VERSION ""

NS_ :

BS_:

BU_: FBD_HL IPB_App1 FBD_HM FBD_HR FBD_Miko FBD_MM FBD_Trunk FBD_VL FBD_VM FBD_VR Diagnosetool_CAN_FD_IPB_41

BO_ 651 StatusBLEDeviceNameFBD_HM: 32 FBD_HM
 SG_ StatusBLEDeviceNameFBD_HM_Charac : 0|8@1+ (1.0,0) [0|252] "" IPB_App1
 SG_ StatusBLEDeviceNameFBD_HM_Char_2 : 8|8@1+ (1.0,0) [0|252] "" IPB_App1
 SG_ StatusBLEDeviceNameFBD_HM_Char_3 : 16|8@1+ (1.0,0) [0|252] "" IPB_App1
 SG_ StatusBLEDeviceNameFBD_HM_Char_4 : 24|8@1+ (1.0,0) [0|252] "" IPB_App1
 SG_ StatusBLEDeviceNameFBD_HM_Char_5 : 32|8@1+ (1.0,0) [0|252] "" IPB_App1
 SG_ StatusBLEDeviceNameFBD_HM_Char_6 : 40|8@1+ (1.0,0) [0|252] "" IPB_App1
 SG_ StatusBLEDeviceNameFBD_HM_Char_7 : 48|8@1+ (1.0,0) [0|252] "" IPB_App1
 SG_ StatusBLEDeviceNameFBD_HM_Char_8 : 56|8@1+ (1.0,0) [0|252] "" IPB_App1
 SG_ StatusBLEDeviceNameFBD_HM_Char_9 : 64|8@1+ (1.0,0) [0|252] "" IPB_App1
 SG_ StatusBLEDeviceNameFBD_HM_Cha_10 : 72|8@1+ (1.0,0) [0|252] "" IPB_App1
 SG_ StatusBLEDeviceNameFBD_HM_Cha_11 : 80|8@1+ (1.0,0) [0|252] "" IPB_App1
 SG_ StatusBLEDeviceNameFBD_HM_Cha_12 : 88|8@1+ (1.0,0) [0|252] "" IPB_App1
 SG_ StatusBLEDeviceNameFBD_HM_Cha_13 : 96|8@1+ (1.0,0) [0|252] "" IPB_App1
 SG_ StatusBLEDeviceNameFBD_HM_Cha_14 : 104|8@1+ (1.0,0) [0|252] "" IPB_App1
 SG_ StatusBLEDeviceNameFBD_HM_Cha_15 : 112|8@1+ (1.0,0) [0|252] "" IPB_App1
 SG_ StatusBLEDeviceNameFBD_HM_Cha_16 : 120|8@1+ (1.0,0) [0|252] "" IPB_App1
 SG_ StatusBLEDeviceNameFBD_HM_Cha_17 : 128|8@1+ (1.0,0) [0|252] "" IPB_App1
 SG_ StatusBLEDeviceNameFBD_HM_Cha_18 : 136|8@1+ (1.0,0) [0|252] "" IPB_App1
 SG_ StatusBLEDeviceNameFBD_HM_Cha_19 : 144|8@1+ (1.0,0) [0|252] "" IPB_App1
 SG_ StatusBLEDeviceNameFBD_HM_Cha_20 : 152|8@1+ (1.0,0) [0|252] "" IPB_App1
 SG_ StatusBLEDeviceNameFBD_HM_Cha_21 : 160|8@1+ (1.0,0) [0|252] "" IPB_App1
 SG_ StatusBLEDeviceNameFBD_HM_Cha_22 : 168|8@1+ (1.0,0) [0|252] "" IPB_App1
 SG_ StatusBLEDeviceNameFBD_HM_Cha_23 : 176|8@1+ (1.0,0) [0|252] "" IPB_App1
 SG_ StatusBLEDeviceNameFBD_HM_Cha_24 : 184|8@1+ (1.0,0) [0|252] "" IPB_App1
 SG_ StatusBLEDeviceNameFBD_HM_Cha_25 : 192|8@1+ (1.0,0) [0|252] "" IPB_App1
 SG_ StatusBLEDeviceNameFBD_HM_Cha_26 : 200|8@1+ (1.0,0) [0|252] "" IPB_App1
 SG_ StatusBLEDeviceNameFBD_HM_Cha_27 : 208|8@1+ (1.0,0) [0|252] "" IPB_App1
 SG_ StatusBLEDeviceNameFBD_HM_Cha_28 : 216|8@1+ (1.0,0) [0|252] "" IPB_App1
 SG_ StatusBLEDeviceNameFBD_HM_Cha_29 : 224|8@1+ (1.0,0) [0|252] "" IPB_App1
 SG_ StatusBLEDeviceNameFBD_HM_Cha_30 : 232|8@1+ (1.0,0) [0|252] "" IPB_App1

BO_ 657 StatusBLEDeviceNameFBD_HR: 32 FBD_HR
 SG_ StatusBLEDeviceNameFBD_HR_Charac : 0|8@1+ (1.0,0) [0|252] "" IPB_App1
 SG_ StatusBLEDeviceNameFBD_HR_Char_2 : 8|8@1+ (1.0,0) [0|252] "" IPB_App1
 SG_ StatusBLEDeviceNameFBD_HR_Char_3 : 16|8@1+ (1.0,0) [0|252] "" IPB_App1
 SG_ StatusBLEDeviceNameFBD_HR_Char_4 : 24|8@1+ (1.0,0) [0|252] "" IPB_App1
 SG_ StatusBLEDeviceNameFBD_HR_Char_5 : 32|8@1+ (1.0,0) [0|252] "" IPB_App1
 SG_ StatusBLEDeviceNameFBD_HR_Char_6 : 40|8@1+ (1.0,0) [0|252] "" IPB_App1
 SG_ StatusBLEDeviceNameFBD_HR_Char_7 : 48|8@1+ (1.0,0) [0|252] "" IPB_App1
 SG_ StatusBLEDeviceNameFBD_HR_Char_8 : 56|8@1+ (1.0,0) [0|252] "" IPB_App1
 SG_ StatusBLEDeviceNameFBD_HR_Char_9 : 64|8@1+ (1.0,0) [0|252] "" IPB_App1
 SG_ StatusBLEDeviceNameFBD_HR_Cha_10 : 72|8@1+ (1.0,0) [0|252] "" IPB_App1
 SG_ StatusBLEDeviceNameFBD_HR_Cha_11 : 80|8@1+ (1.0,0) [0|252] "" IPB_App1
 SG_ StatusBLEDeviceNameFBD_HR_Cha_12 : 88|8@1+ (1.0,0) [0|252] "" IPB_App1
 SG_ StatusBLEDeviceNameFBD_HR_Cha_13 : 96|8@1+ (1.0,0) [0|252] "" IPB_App1
 SG_ StatusBLEDeviceNameFBD_HR_Cha_14 : 104|8@1+ (1.0,0) [0|252] "" IPB_App1
 SG_ StatusBLEDeviceNameFBD_HR_Cha_15 : 112|8@1+ (1.0,0) [0|252] "" IPB_App1
 SG_ StatusBLEDeviceNameFBD_HR_Cha_16 : 120|8@1+ (1.0,0) [0|252] "" IPB_App1
 SG_ StatusBLEDeviceNameFBD_HR_Cha_17 : 128|8@1+ (1.0,0) [0|252] "" IPB_App1
 SG_ StatusBLEDeviceNameFBD_HR_Cha_18 : 136|8@1+ (1.0,0) [0|252] "" IPB_App1
 SG_ StatusBLEDeviceNameFBD_HR_Cha_19 : 144|8@1+ (1.0,0) [0|252] "" IPB_App1
 SG_ StatusBLEDeviceNameFBD_HR_Cha_20 : 152|8@1+ (1.0,0) [0|252] "" IPB_App1
 SG_ StatusBLEDeviceNameFBD_HR_Cha_21 : 160|8@1+ (1.0,0) [0|252] "" IPB_App1
 SG_ StatusBLEDeviceNameFBD_HR_Cha_22 : 168|8@1+ (1.0,0) [0|252] "" IPB_App1
 SG_ StatusBLEDeviceNameFBD_HR_Cha_23 : 176|8@1+ (1.0,0) [0|252] "" IPB_App1
 SG_ StatusBLEDeviceNameFBD_HR_Cha_24 : 184|8@1+ (1.0,0) [0|252] "" IPB_App1
 SG_ StatusBLEDeviceNameFBD_HR_Cha_25 : 192|8@1+ (1.0,0) [0|252] "" IPB_App1
 SG_ StatusBLEDeviceNameFBD_HR_Cha_26 : 200|8@1+ (1.0,0) [0|252] "" IPB_App1
 SG_ StatusBLEDeviceNameFBD_HR_Cha_27 : 208|8@1+ (1.0,0) [0|252] "" IPB_App1
 SG_ StatusBLEDeviceNameFBD_HR_Cha_28 : 216|8@1+ (1.0,0) [0|252] "" IPB_App1
 SG_ StatusBLEDeviceNameFBD_HR_Cha_29 : 224|8@1+ (1.0,0) [0|252] "" IPB_App1
 SG_ StatusBLEDeviceNameFBD_HR_Cha_30 : 232|8@1+ (1.0,0) [0|252] "" IPB_App1

BO_ 652 StatusBLEDeviceNameFBD_Miko: 32 FBD_Miko
 SG_ StatusBLEDeviceNameFBD_Miko_Char : 0|8@1+ (1.0,0) [0|252] "" IPB_App1
 SG_ StatusBLEDeviceNameFBD_Miko_Ch_2 : 8|8@1+ (1.0,0) [0|252] "" IPB_App1
 SG_ StatusBLEDeviceNameFBD_Miko_Ch_3 : 16|8@1+ (1.0,0) [0|252] "" IPB_App1
 SG_ StatusBLEDeviceNameFBD_Miko_Ch_4 : 24|8@1+ (1.0,0) [0|252] "" IPB_App1
 SG_ StatusBLEDeviceNameFBD_Miko_Ch_5 : 32|8@1+ (1.0,0) [0|252] "" IPB_App1
 SG_ StatusBLEDeviceNameFBD_Miko_Ch_6 : 40|8@1+ (1.0,0) [0|252] "" IPB_App1
 SG_ StatusBLEDeviceNameFBD_Miko_Ch_7 : 48|8@1+ (1.0,0) [0|252] "" IPB_App1
 SG_ StatusBLEDeviceNameFBD_Miko_Ch_8 : 56|8@1+ (1.0,0) [0|252] "" IPB_App1
 SG_ StatusBLEDeviceNameFBD_Miko_Ch_9 : 64|8@1+ (1.0,0) [0|252] "" IPB_App1
 SG_ StatusBLEDeviceNameFBD_Miko_C_10 : 72|8@1+ (1.0,0) [0|252] "" IPB_App1
 SG_ StatusBLEDeviceNameFBD_Miko_C_11 : 80|8@1+ (1.0,0) [0|252] "" IPB_App1
 SG_ StatusBLEDeviceNameFBD_Miko_C_12 : 88|8@1+ (1.0,0) [0|252] "" IPB_App1
 SG_ StatusBLEDeviceNameFBD_Miko_C_13 : 96|8@1+ (1.0,0) [0|252] "" IPB_App1
 SG_ StatusBLEDeviceNameFBD_Miko_C_14 : 104|8@1+ (1.0,0) [0|252] "" IPB_App1
 SG_ StatusBLEDeviceNameFBD_Miko_C_15 : 112|8@1+ (1.0,0) [0|252] "" IPB_App1
 SG_ StatusBLEDeviceNameFBD_Miko_C_16 : 120|8@1+ (1.0,0) [0|252] "" IPB_App1
 SG_ StatusBLEDeviceNameFBD_Miko_C_17 : 128|8@1+ (1.0,0) [0|252] "" IPB_App1
 SG_ StatusBLEDeviceNameFBD_Miko_C_18 : 136|8@1+ (1.0,0) [0|252] "" IPB_App1
 SG_ StatusBLEDeviceNameFBD_Miko_C_19 : 144|8@1+ (1.0,0) [0|252] "" IPB_App1
 SG_ StatusBLEDeviceNameFBD_Miko_C_20 : 152|8@1+ (1.0,0) [0|252] "" IPB_App1
 SG_ StatusBLEDeviceNameFBD_Miko_C_21 : 160|8@1+ (1.0,0) [0|252] "" IPB_App1
 SG_ StatusBLEDeviceNameFBD_Miko_C_22 : 168|8@1+ (1.0,0) [0|252] "" IPB_App1
 SG_ StatusBLEDeviceNameFBD_Miko_C_23 : 176|8@1+ (1.0,0) [0|252] "" IPB_App1
 SG_ StatusBLEDeviceNameFBD_Miko_C_24 : 184|8@1+ (1.0,0) [0|252] "" IPB_App1
 SG_ StatusBLEDeviceNameFBD_Miko_C_25 : 192|8@1+ (1.0,0) [0|252] "" IPB_App1
 SG_ StatusBLEDeviceNameFBD_Miko_C_26 : 200|8@1+ (1.0,0) [0|252] "" IPB_App1
 SG_ StatusBLEDeviceNameFBD_Miko_C_27 : 208|8@1+ (1.0,0) [0|252] "" IPB_App1
 SG_ StatusBLEDeviceNameFBD_Miko_C_28 : 216|8@1+ (1.0,0) [0|252] "" IPB_App1
 SG_ StatusBLEDeviceNameFBD_Miko_C_29 : 224|8@1+ (1.0,0) [0|252] "" IPB_App1
 SG_ StatusBLEDeviceNameFBD_Miko_C_30 : 232|8@1+ (1.0,0) [0|252] "" IPB_App1

BO_ 660 StatusBLEDeviceNameFBD_MM: 32 FBD_MM
 SG_ StatusBLEDeviceNameFBD_MM_Addres : 0|16@1+ (1,0) [0|0] "" IPB_App1
 SG_ StatusBLEDeviceNameFBD_MM_Charac : 16|8@1+ (1.0,0) [0|252] "" IPB_App1
 SG_ StatusBLEDeviceNameFBD_MM_Char_2 : 24|8@1+ (1.0,0) [0|252] "" IPB_App1
 SG_ StatusBLEDeviceNameFBD_MM_Char_3 : 32|8@1+ (1.0,0) [0|252] "" IPB_App1
 SG_ StatusBLEDeviceNameFBD_MM_Char_4 : 40|8@1+ (1.0,0) [0|252] "" IPB_App1
 SG_ StatusBLEDeviceNameFBD_MM_Char_5 : 48|8@1+ (1.0,0) [0|252] "" IPB_App1
 SG_ StatusBLEDeviceNameFBD_MM_Char_6 : 56|8@1+ (1.0,0) [0|252] "" IPB_App1
 SG_ StatusBLEDeviceNameFBD_MM_Char_7 : 64|8@1+ (1.0,0) [0|252] "" IPB_App1
 SG_ StatusBLEDeviceNameFBD_MM_Char_8 : 72|8@1+ (1.0,0) [0|252] "" IPB_App1
 SG_ StatusBLEDeviceNameFBD_MM_Char_9 : 80|8@1+ (1.0,0) [0|252] "" IPB_App1
 SG_ StatusBLEDeviceNameFBD_MM_Cha_10 : 88|8@1+ (1.0,0) [0|252] "" IPB_App1
 SG_ StatusBLEDeviceNameFBD_MM_Cha_11 : 96|8@1+ (1.0,0) [0|252] "" IPB_App1
 SG_ StatusBLEDeviceNameFBD_MM_Cha_12 : 104|8@1+ (1.0,0) [0|252] "" IPB_App1
 SG_ StatusBLEDeviceNameFBD_MM_Cha_13 : 112|8@1+ (1.0,0) [0|252] "" IPB_App1
 SG_ StatusBLEDeviceNameFBD_MM_Cha_14 : 120|8@1+ (1.0,0) [0|252] "" IPB_App1
 SG_ StatusBLEDeviceNameFBD_MM_Cha_15 : 128|8@1+ (1.0,0) [0|252] "" IPB_App1
 SG_ StatusBLEDeviceNameFBD_MM_Cha_16 : 136|8@1+ (1.0,0) [0|252] "" IPB_App1
 SG_ StatusBLEDeviceNameFBD_MM_Cha_17 : 144|8@1+ (1.0,0) [0|252] "" IPB_App1
 SG_ StatusBLEDeviceNameFBD_MM_Cha_18 : 152|8@1+ (1.0,0) [0|252] "" IPB_App1
 SG_ StatusBLEDeviceNameFBD_MM_Cha_19 : 160|8@1+ (1.0,0) [0|252] "" IPB_App1
 SG_ StatusBLEDeviceNameFBD_MM_Cha_20 : 168|8@1+ (1.0,0) [0|252] "" IPB_App1
 SG_ StatusBLEDeviceNameFBD_MM_Cha_21 : 176|8@1+ (1.0,0) [0|252] "" IPB_App1
 SG_ StatusBLEDeviceNameFBD_MM_Cha_22 : 184|8@1+ (1.0,0) [0|252] "" IPB_App1
 SG_ StatusBLEDeviceNameFBD_MM_Cha_23 : 192|8@1+ (1.0,0) [0|252] "" IPB_App1
 SG_ StatusBLEDeviceNameFBD_MM_Cha_24 : 200|8@1+ (1.0,0) [0|252] "" IPB_App1
 SG_ StatusBLEDeviceNameFBD_MM_Cha_25 : 208|8@1+ (1.0,0) [0|252] "" IPB_App1
 SG_ StatusBLEDeviceNameFBD_MM_Cha_26 : 216|8@1+ (1.0,0) [0|252] "" IPB_App1
 SG_ StatusBLEDeviceNameFBD_MM_Cha_27 : 224|8@1+ (1.0,0) [0|252] "" IPB_App1
 SG_ StatusBLEDeviceNameFBD_MM_Cha_28 : 232|8@1+ (1.0,0) [0|252] "" IPB_App1
 SG_ StatusBLEDeviceNameFBD_MM_Cha_29 : 240|8@1+ (1.0,0) [0|252] "" IPB_App1
 SG_ StatusBLEDeviceNameFBD_MM_Cha_30 : 248|8@1+ (1.0,0) [0|252] "" IPB_App1

BO_ 653 StatusBLEDeviceNameFBD_Trunk: 32 FBD_Trunk
 SG_ StatusBLEDeviceNameFBD_Trunk_Cha : 0|8@1+ (1.0,0) [0|252] "" IPB_App1
 SG_ StatusBLEDeviceNameFBD_Trunk_C_2 : 8|8@1+ (1.0,0) [0|252] "" IPB_App1
 SG_ StatusBLEDeviceNameFBD_Trunk_C_3 : 16|8@1+ (1.0,0) [0|252] "" IPB_App1
 SG_ StatusBLEDeviceNameFBD_Trunk_C_4 : 24|8@1+ (1.0,0) [0|252] "" IPB_App1
 SG_ StatusBLEDeviceNameFBD_Trunk_C_5 : 32|8@1+ (1.0,0) [0|252] "" IPB_App1
 SG_ StatusBLEDeviceNameFBD_Trunk_C_6 : 40|8@1+ (1.0,0) [0|252] "" IPB_App1
 SG_ StatusBLEDeviceNameFBD_Trunk_C_7 : 48|8@1+ (1.0,0) [0|252] "" IPB_App1
 SG_ StatusBLEDeviceNameFBD_Trunk_C_8 : 56|8@1+ (1.0,0) [0|252] "" IPB_App1
 SG_ StatusBLEDeviceNameFBD_Trunk_C_9 : 64|8@1+ (1.0,0) [0|252] "" IPB_App1
 SG_ StatusBLEDeviceNameFBD_Trunk__10 : 72|8@1+ (1.0,0) [0|252] "" IPB_App1
 SG_ StatusBLEDeviceNameFBD_Trunk__11 : 80|8@1+ (1.0,0) [0|252] "" IPB_App1
 SG_ StatusBLEDeviceNameFBD_Trunk__12 : 88|8@1+ (1.0,0) [0|252] "" IPB_App1
 SG_ StatusBLEDeviceNameFBD_Trunk__13 : 96|8@1+ (1.0,0) [0|252] "" IPB_App1
 SG_ StatusBLEDeviceNameFBD_Trunk__14 : 104|8@1+ (1.0,0) [0|252] "" IPB_App1
 SG_ StatusBLEDeviceNameFBD_Trunk__15 : 112|8@1+ (1.0,0) [0|252] "" IPB_App1
 SG_ StatusBLEDeviceNameFBD_Trunk__16 : 120|8@1+ (1.0,0) [0|252] "" IPB_App1
 SG_ StatusBLEDeviceNameFBD_Trunk__17 : 128|8@1+ (1.0,0) [0|252] "" IPB_App1
 SG_ StatusBLEDeviceNameFBD_Trunk__18 : 136|8@1+ (1.0,0) [0|252] "" IPB_App1
 SG_ StatusBLEDeviceNameFBD_Trunk__19 : 144|8@1+ (1.0,0) [0|252] "" IPB_App1
 SG_ StatusBLEDeviceNameFBD_Trunk__20 : 152|8@1+ (1.0,0) [0|252] "" IPB_App1
 SG_ StatusBLEDeviceNameFBD_Trunk__21 : 160|8@1+ (1.0,0) [0|252] "" IPB_App1
 SG_ StatusBLEDeviceNameFBD_Trunk__22 : 168|8@1+ (1.0,0) [0|252] "" IPB_App1
 SG_ StatusBLEDeviceNameFBD_Trunk__23 : 176|8@1+ (1.0,0) [0|252] "" IPB_App1
 SG_ StatusBLEDeviceNameFBD_Trunk__24 : 184|8@1+ (1.0,0) [0|252] "" IPB_App1
 SG_ StatusBLEDeviceNameFBD_Trunk__25 : 192|8@1+ (1.0,0) [0|252] "" IPB_App1
 SG_ StatusBLEDeviceNameFBD_Trunk__26 : 200|8@1+ (1.0,0) [0|252] "" IPB_App1
 SG_ StatusBLEDeviceNameFBD_Trunk__27 : 208|8@1+ (1.0,0) [0|252] "" IPB_App1
 SG_ StatusBLEDeviceNameFBD_Trunk__28 : 216|8@1+ (1.0,0) [0|252] "" IPB_App1
 SG_ StatusBLEDeviceNameFBD_Trunk__29 : 224|8@1+ (1.0,0) [0|252] "" IPB_App1
 SG_ StatusBLEDeviceNameFBD_Trunk__30 : 232|8@1+ (1.0,0) [0|252] "" IPB_App1

BO_ 654 StatusBLEDeviceNameFBD_VL: 32 FBD_VL
 SG_ StatusBLEDeviceNameFBD_VL_Charac : 0|8@1+ (1.0,0) [0|252] "" IPB_App1
 SG_ StatusBLEDeviceNameFBD_VL_Char_2 : 8|8@1+ (1.0,0) [0|252] "" IPB_App1
 SG_ StatusBLEDeviceNameFBD_VL_Char_3 : 16|8@1+ (1.0,0) [0|252] "" IPB_App1
 SG_ StatusBLEDeviceNameFBD_VL_Char_4 : 24|8@1+ (1.0,0) [0|252] "" IPB_App1
 SG_ StatusBLEDeviceNameFBD_VL_Char_5 : 32|8@1+ (1.0,0) [0|252] "" IPB_App1
 SG_ StatusBLEDeviceNameFBD_VL_Char_6 : 40|8@1+ (1.0,0) [0|252] "" IPB_App1
 SG_ StatusBLEDeviceNameFBD_VL_Char_7 : 48|8@1+ (1.0,0) [0|252] "" IPB_App1
 SG_ StatusBLEDeviceNameFBD_VL_Char_8 : 56|8@1+ (1.0,0) [0|252] "" IPB_App1
 SG_ StatusBLEDeviceNameFBD_VL_Char_9 : 64|8@1+ (1.0,0) [0|252] "" IPB_App1
 SG_ StatusBLEDeviceNameFBD_VL_Cha_10 : 72|8@1+ (1.0,0) [0|252] "" IPB_App1
 SG_ StatusBLEDeviceNameFBD_VL_Cha_11 : 80|8@1+ (1.0,0) [0|252] "" IPB_App1
 SG_ StatusBLEDeviceNameFBD_VL_Cha_12 : 88|8@1+ (1.0,0) [0|252] "" IPB_App1
 SG_ StatusBLEDeviceNameFBD_VL_Cha_13 : 96|8@1+ (1.0,0) [0|252] "" IPB_App1
 SG_ StatusBLEDeviceNameFBD_VL_Cha_14 : 104|8@1+ (1.0,0) [0|252] "" IPB_App1
 SG_ StatusBLEDeviceNameFBD_VL_Cha_15 : 112|8@1+ (1.0,0) [0|252] "" IPB_App1
 SG_ StatusBLEDeviceNameFBD_VL_Cha_16 : 120|8@1+ (1.0,0) [0|252] "" IPB_App1
 SG_ StatusBLEDeviceNameFBD_VL_Cha_17 : 128|8@1+ (1.0,0) [0|252] "" IPB_App1
 SG_ StatusBLEDeviceNameFBD_VL_Cha_18 : 136|8@1+ (1.0,0) [0|252] "" IPB_App1
 SG_ StatusBLEDeviceNameFBD_VL_Cha_19 : 144|8@1+ (1.0,0) [0|252] "" IPB_App1
 SG_ StatusBLEDeviceNameFBD_VL_Cha_20 : 152|8@1+ (1.0,0) [0|252] "" IPB_App1
 SG_ StatusBLEDeviceNameFBD_VL_Cha_21 : 160|8@1+ (1.0,0) [0|252] "" IPB_App1
 SG_ StatusBLEDeviceNameFBD_VL_Cha_22 : 168|8@1+ (1.0,0) [0|252] "" IPB_App1
 SG_ StatusBLEDeviceNameFBD_VL_Cha_23 : 176|8@1+ (1.0,0) [0|252] "" IPB_App1
 SG_ StatusBLEDeviceNameFBD_VL_Cha_24 : 184|8@1+ (1.0,0) [0|252] "" IPB_App1
 SG_ StatusBLEDeviceNameFBD_VL_Cha_25 : 192|8@1+ (1.0,0) [0|252] "" IPB_App1
 SG_ StatusBLEDeviceNameFBD_VL_Cha_26 : 200|8@1+ (1.0,0) [0|252] "" IPB_App1
 SG_ StatusBLEDeviceNameFBD_VL_Cha_27 : 208|8@1+ (1.0,0) [0|252] "" IPB_App1
 SG_ StatusBLEDeviceNameFBD_VL_Cha_28 : 216|8@1+ (1.0,0) [0|252] "" IPB_App1
 SG_ StatusBLEDeviceNameFBD_VL_Cha_29 : 224|8@1+ (1.0,0) [0|252] "" IPB_App1
 SG_ StatusBLEDeviceNameFBD_VL_Cha_30 : 232|8@1+ (1.0,0) [0|252] "" IPB_App1

BO_ 650 StatusBLEDeviceNameFBD_VM: 32 FBD_VM
 SG_ StatusBLEDeviceNameFBD_VM_Charac : 0|8@1+ (1.0,0) [0|252] "" IPB_App1
 SG_ StatusBLEDeviceNameFBD_VM_Char_2 : 8|8@1+ (1.0,0) [0|252] "" IPB_App1
 SG_ StatusBLEDeviceNameFBD_VM_Char_3 : 16|8@1+ (1.0,0) [0|252] "" IPB_App1
 SG_ StatusBLEDeviceNameFBD_VM_Char_4 : 24|8@1+ (1.0,0) [0|252] "" IPB_App1
 SG_ StatusBLEDeviceNameFBD_VM_Char_5 : 32|8@1+ (1.0,0) [0|252] "" IPB_App1
 SG_ StatusBLEDeviceNameFBD_VM_Char_6 : 40|8@1+ (1.0,0) [0|252] "" IPB_App1
 SG_ StatusBLEDeviceNameFBD_VM_Char_7 : 48|8@1+ (1.0,0) [0|252] "" IPB_App1
 SG_ StatusBLEDeviceNameFBD_VM_Char_8 : 56|8@1+ (1.0,0) [0|252] "" IPB_App1
 SG_ StatusBLEDeviceNameFBD_VM_Char_9 : 64|8@1+ (1.0,0) [0|252] "" IPB_App1
 SG_ StatusBLEDeviceNameFBD_VM_Cha_10 : 72|8@1+ (1.0,0) [0|252] "" IPB_App1
 SG_ StatusBLEDeviceNameFBD_VM_Cha_11 : 80|8@1+ (1.0,0) [0|252] "" IPB_App1
 SG_ StatusBLEDeviceNameFBD_VM_Cha_12 : 88|8@1+ (1.0,0) [0|252] "" IPB_App1
 SG_ StatusBLEDeviceNameFBD_VM_Cha_13 : 96|8@1+ (1.0,0) [0|252] "" IPB_App1
 SG_ StatusBLEDeviceNameFBD_VM_Cha_14 : 104|8@1+ (1.0,0) [0|252] "" IPB_App1
 SG_ StatusBLEDeviceNameFBD_VM_Cha_15 : 112|8@1+ (1.0,0) [0|252] "" IPB_App1
 SG_ StatusBLEDeviceNameFBD_VM_Cha_16 : 120|8@1+ (1.0,0) [0|252] "" IPB_App1
 SG_ StatusBLEDeviceNameFBD_VM_Cha_17 : 128|8@1+ (1.0,0) [0|252] "" IPB_App1
 SG_ StatusBLEDeviceNameFBD_VM_Cha_18 : 136|8@1+ (1.0,0) [0|252] "" IPB_App1
 SG_ StatusBLEDeviceNameFBD_VM_Cha_19 : 144|8@1+ (1.0,0) [0|252] "" IPB_App1
 SG_ StatusBLEDeviceNameFBD_VM_Cha_20 : 152|8@1+ (1.0,0) [0|252] "" IPB_App1
 SG_ StatusBLEDeviceNameFBD_VM_Cha_21 : 160|8@1+ (1.0,0) [0|252] "" IPB_App1
 SG_ StatusBLEDeviceNameFBD_VM_Cha_22 : 168|8@1+ (1.0,0) [0|252] "" IPB_App1
 SG_ StatusBLEDeviceNameFBD_VM_Cha_23 : 176|8@1+ (1.0,0) [0|252] "" IPB_App1
 SG_ StatusBLEDeviceNameFBD_VM_Cha_24 : 184|8@1+ (1.0,0) [0|252] "" IPB_App1
 SG_ StatusBLEDeviceNameFBD_VM_Cha_25 : 192|8@1+ (1.0,0) [0|252] "" IPB_App1
 SG_ StatusBLEDeviceNameFBD_VM_Cha_26 : 200|8@1+ (1.0,0) [0|252] "" IPB_App1
 SG_ StatusBLEDeviceNameFBD_VM_Cha_27 : 208|8@1+ (1.0,0) [0|252] "" IPB_App1
 SG_ StatusBLEDeviceNameFBD_VM_Cha_28 : 216|8@1+ (1.0,0) [0|252] "" IPB_App1
 SG_ StatusBLEDeviceNameFBD_VM_Cha_29 : 224|8@1+ (1.0,0) [0|252] "" IPB_App1
 SG_ StatusBLEDeviceNameFBD_VM_Cha_30 : 232|8@1+ (1.0,0) [0|252] "" IPB_App1

BO_ 655 StatusBLEDeviceNameFBD_VR: 32 FBD_VR
 SG_ StatusBLEDeviceNameFBD_VR_Charac : 0|8@1+ (1.0,0) [0|252] "" IPB_App1
 SG_ StatusBLEDeviceNameFBD_VR_Char_2 : 8|8@1+ (1.0,0) [0|252] "" IPB_App1
 SG_ StatusBLEDeviceNameFBD_VR_Char_3 : 16|8@1+ (1.0,0) [0|252] "" IPB_App1
 SG_ StatusBLEDeviceNameFBD_VR_Char_4 : 24|8@1+ (1.0,0) [0|252] "" IPB_App1
 SG_ StatusBLEDeviceNameFBD_VR_Char_5 : 32|8@1+ (1.0,0) [0|252] "" IPB_App1
 SG_ StatusBLEDeviceNameFBD_VR_Char_6 : 40|8@1+ (1.0,0) [0|252] "" IPB_App1
 SG_ StatusBLEDeviceNameFBD_VR_Char_7 : 48|8@1+ (1.0,0) [0|252] "" IPB_App1
 SG_ StatusBLEDeviceNameFBD_VR_Char_8 : 56|8@1+ (1.0,0) [0|252] "" IPB_App1
 SG_ StatusBLEDeviceNameFBD_VR_Char_9 : 64|8@1+ (1.0,0) [0|252] "" IPB_App1
 SG_ StatusBLEDeviceNameFBD_VR_Cha_10 : 72|8@1+ (1.0,0) [0|252] "" IPB_App1
 SG_ StatusBLEDeviceNameFBD_VR_Cha_11 : 80|8@1+ (1.0,0) [0|252] "" IPB_App1
 SG_ StatusBLEDeviceNameFBD_VR_Cha_12 : 88|8@1+ (1.0,0) [0|252] "" IPB_App1
 SG_ StatusBLEDeviceNameFBD_VR_Cha_13 : 96|8@1+ (1.0,0) [0|252] "" IPB_App1
 SG_ StatusBLEDeviceNameFBD_VR_Cha_14 : 104|8@1+ (1.0,0) [0|252] "" IPB_App1
 SG_ StatusBLEDeviceNameFBD_VR_Cha_15 : 112|8@1+ (1.0,0) [0|252] "" IPB_App1
 SG_ StatusBLEDeviceNameFBD_VR_Cha_16 : 120|8@1+ (1.0,0) [0|252] "" IPB_App1
 SG_ StatusBLEDeviceNameFBD_VR_Cha_17 : 128|8@1+ (1.0,0) [0|252] "" IPB_App1
 SG_ StatusBLEDeviceNameFBD_VR_Cha_18 : 136|8@1+ (1.0,0) [0|252] "" IPB_App1
 SG_ StatusBLEDeviceNameFBD_VR_Cha_19 : 144|8@1+ (1.0,0) [0|252] "" IPB_App1
 SG_ StatusBLEDeviceNameFBD_VR_Cha_20 : 152|8@1+ (1.0,0) [0|252] "" IPB_App1
 SG_ StatusBLEDeviceNameFBD_VR_Cha_21 : 160|8@1+ (1.0,0) [0|252] "" IPB_App1
 SG_ StatusBLEDeviceNameFBD_VR_Cha_22 : 168|8@1+ (1.0,0) [0|252] "" IPB_App1
 SG_ StatusBLEDeviceNameFBD_VR_Cha_23 : 176|8@1+ (1.0,0) [0|252] "" IPB_App1
 SG_ StatusBLEDeviceNameFBD_VR_Cha_24 : 184|8@1+ (1.0,0) [0|252] "" IPB_App1
 SG_ StatusBLEDeviceNameFBD_VR_Cha_25 : 192|8@1+ (1.0,0) [0|252] "" IPB_App1
 SG_ StatusBLEDeviceNameFBD_VR_Cha_26 : 200|8@1+ (1.0,0) [0|252] "" IPB_App1
 SG_ StatusBLEDeviceNameFBD_VR_Cha_27 : 208|8@1+ (1.0,0) [0|252] "" IPB_App1
 SG_ StatusBLEDeviceNameFBD_VR_Cha_28 : 216|8@1+ (1.0,0) [0|252] "" IPB_App1
 SG_ StatusBLEDeviceNameFBD_VR_Cha_29 : 224|8@1+ (1.0,0) [0|252] "" IPB_App1
 SG_ StatusBLEDeviceNameFBD_VR_Cha_30 : 232|8@1+ (1.0,0) [0|252] "" IPB_App1

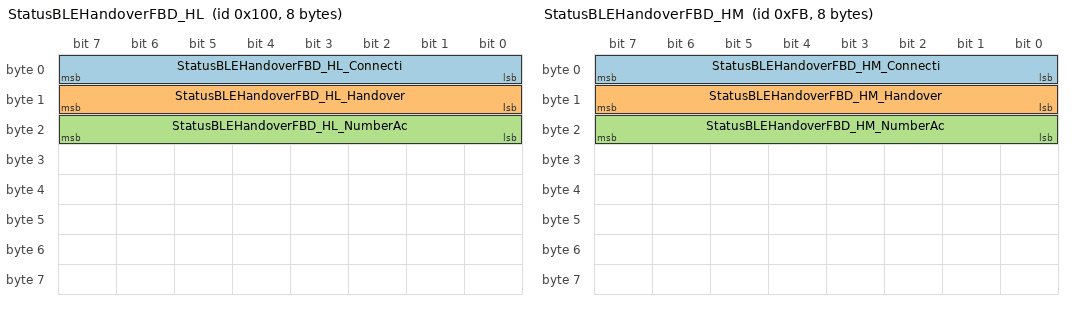
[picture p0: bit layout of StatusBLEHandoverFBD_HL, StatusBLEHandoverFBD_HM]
BO_ 256 StatusBLEHandoverFBD_HL: 8 FBD_HL
 SG_ StatusBLEHandoverFBD_HL_Connecti : 0|8@1+ (1.0,0) [0|252] "" FBD_HM,FBD_HR,FBD_MM,FBD_Miko,FBD_Trunk,FBD_VL,FBD_VM,FBD_VR,IPB_App1
 SG_ StatusBLEHandoverFBD_HL_Handover : 8|8@1+ (1,0) [0|0] "" FBD_HM,FBD_HR,FBD_MM,FBD_Miko,FBD_Trunk,FBD_VL,FBD_VM,FBD_VR,IPB_App1
 SG_ StatusBLEHandoverFBD_HL_NumberAc : 16|8@1+ (1.0,0) [0|252] "" FBD_HM,FBD_HR,FBD_MM,FBD_Miko,FBD_Trunk,FBD_VL,FBD_VM,FBD_VR,IPB_App1

BO_ 251 StatusBLEHandoverFBD_HM: 8 FBD_HM
 SG_ StatusBLEHandoverFBD_HM_Connecti : 0|8@1+ (1.0,0) [0|252] "" FBD_HL,FBD_HR,FBD_MM,FBD_Miko,FBD_Trunk,FBD_VL,FBD_VM,FBD_VR,IPB_App1
 SG_ StatusBLEHandoverFBD_HM_Handover : 8|8@1+ (1,0) [0|0] "" FBD_HL,FBD_HR,FBD_MM,FBD_Miko,FBD_Trunk,FBD_VL,FBD_VM,FBD_VR,IPB_App1
 SG_ StatusBLEHandoverFBD_HM_NumberAc : 16|8@1+ (1.0,0) [0|252] "" FBD_HL,FBD_HR,FBD_MM,FBD_Miko,FBD_Trunk,FBD_VL,FBD_VM,FBD_VR,IPB_App1

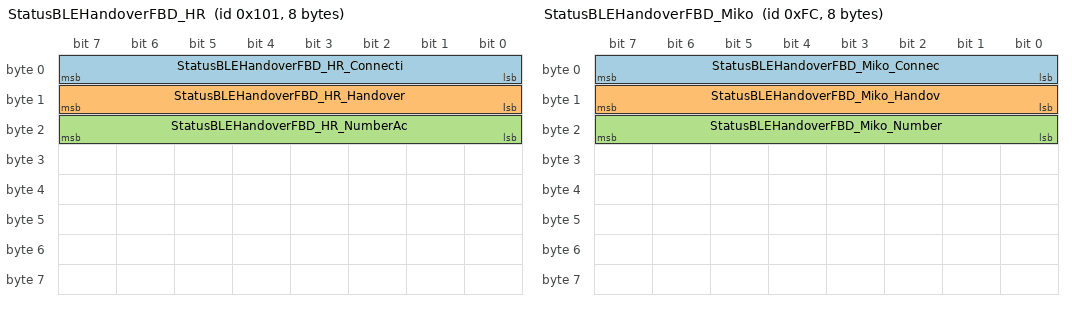
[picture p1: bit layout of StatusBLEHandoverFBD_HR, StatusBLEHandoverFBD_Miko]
BO_ 257 StatusBLEHandoverFBD_HR: 8 FBD_HR
 SG_ StatusBLEHandoverFBD_HR_Connecti : 0|8@1+ (1.0,0) [0|252] "" FBD_HL,FBD_HM,FBD_MM,FBD_Miko,FBD_Trunk,FBD_VL,FBD_VM,FBD_VR,IPB_App1
 SG_ StatusBLEHandoverFBD_HR_Handover : 8|8@1+ (1,0) [0|0] "" FBD_HL,FBD_HM,FBD_MM,FBD_Miko,FBD_Trunk,FBD_VL,FBD_VM,FBD_VR,IPB_App1
 SG_ StatusBLEHandoverFBD_HR_NumberAc : 16|8@1+ (1.0,0) [0|252] "" FBD_HL,FBD_HM,FBD_MM,FBD_Miko,FBD_Trunk,FBD_VL,FBD_VM,FBD_VR,IPB_App1

BO_ 252 StatusBLEHandoverFBD_Miko: 8 FBD_Miko
 SG_ StatusBLEHandoverFBD_Miko_Connec : 0|8@1+ (1.0,0) [0|252] "" FBD_HL,FBD_HM,FBD_HR,FBD_MM,FBD_Trunk,FBD_VL,FBD_VM,FBD_VR,IPB_App1
 SG_ StatusBLEHandoverFBD_Miko_Handov : 8|8@1+ (1,0) [0|0] "" FBD_HL,FBD_HM,FBD_HR,FBD_MM,FBD_Trunk,FBD_VL,FBD_VM,FBD_VR,IPB_App1
 SG_ StatusBLEHandoverFBD_Miko_Number : 16|8@1+ (1.0,0) [0|252] "" FBD_HL,FBD_HM,FBD_HR,FBD_MM,FBD_Trunk,FBD_VL,FBD_VM,FBD_VR,IPB_App1

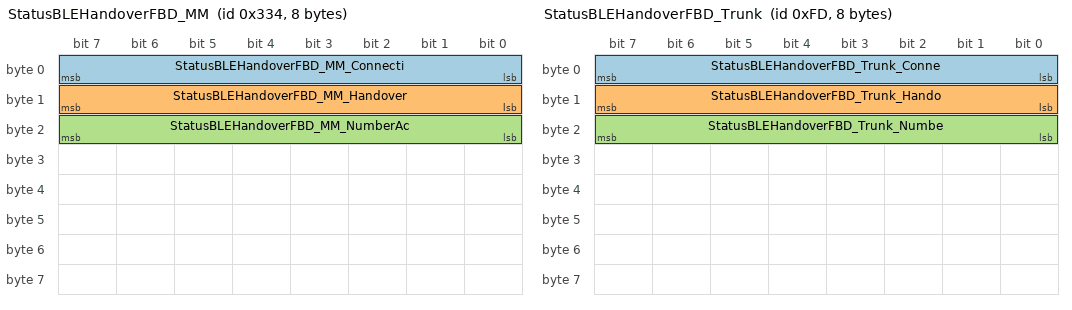
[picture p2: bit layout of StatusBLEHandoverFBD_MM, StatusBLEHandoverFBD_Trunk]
BO_ 820 StatusBLEHandoverFBD_MM: 8 FBD_MM
 SG_ StatusBLEHandoverFBD_MM_Connecti : 0|8@1+ (1.0,0) [0|252] "" FBD_HL,FBD_HM,FBD_HR,FBD_Miko,FBD_Trunk,FBD_VL,FBD_VM,FBD_VR,IPB_App1
 SG_ StatusBLEHandoverFBD_MM_Handover : 8|8@1+ (1,0) [0|0] "" FBD_HL,FBD_HM,FBD_HR,FBD_Miko,FBD_Trunk,FBD_VL,FBD_VM,FBD_VR,IPB_App1
 SG_ StatusBLEHandoverFBD_MM_NumberAc : 16|8@1+ (1.0,0) [0|252] "" FBD_HL,FBD_HM,FBD_HR,FBD_Miko,FBD_Trunk,FBD_VL,FBD_VM,FBD_VR,IPB_App1

BO_ 253 StatusBLEHandoverFBD_Trunk: 8 FBD_Trunk
 SG_ StatusBLEHandoverFBD_Trunk_Conne : 0|8@1+ (1.0,0) [0|252] "" FBD_HL,FBD_HM,FBD_HR,FBD_MM,FBD_Miko,FBD_VL,FBD_VM,FBD_VR,IPB_App1
 SG_ StatusBLEHandoverFBD_Trunk_Hando : 8|8@1+ (1,0) [0|0] "" FBD_HL,FBD_HM,FBD_HR,FBD_MM,FBD_Miko,FBD_VL,FBD_VM,FBD_VR,IPB_App1
 SG_ StatusBLEHandoverFBD_Trunk_Numbe : 16|8@1+ (1.0,0) [0|252] "" FBD_HL,FBD_HM,FBD_HR,FBD_MM,FBD_Miko,FBD_VL,FBD_VM,FBD_VR,IPB_App1

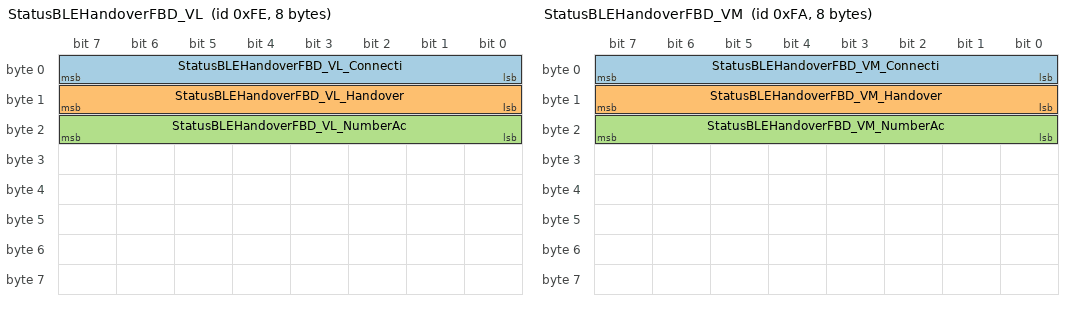
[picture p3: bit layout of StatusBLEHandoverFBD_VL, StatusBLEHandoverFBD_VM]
BO_ 254 StatusBLEHandoverFBD_VL: 8 FBD_VL
 SG_ StatusBLEHandoverFBD_VL_Connecti : 0|8@1+ (1.0,0) [0|252] "" FBD_HL,FBD_HM,FBD_HR,FBD_MM,FBD_Miko,FBD_Trunk,FBD_VM,FBD_VR,IPB_App1
 SG_ StatusBLEHandoverFBD_VL_Handover : 8|8@1+ (1,0) [0|0] "" FBD_HL,FBD_HM,FBD_HR,FBD_MM,FBD_Miko,FBD_Trunk,FBD_VM,FBD_VR,IPB_App1
 SG_ StatusBLEHandoverFBD_VL_NumberAc : 16|8@1+ (1.0,0) [0|252] "" FBD_HL,FBD_HM,FBD_HR,FBD_MM,FBD_Miko,FBD_Trunk,FBD_VM,FBD_VR,IPB_App1

BO_ 250 StatusBLEHandoverFBD_VM: 8 FBD_VM
 SG_ StatusBLEHandoverFBD_VM_Connecti : 0|8@1+ (1.0,0) [0|252] "" FBD_HL,FBD_HM,FBD_HR,FBD_MM,FBD_Miko,FBD_Trunk,FBD_VL,FBD_VR,IPB_App1
 SG_ StatusBLEHandoverFBD_VM_Handover : 8|8@1+ (1,0) [0|0] "" FBD_HL,FBD_HM,FBD_HR,FBD_MM,FBD_Miko,FBD_Trunk,FBD_VL,FBD_VR,IPB_App1
 SG_ StatusBLEHandoverFBD_VM_NumberAc : 16|8@1+ (1.0,0) [0|252] "" FBD_HL,FBD_HM,FBD_HR,FBD_MM,FBD_Miko,FBD_Trunk,FBD_VL,FBD_VR,IPB_App1

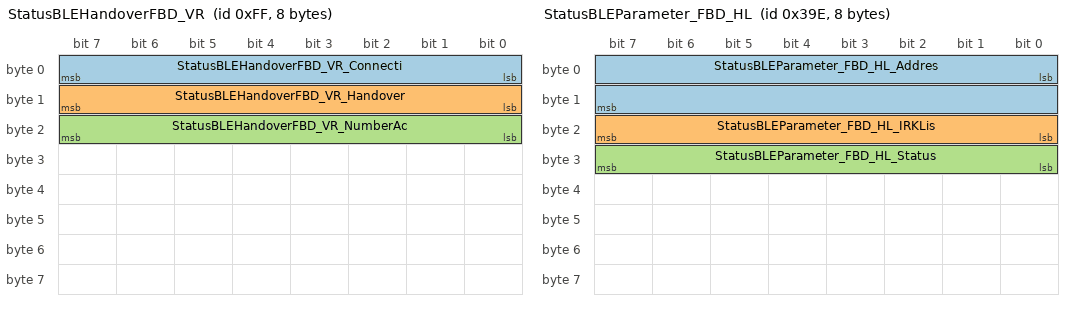
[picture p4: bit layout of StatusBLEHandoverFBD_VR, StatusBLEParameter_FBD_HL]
BO_ 255 StatusBLEHandoverFBD_VR: 8 FBD_VR
 SG_ StatusBLEHandoverFBD_VR_Connecti : 0|8@1+ (1.0,0) [0|252] "" FBD_HL,FBD_HM,FBD_HR,FBD_MM,FBD_Miko,FBD_Trunk,FBD_VL,FBD_VM,IPB_App1
 SG_ StatusBLEHandoverFBD_VR_Handover : 8|8@1+ (1,0) [0|0] "" FBD_HL,FBD_HM,FBD_HR,FBD_MM,FBD_Miko,FBD_Trunk,FBD_VL,FBD_VM,IPB_App1
 SG_ StatusBLEHandoverFBD_VR_NumberAc : 16|8@1+ (1.0,0) [0|252] "" FBD_HL,FBD_HM,FBD_HR,FBD_MM,FBD_Miko,FBD_Trunk,FBD_VL,FBD_VM,IPB_App1

BO_ 926 StatusBLEParameter_FBD_HL: 8 FBD_HL
 SG_ StatusBLEParameter_FBD_HL_Addres : 0|16@1+ (1,0) [0|0] "" FBD_HM,FBD_HR,FBD_MM,FBD_Miko,FBD_Trunk,FBD_VL,FBD_VM,FBD_VR
 SG_ StatusBLEParameter_FBD_HL_IRKLis : 16|8@1+ (1.0,0) [0|252] "" FBD_HM,FBD_HR,FBD_MM,FBD_Miko,FBD_Trunk,FBD_VL,FBD_VM,FBD_VR
 SG_ StatusBLEParameter_FBD_HL_Status : 24|8@1+ (1.0,0) [0|255] "" FBD_HM,FBD_HR,FBD_MM,FBD_Miko,FBD_Trunk,FBD_VL,FBD_VM,FBD_VR

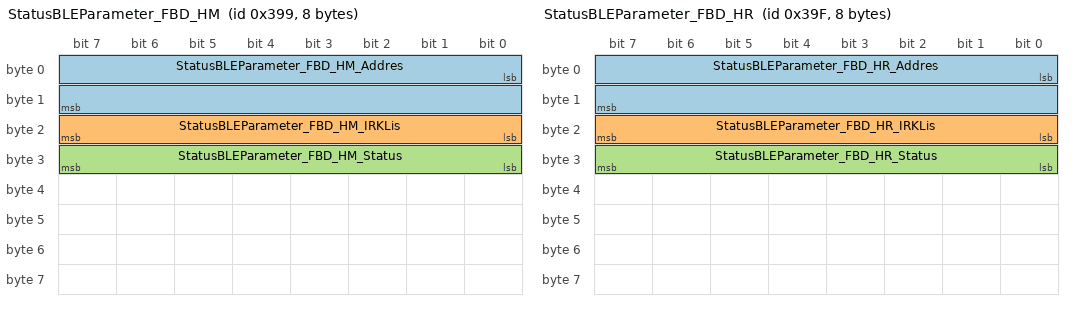
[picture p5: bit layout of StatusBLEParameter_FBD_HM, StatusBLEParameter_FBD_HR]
BO_ 921 StatusBLEParameter_FBD_HM: 8 FBD_HM
 SG_ StatusBLEParameter_FBD_HM_Addres : 0|16@1+ (1,0) [0|0] "" FBD_HL,FBD_HR,FBD_MM,FBD_Miko,FBD_Trunk,FBD_VL,FBD_VM,FBD_VR
 SG_ StatusBLEParameter_FBD_HM_IRKLis : 16|8@1+ (1.0,0) [0|252] "" FBD_HL,FBD_HR,FBD_MM,FBD_Miko,FBD_Trunk,FBD_VL,FBD_VM,FBD_VR
 SG_ StatusBLEParameter_FBD_HM_Status : 24|8@1+ (1.0,0) [0|255] "" FBD_HL,FBD_HR,FBD_MM,FBD_Miko,FBD_Trunk,FBD_VL,FBD_VM,FBD_VR

BO_ 927 StatusBLEParameter_FBD_HR: 8 FBD_HR
 SG_ StatusBLEParameter_FBD_HR_Addres : 0|16@1+ (1,0) [0|0] "" FBD_HL,FBD_HM,FBD_MM,FBD_Miko,FBD_Trunk,FBD_VL,FBD_VM,FBD_VR
 SG_ StatusBLEParameter_FBD_HR_IRKLis : 16|8@1+ (1.0,0) [0|252] "" FBD_HL,FBD_HM,FBD_MM,FBD_Miko,FBD_Trunk,FBD_VL,FBD_VM,FBD_VR
 SG_ StatusBLEParameter_FBD_HR_Status : 24|8@1+ (1.0,0) [0|255] "" FBD_HL,FBD_HM,FBD_MM,FBD_Miko,FBD_Trunk,FBD_VL,FBD_VM,FBD_VR

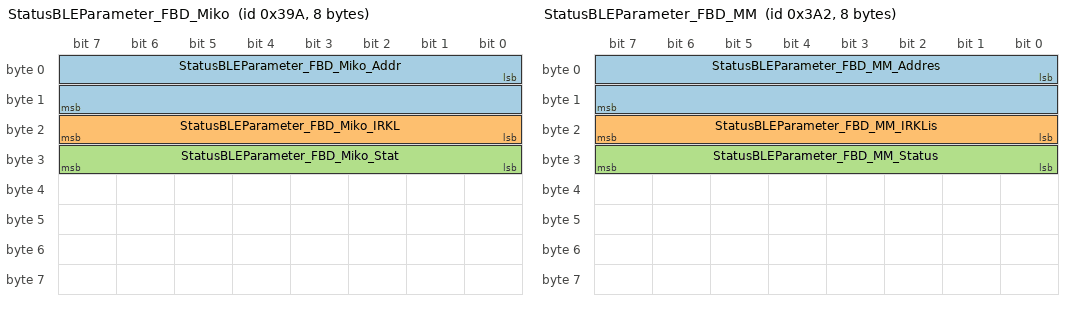
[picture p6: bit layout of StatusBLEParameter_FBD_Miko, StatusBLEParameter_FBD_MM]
BO_ 922 StatusBLEParameter_FBD_Miko: 8 FBD_Miko
 SG_ StatusBLEParameter_FBD_Miko_Addr : 0|16@1+ (1,0) [0|0] "" FBD_HL,FBD_HM,FBD_HR,FBD_MM,FBD_Trunk,FBD_VL,FBD_VM,FBD_VR
 SG_ StatusBLEParameter_FBD_Miko_IRKL : 16|8@1+ (1.0,0) [0|252] "" FBD_HL,FBD_HM,FBD_HR,FBD_MM,FBD_Trunk,FBD_VL,FBD_VM,FBD_VR
 SG_ StatusBLEParameter_FBD_Miko_Stat : 24|8@1+ (1.0,0) [0|255] "" FBD_HL,FBD_HM,FBD_HR,FBD_MM,FBD_Trunk,FBD_VL,FBD_VM,FBD_VR

BO_ 930 StatusBLEParameter_FBD_MM: 8 FBD_MM
 SG_ StatusBLEParameter_FBD_MM_Addres : 0|16@1+ (1,0) [0|0] "" FBD_HL,FBD_HM,FBD_HR,FBD_Miko,FBD_Trunk,FBD_VL,FBD_VM,FBD_VR
 SG_ StatusBLEParameter_FBD_MM_IRKLis : 16|8@1+ (1.0,0) [0|252] "" FBD_HL,FBD_HM,FBD_HR,FBD_Miko,FBD_Trunk,FBD_VL,FBD_VM,FBD_VR
 SG_ StatusBLEParameter_FBD_MM_Status : 24|8@1+ (1.0,0) [0|255] "" FBD_HL,FBD_HM,FBD_HR,FBD_Miko,FBD_Trunk,FBD_VL,FBD_VM,FBD_VR

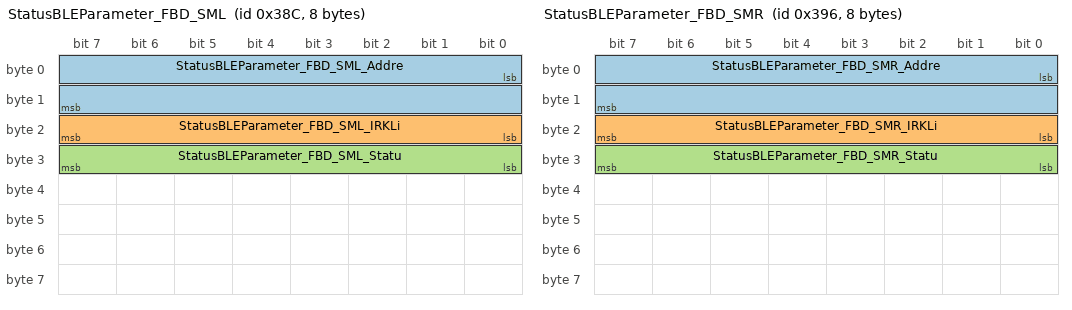
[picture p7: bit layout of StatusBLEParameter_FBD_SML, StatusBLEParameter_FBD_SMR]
BO_ 908 StatusBLEParameter_FBD_SML: 8 IPB_App1
 SG_ StatusBLEParameter_FBD_SML_Addre : 0|16@1+ (1,0) [0|0] "" FBD_HL,FBD_HM,FBD_HR,FBD_MM,FBD_Miko,FBD_Trunk,FBD_VL,FBD_VM,FBD_VR
 SG_ StatusBLEParameter_FBD_SML_IRKLi : 16|8@1+ (1.0,0) [0|252] "" FBD_HL,FBD_HM,FBD_HR,FBD_MM,FBD_Miko,FBD_Trunk,FBD_VL,FBD_VM,FBD_VR
 SG_ StatusBLEParameter_FBD_SML_Statu : 24|8@1+ (1.0,0) [0|255] "" FBD_HL,FBD_HM,FBD_HR,FBD_MM,FBD_Miko,FBD_Trunk,FBD_VL,FBD_VM,FBD_VR

BO_ 918 StatusBLEParameter_FBD_SMR: 8 IPB_App1
 SG_ StatusBLEParameter_FBD_SMR_Addre : 0|16@1+ (1,0) [0|0] "" FBD_HL,FBD_HM,FBD_HR,FBD_MM,FBD_Miko,FBD_Trunk,FBD_VL,FBD_VM,FBD_VR
 SG_ StatusBLEParameter_FBD_SMR_IRKLi : 16|8@1+ (1.0,0) [0|252] "" FBD_HL,FBD_HM,FBD_HR,FBD_MM,FBD_Miko,FBD_Trunk,FBD_VL,FBD_VM,FBD_VR
 SG_ StatusBLEParameter_FBD_SMR_Statu : 24|8@1+ (1.0,0) [0|255] "" FBD_HL,FBD_HM,FBD_HR,FBD_MM,FBD_Miko,FBD_Trunk,FBD_VL,FBD_VM,FBD_VR

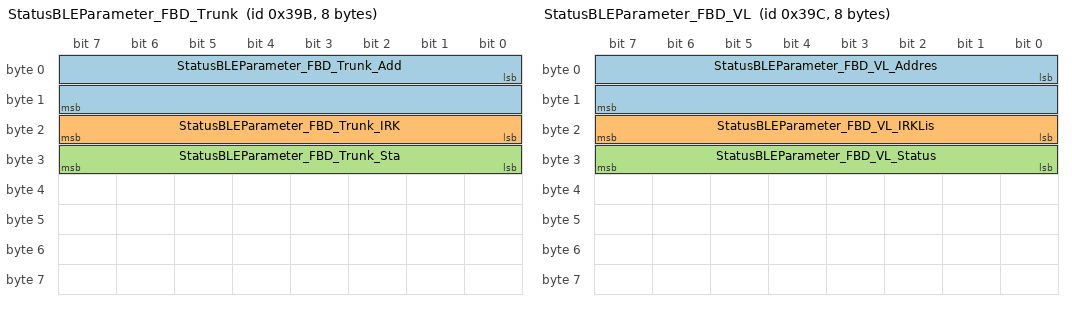
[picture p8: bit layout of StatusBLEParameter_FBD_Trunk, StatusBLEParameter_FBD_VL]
BO_ 923 StatusBLEParameter_FBD_Trunk: 8 FBD_Trunk
 SG_ StatusBLEParameter_FBD_Trunk_Add : 0|16@1+ (1,0) [0|0] "" FBD_HL,FBD_HM,FBD_HR,FBD_MM,FBD_Miko,FBD_VL,FBD_VM,FBD_VR
 SG_ StatusBLEParameter_FBD_Trunk_IRK : 16|8@1+ (1.0,0) [0|252] "" FBD_HL,FBD_HM,FBD_HR,FBD_MM,FBD_Miko,FBD_VL,FBD_VM,FBD_VR
 SG_ StatusBLEParameter_FBD_Trunk_Sta : 24|8@1+ (1.0,0) [0|255] "" FBD_HL,FBD_HM,FBD_HR,FBD_MM,FBD_Miko,FBD_VL,FBD_VM,FBD_VR

BO_ 924 StatusBLEParameter_FBD_VL: 8 FBD_VL
 SG_ StatusBLEParameter_FBD_VL_Addres : 0|16@1+ (1,0) [0|0] "" FBD_HL,FBD_HM,FBD_HR,FBD_MM,FBD_Miko,FBD_Trunk,FBD_VM,FBD_VR
 SG_ StatusBLEParameter_FBD_VL_IRKLis : 16|8@1+ (1.0,0) [0|252] "" FBD_HL,FBD_HM,FBD_HR,FBD_MM,FBD_Miko,FBD_Trunk,FBD_VM,FBD_VR
 SG_ StatusBLEParameter_FBD_VL_Status : 24|8@1+ (1.0,0) [0|255] "" FBD_HL,FBD_HM,FBD_HR,FBD_MM,FBD_Miko,FBD_Trunk,FBD_VM,FBD_VR

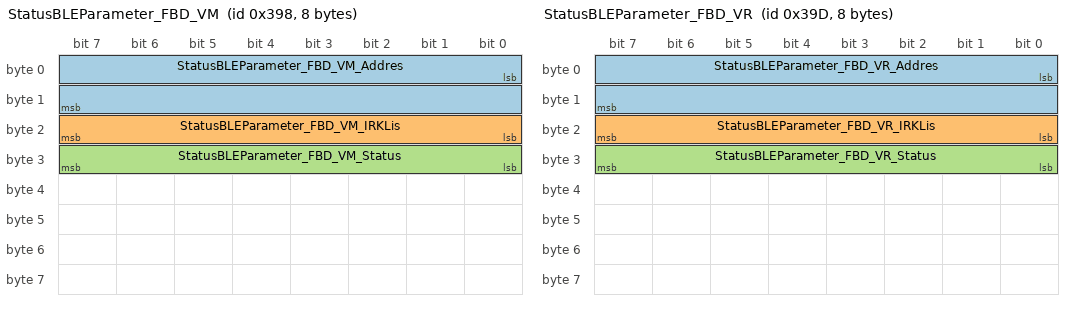
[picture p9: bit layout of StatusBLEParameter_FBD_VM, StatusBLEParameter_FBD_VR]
BO_ 920 StatusBLEParameter_FBD_VM: 8 FBD_VM
 SG_ StatusBLEParameter_FBD_VM_Addres : 0|16@1+ (1,0) [0|0] "" FBD_HL,FBD_HM,FBD_HR,FBD_MM,FBD_Miko,FBD_Trunk,FBD_VL,FBD_VR
 SG_ StatusBLEParameter_FBD_VM_IRKLis : 16|8@1+ (1.0,0) [0|252] "" FBD_HL,FBD_HM,FBD_HR,FBD_MM,FBD_Miko,FBD_Trunk,FBD_VL,FBD_VR
 SG_ StatusBLEParameter_FBD_VM_Status : 24|8@1+ (1.0,0) [0|255] "" FBD_HL,FBD_HM,FBD_HR,FBD_MM,FBD_Miko,FBD_Trunk,FBD_VL,FBD_VR

BO_ 925 StatusBLEParameter_FBD_VR: 8 FBD_VR
 SG_ StatusBLEParameter_FBD_VR_Addres : 0|16@1+ (1,0) [0|0] "" FBD_HL,FBD_HM,FBD_HR,FBD_MM,FBD_Miko,FBD_Trunk,FBD_VL,FBD_VM
 SG_ StatusBLEParameter_FBD_VR_IRKLis : 16|8@1+ (1.0,0) [0|252] "" FBD_HL,FBD_HM,FBD_HR,FBD_MM,FBD_Miko,FBD_Trunk,FBD_VL,FBD_VM
 SG_ StatusBLEParameter_FBD_VR_Status : 24|8@1+ (1.0,0) [0|255] "" FBD_HL,FBD_HM,FBD_HR,FBD_MM,FBD_Miko,FBD_Trunk,FBD_VL,FBD_VM

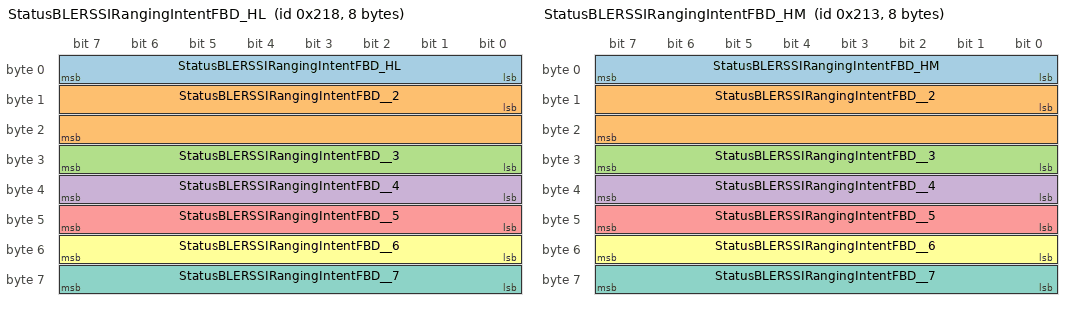
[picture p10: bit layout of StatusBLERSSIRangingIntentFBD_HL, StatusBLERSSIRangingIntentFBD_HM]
BO_ 536 StatusBLERSSIRangingIntentFBD_HL: 8 FBD_HL
 SG_ StatusBLERSSIRangingIntentFBD_HL : 0|8@1+ (1.0,0) [0|252] "" IPB_App1
 SG_ StatusBLERSSIRangingIntentFBD__2 : 8|16@1+ (1.0,0) [0|65532] "ms" IPB_App1
 SG_ StatusBLERSSIRangingIntentFBD__3 : 24|8@1+ (1.0,0) [0|252] "" IPB_App1
 SG_ StatusBLERSSIRangingIntentFBD__4 : 32|8@1+ (1.0,0) [0|252] "" IPB_App1
 SG_ StatusBLERSSIRangingIntentFBD__5 : 40|8@1+ (1.0,0) [0|252] "" IPB_App1
 SG_ StatusBLERSSIRangingIntentFBD__6 : 48|8@1+ (1.0,0) [0|252] "" IPB_App1
 SG_ StatusBLERSSIRangingIntentFBD__7 : 56|8@1+ (1.0,0) [0|252] "" IPB_App1

BO_ 531 StatusBLERSSIRangingIntentFBD_HM: 8 FBD_HM
 SG_ StatusBLERSSIRangingIntentFBD_HM : 0|8@1+ (1.0,0) [0|252] "" IPB_App1
 SG_ StatusBLERSSIRangingIntentFBD__2 : 8|16@1+ (1.0,0) [0|65532] "ms" IPB_App1
 SG_ StatusBLERSSIRangingIntentFBD__3 : 24|8@1+ (1.0,0) [0|252] "" IPB_App1
 SG_ StatusBLERSSIRangingIntentFBD__4 : 32|8@1+ (1.0,0) [0|252] "" IPB_App1
 SG_ StatusBLERSSIRangingIntentFBD__5 : 40|8@1+ (1.0,0) [0|252] "" IPB_App1
 SG_ StatusBLERSSIRangingIntentFBD__6 : 48|8@1+ (1.0,0) [0|252] "" IPB_App1
 SG_ StatusBLERSSIRangingIntentFBD__7 : 56|8@1+ (1.0,0) [0|252] "" IPB_App1

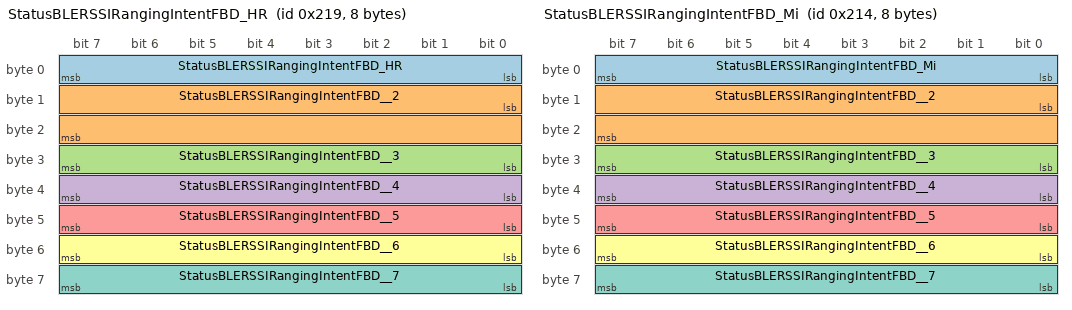
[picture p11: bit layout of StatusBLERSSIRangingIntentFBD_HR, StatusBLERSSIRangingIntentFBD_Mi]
BO_ 537 StatusBLERSSIRangingIntentFBD_HR: 8 FBD_HR
 SG_ StatusBLERSSIRangingIntentFBD_HR : 0|8@1+ (1.0,0) [0|252] "" IPB_App1
 SG_ StatusBLERSSIRangingIntentFBD__2 : 8|16@1+ (1.0,0) [0|65532] "ms" IPB_App1
 SG_ StatusBLERSSIRangingIntentFBD__3 : 24|8@1+ (1.0,0) [0|252] "" IPB_App1
 SG_ StatusBLERSSIRangingIntentFBD__4 : 32|8@1+ (1.0,0) [0|252] "" IPB_App1
 SG_ StatusBLERSSIRangingIntentFBD__5 : 40|8@1+ (1.0,0) [0|252] "" IPB_App1
 SG_ StatusBLERSSIRangingIntentFBD__6 : 48|8@1+ (1.0,0) [0|252] "" IPB_App1
 SG_ StatusBLERSSIRangingIntentFBD__7 : 56|8@1+ (1.0,0) [0|252] "" IPB_App1

BO_ 532 StatusBLERSSIRangingIntentFBD_Mi: 8 FBD_Miko
 SG_ StatusBLERSSIRangingIntentFBD_Mi : 0|8@1+ (1.0,0) [0|252] "" IPB_App1
 SG_ StatusBLERSSIRangingIntentFBD__2 : 8|16@1+ (1.0,0) [0|65532] "ms" IPB_App1
 SG_ StatusBLERSSIRangingIntentFBD__3 : 24|8@1+ (1.0,0) [0|252] "" IPB_App1
 SG_ StatusBLERSSIRangingIntentFBD__4 : 32|8@1+ (1.0,0) [0|252] "" IPB_App1
 SG_ StatusBLERSSIRangingIntentFBD__5 : 40|8@1+ (1.0,0) [0|252] "" IPB_App1
 SG_ StatusBLERSSIRangingIntentFBD__6 : 48|8@1+ (1.0,0) [0|252] "" IPB_App1
 SG_ StatusBLERSSIRangingIntentFBD__7 : 56|8@1+ (1.0,0) [0|252] "" IPB_App1

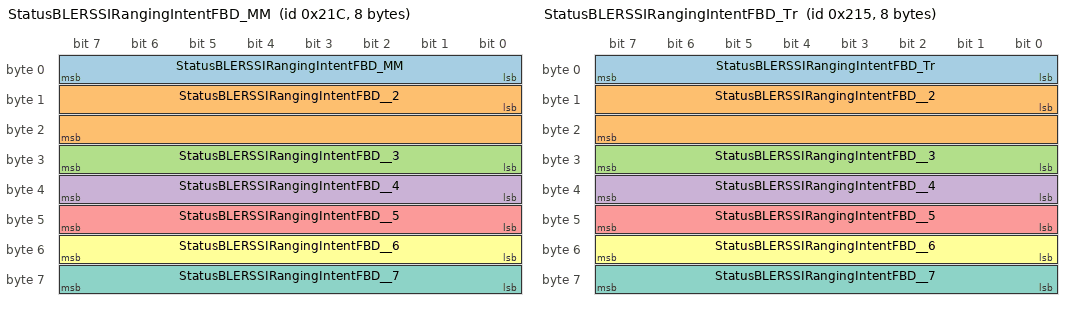
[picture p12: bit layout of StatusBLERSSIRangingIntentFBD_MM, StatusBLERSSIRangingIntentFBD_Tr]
BO_ 540 StatusBLERSSIRangingIntentFBD_MM: 8 FBD_MM
 SG_ StatusBLERSSIRangingIntentFBD_MM : 0|8@1+ (1.0,0) [0|252] "" IPB_App1
 SG_ StatusBLERSSIRangingIntentFBD__2 : 8|16@1+ (1.0,0) [0|65532] "ms" IPB_App1
 SG_ StatusBLERSSIRangingIntentFBD__3 : 24|8@1+ (1.0,0) [0|252] "" IPB_App1
 SG_ StatusBLERSSIRangingIntentFBD__4 : 32|8@1+ (1.0,0) [0|252] "" IPB_App1
 SG_ StatusBLERSSIRangingIntentFBD__5 : 40|8@1+ (1.0,0) [0|252] "" IPB_App1
 SG_ StatusBLERSSIRangingIntentFBD__6 : 48|8@1+ (1.0,0) [0|252] "" IPB_App1
 SG_ StatusBLERSSIRangingIntentFBD__7 : 56|8@1+ (1.0,0) [0|252] "" IPB_App1

BO_ 533 StatusBLERSSIRangingIntentFBD_Tr: 8 FBD_Trunk
 SG_ StatusBLERSSIRangingIntentFBD_Tr : 0|8@1+ (1.0,0) [0|252] "" IPB_App1
 SG_ StatusBLERSSIRangingIntentFBD__2 : 8|16@1+ (1.0,0) [0|65532] "ms" IPB_App1
 SG_ StatusBLERSSIRangingIntentFBD__3 : 24|8@1+ (1.0,0) [0|252] "" IPB_App1
 SG_ StatusBLERSSIRangingIntentFBD__4 : 32|8@1+ (1.0,0) [0|252] "" IPB_App1
 SG_ StatusBLERSSIRangingIntentFBD__5 : 40|8@1+ (1.0,0) [0|252] "" IPB_App1
 SG_ StatusBLERSSIRangingIntentFBD__6 : 48|8@1+ (1.0,0) [0|252] "" IPB_App1
 SG_ StatusBLERSSIRangingIntentFBD__7 : 56|8@1+ (1.0,0) [0|252] "" IPB_App1

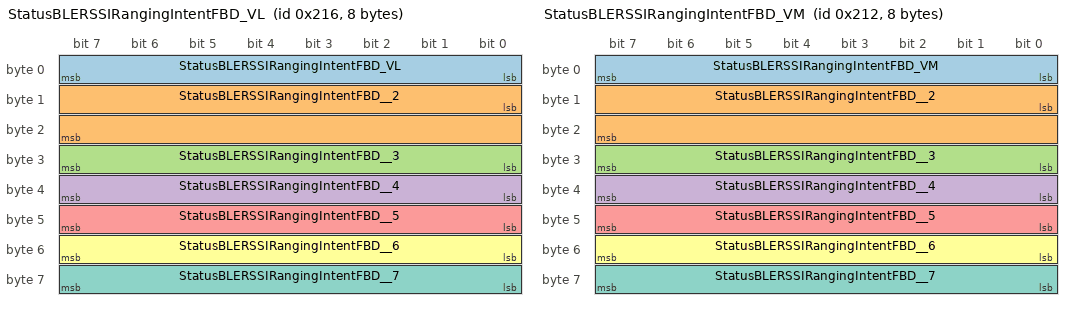
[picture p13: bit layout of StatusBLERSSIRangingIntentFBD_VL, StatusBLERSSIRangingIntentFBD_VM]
BO_ 534 StatusBLERSSIRangingIntentFBD_VL: 8 FBD_VL
 SG_ StatusBLERSSIRangingIntentFBD_VL : 0|8@1+ (1.0,0) [0|252] "" IPB_App1
 SG_ StatusBLERSSIRangingIntentFBD__2 : 8|16@1+ (1.0,0) [0|65532] "ms" IPB_App1
 SG_ StatusBLERSSIRangingIntentFBD__3 : 24|8@1+ (1.0,0) [0|252] "" IPB_App1
 SG_ StatusBLERSSIRangingIntentFBD__4 : 32|8@1+ (1.0,0) [0|252] "" IPB_App1
 SG_ StatusBLERSSIRangingIntentFBD__5 : 40|8@1+ (1.0,0) [0|252] "" IPB_App1
 SG_ StatusBLERSSIRangingIntentFBD__6 : 48|8@1+ (1.0,0) [0|252] "" IPB_App1
 SG_ StatusBLERSSIRangingIntentFBD__7 : 56|8@1+ (1.0,0) [0|252] "" IPB_App1

BO_ 530 StatusBLERSSIRangingIntentFBD_VM: 8 FBD_VM
 SG_ StatusBLERSSIRangingIntentFBD_VM : 0|8@1+ (1.0,0) [0|252] "" IPB_App1
 SG_ StatusBLERSSIRangingIntentFBD__2 : 8|16@1+ (1.0,0) [0|65532] "ms" IPB_App1
 SG_ StatusBLERSSIRangingIntentFBD__3 : 24|8@1+ (1.0,0) [0|252] "" IPB_App1
 SG_ StatusBLERSSIRangingIntentFBD__4 : 32|8@1+ (1.0,0) [0|252] "" IPB_App1
 SG_ StatusBLERSSIRangingIntentFBD__5 : 40|8@1+ (1.0,0) [0|252] "" IPB_App1
 SG_ StatusBLERSSIRangingIntentFBD__6 : 48|8@1+ (1.0,0) [0|252] "" IPB_App1
 SG_ StatusBLERSSIRangingIntentFBD__7 : 56|8@1+ (1.0,0) [0|252] "" IPB_App1

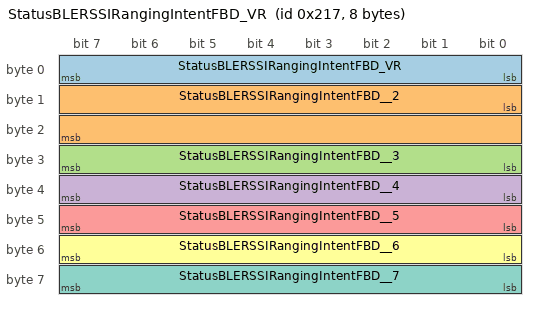
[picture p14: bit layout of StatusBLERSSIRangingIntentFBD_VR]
BO_ 535 StatusBLERSSIRangingIntentFBD_VR: 8 FBD_VR
 SG_ StatusBLERSSIRangingIntentFBD_VR : 0|8@1+ (1.0,0) [0|252] "" IPB_App1
 SG_ StatusBLERSSIRangingIntentFBD__2 : 8|16@1+ (1.0,0) [0|65532] "ms" IPB_App1
 SG_ StatusBLERSSIRangingIntentFBD__3 : 24|8@1+ (1.0,0) [0|252] "" IPB_App1
 SG_ StatusBLERSSIRangingIntentFBD__4 : 32|8@1+ (1.0,0) [0|252] "" IPB_App1
 SG_ StatusBLERSSIRangingIntentFBD__5 : 40|8@1+ (1.0,0) [0|252] "" IPB_App1
 SG_ StatusBLERSSIRangingIntentFBD__6 : 48|8@1+ (1.0,0) [0|252] "" IPB_App1
 SG_ StatusBLERSSIRangingIntentFBD__7 : 56|8@1+ (1.0,0) [0|252] "" IPB_App1

BO_ 216 StatusBLESettingsFBD_HL: 20 FBD_HL
 SG_ StatusBLESettingsFBD_HL_BLEOpera : 0|8@1+ (1,0) [0|0] "" IPB_App1
 SG_ StatusBLESettingsFBD_HL_Advertis : 8|16@1+ (1.0,0) [0|65532] "" IPB_App1
 SG_ StatusBLESettingsFBD_HL_Connecti : 24|16@1+ (1.0,0) [0|65532] "" IPB_App1
 SG_ StatusBLESettingsFBD_HL_IRKListI : 40|8@1+ (1.0,0) [0|252] "" IPB_App1
 SG_ StatusBLESettingsFBD_HL_Settings : 48|8@1+ (1,0) [0|0] "" IPB_App1
 SG_ StatusBLESettingsFBD_HL_LR500_Ad : 56|16@1+ (1.0,0) [0|65532] "" IPB_App1
 SG_ StatusBLESettingsFBD_HL_LR125_Ad : 72|16@1+ (1.0,0) [0|65532] "" IPB_App1
 SG_ StatusBLESettingsFBD_HL_Extended : 88|8@1+ (1,0) [0|0] "" IPB_App1
 SG_ StatusBLESettingsFBD_HL_TxPower : 96|8@1+ (1.0,0) [0|252] "" IPB_App1
 SG_ StatusBLESettingsFBD_HL_PSM : 104|8@1+ (1.0,0) [0|252] "" IPB_App1
 SG_ StatusBLESettingsFBD_HL_RPAFrequ : 112|8@1+ (1.0,0) [0|252] "" IPB_App1
 SG_ StatusBLESettingsFBD_HL_DCKVersi : 120|8@1+ (1.0,0) [0|252] "" IPB_App1
 SG_ StatusBLESettingsFBD_HL_ScanRequ : 128|8@1+ (1,0) [0|0] "" IPB_App1

BO_ 211 StatusBLESettingsFBD_HM: 20 FBD_HM
 SG_ StatusBLESettingsFBD_HM_BLEOpera : 0|8@1+ (1,0) [0|0] "" IPB_App1
 SG_ StatusBLESettingsFBD_HM_Advertis : 8|16@1+ (1.0,0) [0|65532] "" IPB_App1
 SG_ StatusBLESettingsFBD_HM_Connecti : 24|16@1+ (1.0,0) [0|65532] "" IPB_App1
 SG_ StatusBLESettingsFBD_HM_IRKListI : 40|8@1+ (1.0,0) [0|252] "" IPB_App1
 SG_ StatusBLESettingsFBD_HM_Settings : 48|8@1+ (1,0) [0|0] "" IPB_App1
 SG_ StatusBLESettingsFBD_HM_LR500_Ad : 56|16@1+ (1.0,0) [0|65532] "" IPB_App1
 SG_ StatusBLESettingsFBD_HM_LR125_Ad : 72|16@1+ (1.0,0) [0|65532] "" IPB_App1
 SG_ StatusBLESettingsFBD_HM_Extended : 88|8@1+ (1,0) [0|0] "" IPB_App1
 SG_ StatusBLESettingsFBD_HM_TxPower : 96|8@1+ (1.0,0) [0|252] "" IPB_App1
 SG_ StatusBLESettingsFBD_HM_PSM : 104|8@1+ (1.0,0) [0|252] "" IPB_App1
 SG_ StatusBLESettingsFBD_HM_RPAFrequ : 112|8@1+ (1.0,0) [0|252] "" IPB_App1
 SG_ StatusBLESettingsFBD_HM_DCKVersi : 120|8@1+ (1.0,0) [0|252] "" IPB_App1
 SG_ StatusBLESettingsFBD_HM_ScanRequ : 128|8@1+ (1,0) [0|0] "" IPB_App1

BO_ 217 StatusBLESettingsFBD_HR: 20 FBD_HR
 SG_ StatusBLESettingsFBD_HR_BLEOpera : 0|8@1+ (1,0) [0|0] "" IPB_App1
 SG_ StatusBLESettingsFBD_HR_Advertis : 8|16@1+ (1.0,0) [0|65532] "" IPB_App1
 SG_ StatusBLESettingsFBD_HR_Connecti : 24|16@1+ (1.0,0) [0|65532] "" IPB_App1
 SG_ StatusBLESettingsFBD_HR_IRKListI : 40|8@1+ (1.0,0) [0|252] "" IPB_App1
 SG_ StatusBLESettingsFBD_HR_Settings : 48|8@1+ (1,0) [0|0] "" IPB_App1
 SG_ StatusBLESettingsFBD_HR_LR500_Ad : 56|16@1+ (1.0,0) [0|65532] "" IPB_App1
 SG_ StatusBLESettingsFBD_HR_LR125_Ad : 72|16@1+ (1.0,0) [0|65532] "" IPB_App1
 SG_ StatusBLESettingsFBD_HR_Extended : 88|8@1+ (1,0) [0|0] "" IPB_App1
 SG_ StatusBLESettingsFBD_HR_TxPower : 96|8@1+ (1.0,0) [0|252] "" IPB_App1
 SG_ StatusBLESettingsFBD_HR_PSM : 104|8@1+ (1.0,0) [0|252] "" IPB_App1
 SG_ StatusBLESettingsFBD_HR_RPAFrequ : 112|8@1+ (1.0,0) [0|252] "" IPB_App1
 SG_ StatusBLESettingsFBD_HR_DCKVersi : 120|8@1+ (1.0,0) [0|252] "" IPB_App1
 SG_ StatusBLESettingsFBD_HR_ScanRequ : 128|8@1+ (1,0) [0|0] "" IPB_App1

BO_ 212 StatusBLESettingsFBD_Miko: 20 FBD_Miko
 SG_ StatusBLESettingsFBD_Miko_BLEOpe : 0|8@1+ (1,0) [0|0] "" IPB_App1
 SG_ StatusBLESettingsFBD_Miko_Advert : 8|16@1+ (1.0,0) [0|65532] "" IPB_App1
 SG_ StatusBLESettingsFBD_Miko_Connec : 24|16@1+ (1.0,0) [0|65532] "" IPB_App1
 SG_ StatusBLESettingsFBD_Miko_IRKLis : 40|8@1+ (1,0) [0|0] "" IPB_App1
 SG_ StatusBLESettingsFBD_Miko_Settin : 48|8@1+ (1.0,0) [0|252] "" IPB_App1
 SG_ StatusBLESettingsFBD_Miko_LR500_ : 56|16@1+ (1.0,0) [0|65532] "" IPB_App1
 SG_ StatusBLESettingsFBD_Miko_LR125_ : 72|16@1+ (1.0,0) [0|65532] "" IPB_App1
 SG_ StatusBLESettingsFBD_Miko_Extend : 88|8@1+ (1,0) [0|0] "" IPB_App1
 SG_ StatusBLESettingsFBD_Miko_TxPowe : 96|8@1+ (1.0,0) [0|252] "" IPB_App1
 SG_ StatusBLESettingsFBD_Miko_PSM : 104|8@1+ (1.0,0) [0|252] "" IPB_App1
 SG_ StatusBLESettingsFBD_Miko_RPAFre : 112|8@1+ (1.0,0) [0|252] "" IPB_App1
 SG_ StatusBLESettingsFBD_Miko_DCKVer : 120|8@1+ (1.0,0) [0|252] "" IPB_App1
 SG_ StatusBLESettingsFBD_Miko_ScanRe : 128|8@1+ (1,0) [0|0] "" IPB_App1

BO_ 240 StatusBLESettingsFBD_MM: 20 FBD_MM
 SG_ StatusBLESettingsFBD_MM_BLEOpera : 0|8@1+ (1,0) [0|0] "" IPB_App1
 SG_ StatusBLESettingsFBD_MM_Advertis : 8|16@1+ (1.0,0) [0|65532] "" IPB_App1
 SG_ StatusBLESettingsFBD_MM_Connecti : 24|16@1+ (1.0,0) [0|65532] "" IPB_App1
 SG_ StatusBLESettingsFBD_MM_IRKListI : 40|8@1+ (1.0,0) [0|252] "" IPB_App1
 SG_ StatusBLESettingsFBD_MM_Settings : 48|8@1+ (1,0) [0|0] "" IPB_App1
 SG_ StatusBLESettingsFBD_MM_LR500_Ad : 56|16@1+ (1.0,0) [0|65532] "" IPB_App1
 SG_ StatusBLESettingsFBD_MM_LR125_Ad : 72|16@1+ (1.0,0) [0|65532] "" IPB_App1
 SG_ StatusBLESettingsFBD_MM_Extended : 88|8@1+ (1,0) [0|0] "" IPB_App1
 SG_ StatusBLESettingsFBD_MM_TxPower : 96|8@1+ (1.0,0) [0|252] "" IPB_App1
 SG_ StatusBLESettingsFBD_MM_PSM : 104|8@1+ (1.0,0) [0|252] "" IPB_App1
 SG_ StatusBLESettingsFBD_MM_RPAFrequ : 112|8@1+ (1.0,0) [0|252] "" IPB_App1
 SG_ StatusBLESettingsFBD_MM_DCKVersi : 120|8@1+ (1.0,0) [0|252] "" IPB_App1
 SG_ StatusBLESettingsFBD_MM_ScanRequ : 128|8@1+ (1,0) [0|0] "" IPB_App1

BO_ 213 StatusBLESettingsFBD_Trunk: 20 FBD_Trunk
 SG_ StatusBLESettingsFBD_Trunk_BLEOp : 0|8@1+ (1,0) [0|0] "" IPB_App1
 SG_ StatusBLESettingsFBD_Trunk_Adver : 8|16@1+ (1.0,0) [0|65532] "" IPB_App1
 SG_ StatusBLESettingsFBD_Trunk_Conne : 24|16@1+ (1.0,0) [0|65532] "" IPB_App1
 SG_ StatusBLESettingsFBD_Trunk_IRKLi : 40|8@1+ (1,0) [0|0] "" IPB_App1
 SG_ StatusBLESettingsFBD_Trunk_Setti : 48|8@1+ (1.0,0) [0|252] "" IPB_App1
 SG_ StatusBLESettingsFBD_Trunk_LR500 : 56|16@1+ (1.0,0) [0|65532] "" IPB_App1
 SG_ StatusBLESettingsFBD_Trunk_LR125 : 72|16@1+ (1.0,0) [0|65532] "" IPB_App1
 SG_ StatusBLESettingsFBD_Trunk_Exten : 88|8@1+ (1,0) [0|0] "" IPB_App1
 SG_ StatusBLESettingsFBD_Trunk_TxPow : 96|8@1+ (1.0,0) [0|252] "" IPB_App1
 SG_ StatusBLESettingsFBD_Trunk_PSM : 104|8@1+ (1.0,0) [0|252] "" IPB_App1
 SG_ StatusBLESettingsFBD_Trunk_RPAFr : 112|8@1+ (1.0,0) [0|252] "" IPB_App1
 SG_ StatusBLESettingsFBD_Trunk_DCKVe : 120|8@1+ (1.0,0) [0|252] "" IPB_App1
 SG_ StatusBLESettingsFBD_Trunk_ScanR : 128|8@1+ (1,0) [0|0] "" IPB_App1

BO_ 214 StatusBLESettingsFBD_VL: 20 FBD_VL
 SG_ StatusBLESettingsFBD_VL_BLEOpera : 0|8@1+ (1,0) [0|0] "" IPB_App1
 SG_ StatusBLESettingsFBD_VL_Advertis : 8|16@1+ (1.0,0) [0|65532] "" IPB_App1
 SG_ StatusBLESettingsFBD_VL_Connecti : 24|16@1+ (1.0,0) [0|65532] "" IPB_App1
 SG_ StatusBLESettingsFBD_VL_IRKListI : 40|8@1+ (1.0,0) [0|252] "" IPB_App1
 SG_ StatusBLESettingsFBD_VL_Settings : 48|8@1+ (1,0) [0|0] "" IPB_App1
 SG_ StatusBLESettingsFBD_VL_LR500_Ad : 56|16@1+ (1.0,0) [0|65532] "" IPB_App1
 SG_ StatusBLESettingsFBD_VL_LR125_Ad : 72|16@1+ (1.0,0) [0|65532] "" IPB_App1
 SG_ StatusBLESettingsFBD_VL_Extended : 88|8@1+ (1,0) [0|0] "" IPB_App1
 SG_ StatusBLESettingsFBD_VL_TxPower : 96|8@1+ (1.0,0) [0|252] "" IPB_App1
 SG_ StatusBLESettingsFBD_VL_PSM : 104|8@1+ (1.0,0) [0|252] "" IPB_App1
 SG_ StatusBLESettingsFBD_VL_RPAFrequ : 112|8@1+ (1.0,0) [0|252] "" IPB_App1
 SG_ StatusBLESettingsFBD_VL_DCKVersi : 120|8@1+ (1.0,0) [0|252] "" IPB_App1
 SG_ StatusBLESettingsFBD_VL_ScanRequ : 128|8@1+ (1,0) [0|0] "" IPB_App1

BO_ 210 StatusBLESettingsFBD_VM: 20 FBD_VM
 SG_ StatusBLESettingsFBD_VM_BLEOpera : 0|8@1+ (1,0) [0|0] "" IPB_App1
 SG_ StatusBLESettingsFBD_VM_Advertis : 8|16@1+ (1.0,0) [0|65532] "" IPB_App1
 SG_ StatusBLESettingsFBD_VM_Connecti : 24|16@1+ (1.0,0) [0|65532] "" IPB_App1
 SG_ StatusBLESettingsFBD_VM_IRKListI : 40|8@1+ (1,0) [0|0] "" IPB_App1
 SG_ StatusBLESettingsFBD_VM_Settings : 48|8@1+ (1,0) [0|0] "" IPB_App1
 SG_ StatusBLESettingsFBD_VM_LR500_Ad : 56|16@1+ (1.0,0) [0|65532] "" IPB_App1
 SG_ StatusBLESettingsFBD_VM_LR125_Ad : 72|16@1+ (1.0,0) [0|65532] "" IPB_App1
 SG_ StatusBLESettingsFBD_VM_Extended : 88|8@1+ (1,0) [0|0] "" IPB_App1
 SG_ StatusBLESettingsFBD_VM_TxPower : 96|8@1+ (1.0,0) [0|252] "" IPB_App1
 SG_ StatusBLESettingsFBD_VM_PSM : 104|8@1+ (1.0,0) [0|252] "" IPB_App1
 SG_ StatusBLESettingsFBD_VM_RPAFrequ : 112|8@1+ (1.0,0) [0|252] "" IPB_App1
 SG_ StatusBLESettingsFBD_VM_DCKVersi : 120|8@1+ (1.0,0) [0|252] "" IPB_App1
 SG_ StatusBLESettingsFBD_VM_ScanRequ : 128|8@1+ (1,0) [0|0] "" IPB_App1

BO_ 215 StatusBLESettingsFBD_VR: 20 FBD_VR
 SG_ StatusBLESettingsFBD_VR_BLEOpera : 0|8@1+ (1,0) [0|0] "" IPB_App1
 SG_ StatusBLESettingsFBD_VR_Advertis : 8|16@1+ (1.0,0) [0|65532] "" IPB_App1
 SG_ StatusBLESettingsFBD_VR_Connecti : 24|16@1+ (1.0,0) [0|65532] "" IPB_App1
 SG_ StatusBLESettingsFBD_VR_IRKListI : 40|8@1+ (1,0) [0|0] "" IPB_App1
 SG_ StatusBLESettingsFBD_VR_Settings : 48|8@1+ (1,0) [0|0] "" IPB_App1
 SG_ StatusBLESettingsFBD_VR_LR500_Ad : 56|16@1+ (1.0,0) [0|65532] "" IPB_App1
 SG_ StatusBLESettingsFBD_VR_LR125_Ad : 72|16@1+ (1.0,0) [0|65532] "" IPB_App1
 SG_ StatusBLESettingsFBD_VR_Extended : 88|8@1+ (1,0) [0|0] "" IPB_App1
 SG_ StatusBLESettingsFBD_VR_TxPower : 96|8@1+ (1.0,0) [0|252] "" IPB_App1
 SG_ StatusBLESettingsFBD_VR_PSM : 104|8@1+ (1.0,0) [0|252] "" IPB_App1
 SG_ StatusBLESettingsFBD_VR_RPAFrequ : 112|8@1+ (1.0,0) [0|252] "" IPB_App1
 SG_ StatusBLESettingsFBD_VR_DCKVersi : 120|8@1+ (1.0,0) [0|252] "" IPB_App1
 SG_ StatusBLESettingsFBD_VR_ScanRequ : 128|8@1+ (1,0) [0|0] "" IPB_App1

BO_ 396 StatusBLESettingsPriorityFBD_HL: 20 FBD_HL
 SG_ StatusBLESettingsPriorityFBD_HL_ : 0|8@1+ (1.0,0) [0|252] "" IPB_App1
 SG_ StatusBLESettingsPriorityFBD_H_2 : 8|8@1+ (1.0,0) [0|252] "" IPB_App1
 SG_ StatusBLESettingsPriorityFBD_H_3 : 16|8@1+ (1,0) [0|0] "" IPB_App1
 SG_ StatusBLESettingsPriorityFBD_H_4 : 24|8@1+ (1.0,0) [0|252] "" IPB_App1
 SG_ StatusBLESettingsPriorityFBD_H_5 : 32|8@1+ (1,0) [0|0] "" IPB_App1
 SG_ StatusBLESettingsPriorityFBD_H_6 : 40|8@1+ (1.0,0) [0|252] "" IPB_App1
 SG_ StatusBLESettingsPriorityFBD_H_7 : 48|8@1+ (1,0) [0|0] "" IPB_App1
 SG_ StatusBLESettingsPriorityFBD_H_8 : 56|8@1+ (1.0,0) [0|252] "" IPB_App1
 SG_ StatusBLESettingsPriorityFBD_H_9 : 64|8@1+ (1,0) [0|0] "" IPB_App1
 SG_ StatusBLESettingsPriorityFBD__10 : 72|8@1+ (1.0,0) [0|252] "" IPB_App1
 SG_ StatusBLESettingsPriorityFBD__11 : 80|8@1+ (1,0) [0|0] "" IPB_App1
 SG_ StatusBLESettingsPriorityFBD__12 : 88|8@1+ (1.0,0) [0|252] "" IPB_App1
 SG_ StatusBLESettingsPriorityFBD__13 : 96|8@1+ (1,0) [0|0] "" IPB_App1
 SG_ StatusBLESettingsPriorityFBD__14 : 104|8@1+ (1.0,0) [0|252] "" IPB_App1
 SG_ StatusBLESettingsPriorityFBD__15 : 112|8@1+ (1,0) [0|0] "" IPB_App1
 SG_ StatusBLESettingsPriorityFBD__16 : 120|8@1+ (1.0,0) [0|252] "" IPB_App1
 SG_ StatusBLESettingsPriorityFBD__17 : 128|8@1+ (1,0) [0|0] "" IPB_App1

BO_ 391 StatusBLESettingsPriorityFBD_HM: 20 FBD_HM
 SG_ StatusBLESettingsPriorityFBD_HM_ : 0|8@1+ (1.0,0) [0|252] "" IPB_App1
 SG_ StatusBLESettingsPriorityFBD_H_2 : 8|8@1+ (1.0,0) [0|252] "" IPB_App1
 SG_ StatusBLESettingsPriorityFBD_H_3 : 16|8@1+ (1,0) [0|0] "" IPB_App1
 SG_ StatusBLESettingsPriorityFBD_H_4 : 24|8@1+ (1.0,0) [0|252] "" IPB_App1
 SG_ StatusBLESettingsPriorityFBD_H_5 : 32|8@1+ (1,0) [0|0] "" IPB_App1
 SG_ StatusBLESettingsPriorityFBD_H_6 : 40|8@1+ (1.0,0) [0|252] "" IPB_App1
 SG_ StatusBLESettingsPriorityFBD_H_7 : 48|8@1+ (1,0) [0|0] "" IPB_App1
 SG_ StatusBLESettingsPriorityFBD_H_8 : 56|8@1+ (1.0,0) [0|252] "" IPB_App1
 SG_ StatusBLESettingsPriorityFBD_H_9 : 64|8@1+ (1,0) [0|0] "" IPB_App1
 SG_ StatusBLESettingsPriorityFBD__10 : 72|8@1+ (1.0,0) [0|252] "" IPB_App1
 SG_ StatusBLESettingsPriorityFBD__11 : 80|8@1+ (1,0) [0|0] "" IPB_App1
 SG_ StatusBLESettingsPriorityFBD__12 : 88|8@1+ (1.0,0) [0|252] "" IPB_App1
 SG_ StatusBLESettingsPriorityFBD__13 : 96|8@1+ (1,0) [0|0] "" IPB_App1
 SG_ StatusBLESettingsPriorityFBD__14 : 104|8@1+ (1.0,0) [0|252] "" IPB_App1
 SG_ StatusBLESettingsPriorityFBD__15 : 112|8@1+ (1,0) [0|0] "" IPB_App1
 SG_ StatusBLESettingsPriorityFBD__16 : 120|8@1+ (1.0,0) [0|252] "" IPB_App1
 SG_ StatusBLESettingsPriorityFBD__17 : 128|8@1+ (1,0) [0|0] "" IPB_App1

BO_ 397 StatusBLESettingsPriorityFBD_HR: 20 FBD_HR
 SG_ StatusBLESettingsPriorityFBD_HR_ : 0|8@1+ (1.0,0) [0|252] "" IPB_App1
 SG_ StatusBLESettingsPriorityFBD_H_2 : 8|8@1+ (1.0,0) [0|252] "" IPB_App1
 SG_ StatusBLESettingsPriorityFBD_H_3 : 16|8@1+ (1,0) [0|0] "" IPB_App1
 SG_ StatusBLESettingsPriorityFBD_H_4 : 24|8@1+ (1.0,0) [0|252] "" IPB_App1
 SG_ StatusBLESettingsPriorityFBD_H_5 : 32|8@1+ (1,0) [0|0] "" IPB_App1
 SG_ StatusBLESettingsPriorityFBD_H_6 : 40|8@1+ (1.0,0) [0|252] "" IPB_App1
 SG_ StatusBLESettingsPriorityFBD_H_7 : 48|8@1+ (1,0) [0|0] "" IPB_App1
 SG_ StatusBLESettingsPriorityFBD_H_8 : 56|8@1+ (1.0,0) [0|252] "" IPB_App1
 SG_ StatusBLESettingsPriorityFBD_H_9 : 64|8@1+ (1,0) [0|0] "" IPB_App1
 SG_ StatusBLESettingsPriorityFBD__10 : 72|8@1+ (1.0,0) [0|252] "" IPB_App1
 SG_ StatusBLESettingsPriorityFBD__11 : 80|8@1+ (1,0) [0|0] "" IPB_App1
 SG_ StatusBLESettingsPriorityFBD__12 : 88|8@1+ (1.0,0) [0|252] "" IPB_App1
 SG_ StatusBLESettingsPriorityFBD__13 : 96|8@1+ (1,0) [0|0] "" IPB_App1
 SG_ StatusBLESettingsPriorityFBD__14 : 104|8@1+ (1.0,0) [0|252] "" IPB_App1
 SG_ StatusBLESettingsPriorityFBD__15 : 112|8@1+ (1,0) [0|0] "" IPB_App1
 SG_ StatusBLESettingsPriorityFBD__16 : 120|8@1+ (1.0,0) [0|252] "" IPB_App1
 SG_ StatusBLESettingsPriorityFBD__17 : 128|8@1+ (1,0) [0|0] "" IPB_App1

BO_ 392 StatusBLESettingsPriorityFBD_Mik: 20 FBD_Miko
 SG_ StatusBLESettingsPriorityFBD_Mik : 0|8@1+ (1.0,0) [0|252] "" IPB_App1
 SG_ StatusBLESettingsPriorityFBD_M_2 : 8|8@1+ (1.0,0) [0|252] "" IPB_App1
 SG_ StatusBLESettingsPriorityFBD_M_3 : 16|8@1+ (1,0) [0|0] "" IPB_App1
 SG_ StatusBLESettingsPriorityFBD_M_4 : 24|8@1+ (1.0,0) [0|252] "" IPB_App1
 SG_ StatusBLESettingsPriorityFBD_M_5 : 32|8@1+ (1,0) [0|0] "" IPB_App1
 SG_ StatusBLESettingsPriorityFBD_M_6 : 40|8@1+ (1.0,0) [0|252] "" IPB_App1
 SG_ StatusBLESettingsPriorityFBD_M_7 : 48|8@1+ (1,0) [0|0] "" IPB_App1
 SG_ StatusBLESettingsPriorityFBD_M_8 : 56|8@1+ (1.0,0) [0|252] "" IPB_App1
 SG_ StatusBLESettingsPriorityFBD_M_9 : 64|8@1+ (1,0) [0|0] "" IPB_App1
 SG_ StatusBLESettingsPriorityFBD__10 : 72|8@1+ (1.0,0) [0|252] "" IPB_App1
 SG_ StatusBLESettingsPriorityFBD__11 : 80|8@1+ (1,0) [0|0] "" IPB_App1
 SG_ StatusBLESettingsPriorityFBD__12 : 88|8@1+ (1.0,0) [0|252] "" IPB_App1
 SG_ StatusBLESettingsPriorityFBD__13 : 96|8@1+ (1,0) [0|0] "" IPB_App1
 SG_ StatusBLESettingsPriorityFBD__14 : 104|8@1+ (1.0,0) [0|252] "" IPB_App1
 SG_ StatusBLESettingsPriorityFBD__15 : 112|8@1+ (1,0) [0|0] "" IPB_App1
 SG_ StatusBLESettingsPriorityFBD__16 : 120|8@1+ (1.0,0) [0|252] "" IPB_App1
 SG_ StatusBLESettingsPriorityFBD__17 : 128|8@1+ (1,0) [0|0] "" IPB_App1

BO_ 823 StatusBLESettingsPriorityFBD_MM: 20 FBD_MM
 SG_ StatusBLESettingsPriorityFBD_MM_ : 0|8@1+ (1.0,0) [0|252] "" IPB_App1
 SG_ StatusBLESettingsPriorityFBD_M_2 : 8|8@1+ (1.0,0) [0|252] "" IPB_App1
 SG_ StatusBLESettingsPriorityFBD_M_3 : 16|8@1+ (1,0) [0|0] "" IPB_App1
 SG_ StatusBLESettingsPriorityFBD_M_4 : 24|8@1+ (1.0,0) [0|252] "" IPB_App1
 SG_ StatusBLESettingsPriorityFBD_M_5 : 32|8@1+ (1,0) [0|0] "" IPB_App1
 SG_ StatusBLESettingsPriorityFBD_M_6 : 40|8@1+ (1.0,0) [0|252] "" IPB_App1
 SG_ StatusBLESettingsPriorityFBD_M_7 : 48|8@1+ (1,0) [0|0] "" IPB_App1
 SG_ StatusBLESettingsPriorityFBD_M_8 : 56|8@1+ (1.0,0) [0|252] "" IPB_App1
 SG_ StatusBLESettingsPriorityFBD_M_9 : 64|8@1+ (1,0) [0|0] "" IPB_App1
 SG_ StatusBLESettingsPriorityFBD__10 : 72|8@1+ (1.0,0) [0|252] "" IPB_App1
 SG_ StatusBLESettingsPriorityFBD__11 : 80|8@1+ (1,0) [0|0] "" IPB_App1
 SG_ StatusBLESettingsPriorityFBD__12 : 88|8@1+ (1.0,0) [0|252] "" IPB_App1
 SG_ StatusBLESettingsPriorityFBD__13 : 96|8@1+ (1,0) [0|0] "" IPB_App1
 SG_ StatusBLESettingsPriorityFBD__14 : 104|8@1+ (1.0,0) [0|252] "" IPB_App1
 SG_ StatusBLESettingsPriorityFBD__15 : 112|8@1+ (1,0) [0|0] "" IPB_App1
 SG_ StatusBLESettingsPriorityFBD__16 : 120|8@1+ (1.0,0) [0|252] "" IPB_App1
 SG_ StatusBLESettingsPriorityFBD__17 : 128|8@1+ (1,0) [0|0] "" IPB_App1

BO_ 393 StatusBLESettingsPriorityFBD_Tru: 20 FBD_Trunk
 SG_ StatusBLESettingsPriorityFBD_Tru : 0|8@1+ (1.0,0) [0|252] "" IPB_App1
 SG_ StatusBLESettingsPriorityFBD_T_2 : 8|8@1+ (1.0,0) [0|252] "" IPB_App1
 SG_ StatusBLESettingsPriorityFBD_T_3 : 16|8@1+ (1,0) [0|0] "" IPB_App1
 SG_ StatusBLESettingsPriorityFBD_T_4 : 24|8@1+ (1.0,0) [0|252] "" IPB_App1
 SG_ StatusBLESettingsPriorityFBD_T_5 : 32|8@1+ (1,0) [0|0] "" IPB_App1
 SG_ StatusBLESettingsPriorityFBD_T_6 : 40|8@1+ (1.0,0) [0|252] "" IPB_App1
 SG_ StatusBLESettingsPriorityFBD_T_7 : 48|8@1+ (1,0) [0|0] "" IPB_App1
 SG_ StatusBLESettingsPriorityFBD_T_8 : 56|8@1+ (1.0,0) [0|252] "" IPB_App1
 SG_ StatusBLESettingsPriorityFBD_T_9 : 64|8@1+ (1,0) [0|0] "" IPB_App1
 SG_ StatusBLESettingsPriorityFBD__10 : 72|8@1+ (1.0,0) [0|252] "" IPB_App1
 SG_ StatusBLESettingsPriorityFBD__11 : 80|8@1+ (1,0) [0|0] "" IPB_App1
 SG_ StatusBLESettingsPriorityFBD__12 : 88|8@1+ (1.0,0) [0|252] "" IPB_App1
 SG_ StatusBLESettingsPriorityFBD__13 : 96|8@1+ (1,0) [0|0] "" IPB_App1
 SG_ StatusBLESettingsPriorityFBD__14 : 104|8@1+ (1.0,0) [0|252] "" IPB_App1
 SG_ StatusBLESettingsPriorityFBD__15 : 112|8@1+ (1,0) [0|0] "" IPB_App1
 SG_ StatusBLESettingsPriorityFBD__16 : 120|8@1+ (1.0,0) [0|252] "" IPB_App1
 SG_ StatusBLESettingsPriorityFBD__17 : 128|8@1+ (1,0) [0|0] "" IPB_App1

BO_ 394 StatusBLESettingsPriorityFBD_VL: 20 FBD_VL
 SG_ StatusBLESettingsPriorityFBD_VL_ : 0|8@1+ (1.0,0) [0|252] "" IPB_App1
 SG_ StatusBLESettingsPriorityFBD_V_2 : 8|8@1+ (1.0,0) [0|252] "" IPB_App1
 SG_ StatusBLESettingsPriorityFBD_V_3 : 16|8@1+ (1,0) [0|0] "" IPB_App1
 SG_ StatusBLESettingsPriorityFBD_V_4 : 24|8@1+ (1.0,0) [0|252] "" IPB_App1
 SG_ StatusBLESettingsPriorityFBD_V_5 : 32|8@1+ (1,0) [0|0] "" IPB_App1
 SG_ StatusBLESettingsPriorityFBD_V_6 : 40|8@1+ (1.0,0) [0|252] "" IPB_App1
 SG_ StatusBLESettingsPriorityFBD_V_7 : 48|8@1+ (1,0) [0|0] "" IPB_App1
 SG_ StatusBLESettingsPriorityFBD_V_8 : 56|8@1+ (1.0,0) [0|252] "" IPB_App1
 SG_ StatusBLESettingsPriorityFBD_V_9 : 64|8@1+ (1,0) [0|0] "" IPB_App1
 SG_ StatusBLESettingsPriorityFBD__10 : 72|8@1+ (1.0,0) [0|252] "" IPB_App1
 SG_ StatusBLESettingsPriorityFBD__11 : 80|8@1+ (1,0) [0|0] "" IPB_App1
 SG_ StatusBLESettingsPriorityFBD__12 : 88|8@1+ (1.0,0) [0|252] "" IPB_App1
 SG_ StatusBLESettingsPriorityFBD__13 : 96|8@1+ (1,0) [0|0] "" IPB_App1
 SG_ StatusBLESettingsPriorityFBD__14 : 104|8@1+ (1.0,0) [0|252] "" IPB_App1
 SG_ StatusBLESettingsPriorityFBD__15 : 112|8@1+ (1,0) [0|0] "" IPB_App1
 SG_ StatusBLESettingsPriorityFBD__16 : 120|8@1+ (1.0,0) [0|252] "" IPB_App1
 SG_ StatusBLESettingsPriorityFBD__17 : 128|8@1+ (1,0) [0|0] "" IPB_App1

BO_ 390 StatusBLESettingsPriorityFBD_VM: 20 FBD_VM
 SG_ StatusBLESettingsPriorityFBD_VM_ : 0|8@1+ (1.0,0) [0|252] "" IPB_App1
 SG_ StatusBLESettingsPriorityFBD_V_2 : 8|8@1+ (1.0,0) [0|252] "" IPB_App1
 SG_ StatusBLESettingsPriorityFBD_V_3 : 16|8@1+ (1,0) [0|0] "" IPB_App1
 SG_ StatusBLESettingsPriorityFBD_V_4 : 24|8@1+ (1.0,0) [0|252] "" IPB_App1
 SG_ StatusBLESettingsPriorityFBD_V_5 : 32|8@1+ (1,0) [0|0] "" IPB_App1
 SG_ StatusBLESettingsPriorityFBD_V_6 : 40|8@1+ (1.0,0) [0|252] "" IPB_App1
 SG_ StatusBLESettingsPriorityFBD_V_7 : 48|8@1+ (1,0) [0|0] "" IPB_App1
 SG_ StatusBLESettingsPriorityFBD_V_8 : 56|8@1+ (1.0,0) [0|252] "" IPB_App1
 SG_ StatusBLESettingsPriorityFBD_V_9 : 64|8@1+ (1,0) [0|0] "" IPB_App1
 SG_ StatusBLESettingsPriorityFBD__10 : 72|8@1+ (1.0,0) [0|252] "" IPB_App1
 SG_ StatusBLESettingsPriorityFBD__11 : 80|8@1+ (1,0) [0|0] "" IPB_App1
 SG_ StatusBLESettingsPriorityFBD__12 : 88|8@1+ (1.0,0) [0|252] "" IPB_App1
 SG_ StatusBLESettingsPriorityFBD__13 : 96|8@1+ (1,0) [0|0] "" IPB_App1
 SG_ StatusBLESettingsPriorityFBD__14 : 104|8@1+ (1.0,0) [0|252] "" IPB_App1
 SG_ StatusBLESettingsPriorityFBD__15 : 112|8@1+ (1,0) [0|0] "" IPB_App1
 SG_ StatusBLESettingsPriorityFBD__16 : 120|8@1+ (1.0,0) [0|252] "" IPB_App1
 SG_ StatusBLESettingsPriorityFBD__17 : 128|8@1+ (1,0) [0|0] "" IPB_App1

BO_ 395 StatusBLESettingsPriorityFBD_VR: 20 FBD_VR
 SG_ StatusBLESettingsPriorityFBD_VR_ : 0|8@1+ (1.0,0) [0|252] "" IPB_App1
 SG_ StatusBLESettingsPriorityFBD_V_2 : 8|8@1+ (1.0,0) [0|252] "" IPB_App1
 SG_ StatusBLESettingsPriorityFBD_V_3 : 16|8@1+ (1,0) [0|0] "" IPB_App1
 SG_ StatusBLESettingsPriorityFBD_V_4 : 24|8@1+ (1.0,0) [0|252] "" IPB_App1
 SG_ StatusBLESettingsPriorityFBD_V_5 : 32|8@1+ (1,0) [0|0] "" IPB_App1
 SG_ StatusBLESettingsPriorityFBD_V_6 : 40|8@1+ (1.0,0) [0|252] "" IPB_App1
 SG_ StatusBLESettingsPriorityFBD_V_7 : 48|8@1+ (1,0) [0|0] "" IPB_App1
 SG_ StatusBLESettingsPriorityFBD_V_8 : 56|8@1+ (1.0,0) [0|252] "" IPB_App1
 SG_ StatusBLESettingsPriorityFBD_V_9 : 64|8@1+ (1,0) [0|0] "" IPB_App1
 SG_ StatusBLESettingsPriorityFBD__10 : 72|8@1+ (1.0,0) [0|252] "" IPB_App1
 SG_ StatusBLESettingsPriorityFBD__11 : 80|8@1+ (1,0) [0|0] "" IPB_App1
 SG_ StatusBLESettingsPriorityFBD__12 : 88|8@1+ (1.0,0) [0|252] "" IPB_App1
 SG_ StatusBLESettingsPriorityFBD__13 : 96|8@1+ (1,0) [0|0] "" IPB_App1
 SG_ StatusBLESettingsPriorityFBD__14 : 104|8@1+ (1.0,0) [0|252] "" IPB_App1
 SG_ StatusBLESettingsPriorityFBD__15 : 112|8@1+ (1,0) [0|0] "" IPB_App1
 SG_ StatusBLESettingsPriorityFBD__16 : 120|8@1+ (1.0,0) [0|252] "" IPB_App1
 SG_ StatusBLESettingsPriorityFBD__17 : 128|8@1+ (1,0) [0|0] "" IPB_App1

BO_ 616 StatusConfigurationFBD_HL: 16 FBD_HL
 SG_ StatusConfigurationFBD_HL_UWBAnt : 0|8@1+ (1.0,0) [0|252] "" IPB_App1
 SG_ StatusConfigurationFBD_HL_UWBDut : 8|8@1+ (0.5,0) [0|126] "ms" IPB_App1
 SG_ StatusConfigurationFBD_HL_UWBD_2 : 16|8@1+ (0.1,0) [0|25.2] "s" IPB_App1
 SG_ StatusConfigurationFBD_HL_UWBD_3 : 24|8@1+ (0.5,0) [0|126] "ms" IPB_App1
 SG_ StatusConfigurationFBD_HL_FBDonl : 32|8@1+ (0.1,0) [0|25.2] "m" IPB_App1
 SG_ StatusConfigurationFBD_HL_FBDo_2 : 40|8@1+ (1,0) [0|0] "" IPB_App1
 SG_ StatusConfigurationFBD_HL_FBDo_3 : 48|8@1+ (1.0,0) [0|252] "s" IPB_App1
 SG_ StatusConfigurationFBD_HL_FBDo_4 : 56|8@1+ (1.0,0) [0|252] "" IPB_App1
 SG_ StatusConfigurationFBD_HL_FBDo_5 : 64|8@1+ (1.0,0) [0|252] "s" IPB_App1
 SG_ StatusConfigurationFBD_HL_FBDo_6 : 72|8@1+ (1.0,0) [0|252] "s" IPB_App1
 SG_ StatusConfigurationFBD_HL_FBDo_7 : 80|8@1+ (1.0,0) [0|252] "min" IPB_App1
 SG_ StatusConfigurationFBD_HL_FBDo_8 : 88|8@1+ (1.0,0) [0|255] "" IPB_App1
 SG_ StatusConfigurationFBD_HL_FBDo_9 : 96|8@1+ (1,0) [0|0] "" IPB_App1
 SG_ StatusConfigurationFBD_HL_Device : 104|8@1+ (1.0,0) [0|252] "" IPB_App1
 SG_ StatusConfigurationFBD_HL_IRKLis : 112|8@1+ (1.0,0) [0|252] "" IPB_App1

BO_ 611 StatusConfigurationFBD_HM: 16 FBD_HM
 SG_ StatusConfigurationFBD_HM_UWBAnt : 0|8@1+ (1.0,0) [0|252] "" IPB_App1
 SG_ StatusConfigurationFBD_HM_UWBDut : 8|8@1+ (0.5,0) [0|126] "ms" IPB_App1
 SG_ StatusConfigurationFBD_HM_UWBD_2 : 16|8@1+ (0.1,0) [0|25.2] "s" IPB_App1
 SG_ StatusConfigurationFBD_HM_UWBD_3 : 24|8@1+ (0.5,0) [0|126] "ms" IPB_App1
 SG_ StatusConfigurationFBD_HM_FBDonl : 32|8@1+ (0.1,0) [0|25.2] "m" IPB_App1
 SG_ StatusConfigurationFBD_HM_FBDo_2 : 40|8@1+ (1,0) [0|0] "" IPB_App1
 SG_ StatusConfigurationFBD_HM_FBDo_3 : 48|8@1+ (1.0,0) [0|252] "s" IPB_App1
 SG_ StatusConfigurationFBD_HM_FBDo_4 : 56|8@1+ (1.0,0) [0|252] "" IPB_App1
 SG_ StatusConfigurationFBD_HM_FBDo_5 : 64|8@1+ (1.0,0) [0|252] "s" IPB_App1
 SG_ StatusConfigurationFBD_HM_FBDo_6 : 72|8@1+ (1.0,0) [0|252] "s" IPB_App1
 SG_ StatusConfigurationFBD_HM_FBDo_7 : 80|8@1+ (1.0,0) [0|252] "min" IPB_App1
 SG_ StatusConfigurationFBD_HM_FBDo_8 : 88|8@1+ (1.0,0) [0|255] "" IPB_App1
 SG_ StatusConfigurationFBD_HM_FBDo_9 : 96|8@1+ (1,0) [0|0] "" IPB_App1
 SG_ StatusConfigurationFBD_HM_Device : 104|8@1+ (1.0,0) [0|252] "" IPB_App1
 SG_ StatusConfigurationFBD_HM_IRKLis : 112|8@1+ (1.0,0) [0|252] "" IPB_App1

BO_ 617 StatusConfigurationFBD_HR: 16 FBD_HR
 SG_ StatusConfigurationFBD_HR_UWBAnt : 0|8@1+ (1.0,0) [0|252] "" IPB_App1
 SG_ StatusConfigurationFBD_HR_UWBDut : 8|8@1+ (0.5,0) [0|126] "ms" IPB_App1
 SG_ StatusConfigurationFBD_HR_UWBD_2 : 16|8@1+ (0.1,0) [0|25.2] "s" IPB_App1
 SG_ StatusConfigurationFBD_HR_UWBD_3 : 24|8@1+ (0.5,0) [0|126] "ms" IPB_App1
 SG_ StatusConfigurationFBD_HR_FBDonl : 32|8@1+ (0.1,0) [0|25.2] "m" IPB_App1
 SG_ StatusConfigurationFBD_HR_FBDo_2 : 40|8@1+ (1,0) [0|0] "" IPB_App1
 SG_ StatusConfigurationFBD_HR_FBDo_3 : 48|8@1+ (1.0,0) [0|252] "s" IPB_App1
 SG_ StatusConfigurationFBD_HR_FBDo_4 : 56|8@1+ (1.0,0) [0|252] "" IPB_App1
 SG_ StatusConfigurationFBD_HR_FBDo_5 : 64|8@1+ (1.0,0) [0|252] "s" IPB_App1
 SG_ StatusConfigurationFBD_HR_FBDo_6 : 72|8@1+ (1.0,0) [0|252] "s" IPB_App1
 SG_ StatusConfigurationFBD_HR_FBDo_7 : 80|8@1+ (1.0,0) [0|252] "min" IPB_App1
 SG_ StatusConfigurationFBD_HR_FBDo_8 : 88|8@1+ (1.0,0) [0|255] "" IPB_App1
 SG_ StatusConfigurationFBD_HR_FBDo_9 : 96|8@1+ (1,0) [0|0] "" IPB_App1
 SG_ StatusConfigurationFBD_HR_Device : 104|8@1+ (1.0,0) [0|252] "" IPB_App1
 SG_ StatusConfigurationFBD_HR_IRKLis : 112|8@1+ (1.0,0) [0|252] "" IPB_App1

BO_ 612 StatusConfigurationFBD_Miko: 16 FBD_Miko
 SG_ StatusConfigurationFBD_Miko_UWBA : 0|8@1+ (1.0,0) [0|252] "" IPB_App1
 SG_ StatusConfigurationFBD_Miko_UWBD : 8|8@1+ (0.5,0) [0|126] "ms" IPB_App1
 SG_ StatusConfigurationFBD_Miko_UW_2 : 16|8@1+ (0.1,0) [0|25.2] "s" IPB_App1
 SG_ StatusConfigurationFBD_Miko_UW_3 : 24|8@1+ (0.5,0) [0|126] "ms" IPB_App1
 SG_ StatusConfigurationFBD_Miko_FBDo : 32|8@1+ (0.1,0) [0|25.2] "m" IPB_App1
 SG_ StatusConfigurationFBD_Miko_FB_2 : 40|8@1+ (1,0) [0|0] "" IPB_App1
 SG_ StatusConfigurationFBD_Miko_FB_3 : 48|8@1+ (1.0,0) [0|252] "s" IPB_App1
 SG_ StatusConfigurationFBD_Miko_FB_4 : 56|8@1+ (1.0,0) [0|252] "" IPB_App1
 SG_ StatusConfigurationFBD_Miko_FB_5 : 64|8@1+ (1.0,0) [0|252] "s" IPB_App1
 SG_ StatusConfigurationFBD_Miko_FB_6 : 72|8@1+ (1.0,0) [0|252] "s" IPB_App1
 SG_ StatusConfigurationFBD_Miko_FB_7 : 80|8@1+ (1.0,0) [0|252] "min" IPB_App1
 SG_ StatusConfigurationFBD_Miko_FB_8 : 88|8@1+ (1.0,0) [0|255] "" IPB_App1
 SG_ StatusConfigurationFBD_Miko_FB_9 : 96|8@1+ (1,0) [0|0] "" IPB_App1
 SG_ StatusConfigurationFBD_Miko_Devi : 104|8@1+ (1.0,0) [0|252] "" IPB_App1
 SG_ StatusConfigurationFBD_Miko_IRKL : 112|8@1+ (1.0,0) [0|252] "" IPB_App1

BO_ 691 StatusConfigurationFBD_MM: 16 FBD_MM
 SG_ StatusConfigurationFBD_MM_UWBAnt : 0|8@1+ (1.0,0) [0|252] "" IPB_App1
 SG_ StatusConfigurationFBD_MM_UWBDut : 8|8@1+ (0.5,0) [0|126] "ms" IPB_App1
 SG_ StatusConfigurationFBD_MM_UWBD_2 : 16|8@1+ (0.1,0) [0|25.2] "s" IPB_App1
 SG_ StatusConfigurationFBD_MM_UWBD_3 : 24|8@1+ (0.5,0) [0|126] "ms" IPB_App1
 SG_ StatusConfigurationFBD_MM_FBDonl : 32|8@1+ (0.1,0) [0|25.2] "m" IPB_App1
 SG_ StatusConfigurationFBD_MM_FBDo_2 : 40|8@1+ (1,0) [0|0] "" IPB_App1
 SG_ StatusConfigurationFBD_MM_FBDo_3 : 48|8@1+ (1.0,0) [0|252] "s" IPB_App1
 SG_ StatusConfigurationFBD_MM_FBDo_4 : 56|8@1+ (1.0,0) [0|252] "s" IPB_App1
 SG_ StatusConfigurationFBD_MM_FBDo_5 : 64|8@1+ (1.0,0) [0|252] "s" IPB_App1
 SG_ StatusConfigurationFBD_MM_FBDo_6 : 72|8@1+ (1.0,0) [0|252] "s" IPB_App1
 SG_ StatusConfigurationFBD_MM_FBDo_7 : 80|8@1+ (1.0,0) [0|252] "min" IPB_App1
 SG_ StatusConfigurationFBD_MM_FBDo_8 : 88|8@1+ (1.0,0) [0|255] "" IPB_App1
 SG_ StatusConfigurationFBD_MM_FBDo_9 : 96|8@1+ (1,0) [0|0] "" IPB_App1
 SG_ StatusConfigurationFBD_MM_Device : 104|8@1+ (1.0,0) [0|252] "" IPB_App1
 SG_ StatusConfigurationFBD_MM_IRKLis : 112|8@1+ (1.0,0) [0|252] "" IPB_App1

BO_ 613 StatusConfigurationFBD_Trunk: 16 FBD_Trunk
 SG_ StatusConfigurationFBD_Trunk_UWB : 0|8@1+ (1.0,0) [0|252] "" IPB_App1
 SG_ StatusConfigurationFBD_Trunk_U_2 : 8|8@1+ (0.5,0) [0|126] "ms" IPB_App1
 SG_ StatusConfigurationFBD_Trunk_U_3 : 16|8@1+ (0.1,0) [0|25.2] "s" IPB_App1
 SG_ StatusConfigurationFBD_Trunk_U_4 : 24|8@1+ (0.5,0) [0|126] "ms" IPB_App1
 SG_ StatusConfigurationFBD_Trunk_FBD : 32|8@1+ (0.1,0) [0|25.2] "m" IPB_App1
 SG_ StatusConfigurationFBD_Trunk_F_2 : 40|8@1+ (1,0) [0|0] "" IPB_App1
 SG_ StatusConfigurationFBD_Trunk_F_3 : 48|8@1+ (1.0,0) [0|252] "s" IPB_App1
 SG_ StatusConfigurationFBD_Trunk_F_4 : 56|8@1+ (1.0,0) [0|252] "" IPB_App1
 SG_ StatusConfigurationFBD_Trunk_F_5 : 64|8@1+ (1.0,0) [0|252] "s" IPB_App1
 SG_ StatusConfigurationFBD_Trunk_F_6 : 72|8@1+ (1.0,0) [0|252] "s" IPB_App1
 SG_ StatusConfigurationFBD_Trunk_F_7 : 80|8@1+ (1.0,0) [0|252] "min" IPB_App1
 SG_ StatusConfigurationFBD_Trunk_F_8 : 88|8@1+ (1.0,0) [0|255] "" IPB_App1
 SG_ StatusConfigurationFBD_Trunk_F_9 : 96|8@1+ (1,0) [0|0] "" IPB_App1
 SG_ StatusConfigurationFBD_Trunk_Dev : 104|8@1+ (1.0,0) [0|252] "" IPB_App1
 SG_ StatusConfigurationFBD_Trunk_IRK : 112|8@1+ (1.0,0) [0|252] "" IPB_App1

BO_ 614 StatusConfigurationFBD_VL: 16 FBD_VL
 SG_ StatusConfigurationFBD_VL_UWBAnt : 0|8@1+ (1.0,0) [0|252] "" IPB_App1
 SG_ StatusConfigurationFBD_VL_UWBDut : 8|8@1+ (0.5,0) [0|126] "ms" IPB_App1
 SG_ StatusConfigurationFBD_VL_UWBD_2 : 16|8@1+ (0.1,0) [0|25.2] "s" IPB_App1
 SG_ StatusConfigurationFBD_VL_UWBD_3 : 24|8@1+ (0.5,0) [0|126] "ms" IPB_App1
 SG_ StatusConfigurationFBD_VL_FBDonl : 32|8@1+ (0.1,0) [0|25.2] "m" IPB_App1
 SG_ StatusConfigurationFBD_VL_FBDo_2 : 40|8@1+ (1,0) [0|0] "" IPB_App1
 SG_ StatusConfigurationFBD_VL_FBDo_3 : 48|8@1+ (1.0,0) [0|252] "s" IPB_App1
 SG_ StatusConfigurationFBD_VL_FBDo_4 : 56|8@1+ (1.0,0) [0|252] "" IPB_App1
 SG_ StatusConfigurationFBD_VL_FBDo_5 : 64|8@1+ (1.0,0) [0|252] "s" IPB_App1
 SG_ StatusConfigurationFBD_VL_FBDo_6 : 72|8@1+ (1.0,0) [0|252] "s" IPB_App1
 SG_ StatusConfigurationFBD_VL_FBDo_7 : 80|8@1+ (1.0,0) [0|252] "min" IPB_App1
 SG_ StatusConfigurationFBD_VL_FBDo_8 : 88|8@1+ (1.0,0) [0|255] "" IPB_App1
 SG_ StatusConfigurationFBD_VL_FBDo_9 : 96|8@1+ (1,0) [0|0] "" IPB_App1
 SG_ StatusConfigurationFBD_VL_Device : 104|8@1+ (1.0,0) [0|252] "" IPB_App1
 SG_ StatusConfigurationFBD_VL_IRKLis : 112|8@1+ (1.0,0) [0|252] "" IPB_App1

BO_ 610 StatusConfigurationFBD_VM: 16 FBD_VM
 SG_ StatusConfigurationFBD_VM_UWBAnt : 0|8@1+ (1.0,0) [0|252] "" IPB_App1
 SG_ StatusConfigurationFBD_VM_UWBDut : 8|8@1+ (0.5,0) [0|126] "ms" IPB_App1
 SG_ StatusConfigurationFBD_VM_UWBD_2 : 16|8@1+ (0.1,0) [0|25.2] "s" IPB_App1
 SG_ StatusConfigurationFBD_VM_UWBD_3 : 24|8@1+ (0.5,0) [0|126] "ms" IPB_App1
 SG_ StatusConfigurationFBD_VM_FBDonl : 32|8@1+ (0.1,0) [0|25.2] "m" IPB_App1
 SG_ StatusConfigurationFBD_VM_FBDo_2 : 40|8@1+ (1,0) [0|0] "" IPB_App1
 SG_ StatusConfigurationFBD_VM_FBDo_3 : 48|8@1+ (1.0,0) [0|252] "s" IPB_App1
 SG_ StatusConfigurationFBD_VM_FBDo_4 : 56|8@1+ (1.0,0) [0|252] "" IPB_App1
 SG_ StatusConfigurationFBD_VM_FBDo_5 : 64|8@1+ (1.0,0) [0|252] "s" IPB_App1
 SG_ StatusConfigurationFBD_VM_FBDo_6 : 72|8@1+ (1.0,0) [0|252] "s" IPB_App1
 SG_ StatusConfigurationFBD_VM_FBDo_7 : 80|8@1+ (1.0,0) [0|252] "min" IPB_App1
 SG_ StatusConfigurationFBD_VM_FBDo_8 : 88|8@1+ (1.0,0) [0|255] "" IPB_App1
 SG_ StatusConfigurationFBD_VM_FBDo_9 : 96|8@1+ (1,0) [0|0] "" IPB_App1
 SG_ StatusConfigurationFBD_VM_Device : 104|8@1+ (1.0,0) [0|252] "" IPB_App1
 SG_ StatusConfigurationFBD_VM_IRKLis : 112|8@1+ (1.0,0) [0|252] "" IPB_App1

BO_ 615 StatusConfigurationFBD_VR: 16 FBD_VR
 SG_ StatusConfigurationFBD_VR_UWBAnt : 0|8@1+ (1.0,0) [0|252] "" IPB_App1
 SG_ StatusConfigurationFBD_VR_UWBDut : 8|8@1+ (0.5,0) [0|126] "ms" IPB_App1
 SG_ StatusConfigurationFBD_VR_UWBD_2 : 16|8@1+ (0.1,0) [0|25.2] "s" IPB_App1
 SG_ StatusConfigurationFBD_VR_UWBD_3 : 24|8@1+ (0.5,0) [0|126] "ms" IPB_App1
 SG_ StatusConfigurationFBD_VR_FBDonl : 32|8@1+ (0.1,0) [0|25.2] "m" IPB_App1
 SG_ StatusConfigurationFBD_VR_FBDo_2 : 40|8@1+ (1,0) [0|0] "" IPB_App1
 SG_ StatusConfigurationFBD_VR_FBDo_3 : 48|8@1+ (1.0,0) [0|252] "s" IPB_App1
 SG_ StatusConfigurationFBD_VR_FBDo_4 : 56|8@1+ (1.0,0) [0|252] "" IPB_App1
 SG_ StatusConfigurationFBD_VR_FBDo_5 : 64|8@1+ (1.0,0) [0|252] "s" IPB_App1
 SG_ StatusConfigurationFBD_VR_FBDo_6 : 72|8@1+ (1.0,0) [0|252] "s" IPB_App1
 SG_ StatusConfigurationFBD_VR_FBDo_7 : 80|8@1+ (1.0,0) [0|252] "min" IPB_App1
 SG_ StatusConfigurationFBD_VR_FBDo_8 : 88|8@1+ (1.0,0) [0|255] "" IPB_App1
 SG_ StatusConfigurationFBD_VR_FBDo_9 : 96|8@1+ (1,0) [0|0] "" IPB_App1
 SG_ StatusConfigurationFBD_VR_Device : 104|8@1+ (1.0,0) [0|252] "" IPB_App1
 SG_ StatusConfigurationFBD_VR_IRKLis : 112|8@1+ (1.0,0) [0|252] "" IPB_App1

BO_ 636 StatusCoordinatesFBD_HL: 12 FBD_HL
 SG_ StatusCoordinatesFBD_HL_BodyFron : 0|10@1+ (1.0,-250) [-250|770] "cm" IPB_App1
 SG_ StatusCoordinatesFBD_HL_BodyFr_2 : 10|10@1+ (1.0,-250) [-250|770] "cm" IPB_App1
 SG_ StatusCoordinatesFBD_HL_BodyRear : 20|10@1+ (1.0,-250) [-250|770] "cm" IPB_App1
 SG_ StatusCoordinatesFBD_HL_BodyRe_2 : 30|10@1+ (1.0,-250) [-250|770] "cm" IPB_App1
 SG_ StatusCoordinatesFBD_HL_X : 40|10@1+ (1.0,-250) [-250|770] "cm" IPB_App1
 SG_ StatusCoordinatesFBD_HL_Y : 50|10@1+ (1.0,-250) [-250|770] "cm" IPB_App1
 SG_ StatusCoordinatesFBD_HL_Z : 60|10@1+ (1.0,-250) [-250|770] "cm" IPB_App1
 SG_ StatusCoordinatesFBD_HL_azimuth : 70|9@1+ (1.0,-180) [-180|180] "°" IPB_App1
 SG_ StatusCoordinatesFBD_HL_elevatio : 79|8@1+ (1.0,-100) [-100|100] "°" IPB_App1
 SG_ StatusCoordinatesFBD_HL_InvalidC : 88|8@1+ (1.0,0) [0|252] "" IPB_App1

BO_ 631 StatusCoordinatesFBD_HM: 12 FBD_HM
 SG_ StatusCoordinatesFBD_HM_BodyFron : 0|10@1+ (1.0,-250) [-250|770] "cm" IPB_App1
 SG_ StatusCoordinatesFBD_HM_BodyFr_2 : 10|10@1+ (1.0,-250) [-250|770] "cm" IPB_App1
 SG_ StatusCoordinatesFBD_HM_BodyRear : 20|10@1+ (1.0,-250) [-250|770] "cm" IPB_App1
 SG_ StatusCoordinatesFBD_HM_BodyRe_2 : 30|10@1+ (1.0,-250) [-250|770] "cm" IPB_App1
 SG_ StatusCoordinatesFBD_HM_X : 40|10@1+ (1.0,-250) [-250|770] "cm" IPB_App1
 SG_ StatusCoordinatesFBD_HM_Y : 50|10@1+ (1.0,-250) [-250|770] "cm" IPB_App1
 SG_ StatusCoordinatesFBD_HM_Z : 60|10@1+ (1.0,-250) [-250|770] "cm" IPB_App1
 SG_ StatusCoordinatesFBD_HM_azimuth : 70|9@1+ (1.0,-180) [-180|180] "°" IPB_App1
 SG_ StatusCoordinatesFBD_HM_elevatio : 79|8@1+ (1.0,-100) [-100|100] "°" IPB_App1
 SG_ StatusCoordinatesFBD_HM_InvalidC : 88|8@1+ (1.0,0) [0|252] "" IPB_App1

BO_ 637 StatusCoordinatesFBD_HR: 12 FBD_HR
 SG_ StatusCoordinatesFBD_HR_BodyFron : 0|10@1+ (1.0,-250) [-250|770] "cm" IPB_App1
 SG_ StatusCoordinatesFBD_HR_BodyFr_2 : 10|10@1+ (1.0,-250) [-250|770] "cm" IPB_App1
 SG_ StatusCoordinatesFBD_HR_BodyRear : 20|10@1+ (1.0,-250) [-250|770] "cm" IPB_App1
 SG_ StatusCoordinatesFBD_HR_BodyRe_2 : 30|10@1+ (1.0,-250) [-250|770] "cm" IPB_App1
 SG_ StatusCoordinatesFBD_HR_X : 40|10@1+ (1.0,-250) [-250|770] "cm" IPB_App1
 SG_ StatusCoordinatesFBD_HR_Y : 50|10@1+ (1.0,-250) [-250|770] "cm" IPB_App1
 SG_ StatusCoordinatesFBD_HR_Z : 60|10@1+ (1.0,-250) [-250|770] "cm" IPB_App1
 SG_ StatusCoordinatesFBD_HR_azimuth : 70|9@1+ (1.0,-180) [-180|180] "°" IPB_App1
 SG_ StatusCoordinatesFBD_HR_elevatio : 79|8@1+ (1.0,-100) [-100|100] "°" IPB_App1
 SG_ StatusCoordinatesFBD_HR_InvalidC : 88|8@1+ (1.0,0) [0|252] "" IPB_App1

BO_ 632 StatusCoordinatesFBD_Miko: 12 FBD_Miko
 SG_ StatusCoordinatesFBD_Miko_BodyFr : 0|10@1+ (1.0,-250) [-250|770] "cm" IPB_App1
 SG_ StatusCoordinatesFBD_Miko_Body_2 : 10|10@1+ (1.0,-250) [-250|770] "cm" IPB_App1
 SG_ StatusCoordinatesFBD_Miko_BodyRe : 20|10@1+ (1.0,-250) [-250|770] "cm" IPB_App1
 SG_ StatusCoordinatesFBD_Miko_Body_3 : 30|10@1+ (1.0,-250) [-250|770] "cm" IPB_App1
 SG_ StatusCoordinatesFBD_Miko_X : 40|10@1+ (1.0,-250) [-250|770] "cm" IPB_App1
 SG_ StatusCoordinatesFBD_Miko_Y : 50|10@1+ (1.0,-250) [-250|770] "cm" IPB_App1
 SG_ StatusCoordinatesFBD_Miko_Z : 60|10@1+ (1.0,-250) [-250|770] "cm" IPB_App1
 SG_ StatusCoordinatesFBD_Miko_azimut : 70|9@1+ (1.0,-180) [-180|180] "°" IPB_App1
 SG_ StatusCoordinatesFBD_Miko_elevat : 79|8@1+ (1.0,-100) [-100|100] "°" IPB_App1
 SG_ StatusCoordinatesFBD_Miko_Invali : 88|8@1+ (1.0,0) [0|252] "" IPB_App1

BO_ 692 StatusCoordinatesFBD_MM: 12 FBD_MM
 SG_ StatusCoordinatesFBD_MM_BodyFron : 0|10@1+ (1.0,-250) [-250|770] "cm" IPB_App1
 SG_ StatusCoordinatesFBD_MM_BodyFr_2 : 10|10@1+ (1.0,-250) [-250|770] "cm" IPB_App1
 SG_ StatusCoordinatesFBD_MM_BodyRear : 20|10@1+ (1.0,-250) [-250|770] "cm" IPB_App1
 SG_ StatusCoordinatesFBD_MM_BodyRe_2 : 30|10@1+ (1.0,-250) [-250|770] "cm" IPB_App1
 SG_ StatusCoordinatesFBD_MM_X : 40|10@1+ (1.0,-250) [-250|770] "cm" IPB_App1
 SG_ StatusCoordinatesFBD_MM_Y : 50|10@1+ (1.0,-250) [-250|770] "cm" IPB_App1
 SG_ StatusCoordinatesFBD_MM_Z : 60|10@1+ (1.0,-250) [-250|770] "cm" IPB_App1
 SG_ StatusCoordinatesFBD_MM_azimuth : 70|9@1+ (1.0,-180) [-180|180] "°" IPB_App1
 SG_ StatusCoordinatesFBD_MM_elevatio : 79|8@1+ (1.0,-100) [-100|100] "°" IPB_App1
 SG_ StatusCoordinatesFBD_MM_InvalidC : 88|8@1+ (1.0,0) [0|252] "" IPB_App1

BO_ 633 StatusCoordinatesFBD_Trunk: 12 FBD_Trunk
 SG_ StatusCoordinatesFBD_Trunk_BodyF : 0|10@1+ (1.0,-250) [-250|770] "cm" IPB_App1
 SG_ StatusCoordinatesFBD_Trunk_Bod_2 : 10|10@1+ (1.0,-250) [-250|770] "cm" IPB_App1
 SG_ StatusCoordinatesFBD_Trunk_BodyR : 20|10@1+ (1.0,-250) [-250|770] "cm" IPB_App1
 SG_ StatusCoordinatesFBD_Trunk_Bod_3 : 30|10@1+ (1.0,-250) [-250|770] "cm" IPB_App1
 SG_ StatusCoordinatesFBD_Trunk_X : 40|10@1+ (1.0,-250) [-250|770] "cm" IPB_App1
 SG_ StatusCoordinatesFBD_Trunk_Y : 50|10@1+ (1.0,-250) [-250|770] "cm" IPB_App1
 SG_ StatusCoordinatesFBD_Trunk_Z : 60|10@1+ (1.0,-250) [-250|770] "cm" IPB_App1
 SG_ StatusCoordinatesFBD_Trunk_azimu : 70|9@1+ (1.0,-180) [-180|180] "°" IPB_App1
 SG_ StatusCoordinatesFBD_Trunk_eleva : 79|8@1+ (1.0,-100) [-100|100] "°" IPB_App1
 SG_ StatusCoordinatesFBD_Trunk_Inval : 88|8@1+ (1.0,0) [0|252] "" IPB_App1

BO_ 634 StatusCoordinatesFBD_VL: 12 FBD_VL
 SG_ StatusCoordinatesFBD_VL_BodyFron : 0|10@1+ (1.0,-250) [-250|770] "cm" IPB_App1
 SG_ StatusCoordinatesFBD_VL_BodyFr_2 : 10|10@1+ (1.0,-250) [-250|770] "cm" IPB_App1
 SG_ StatusCoordinatesFBD_VL_BodyRear : 20|10@1+ (1.0,-250) [-250|770] "cm" IPB_App1
 SG_ StatusCoordinatesFBD_VL_BodyRe_2 : 30|10@1+ (1.0,-250) [-250|770] "cm" IPB_App1
 SG_ StatusCoordinatesFBD_VL_X : 40|10@1+ (1.0,-250) [-250|770] "cm" IPB_App1
 SG_ StatusCoordinatesFBD_VL_Y : 50|10@1+ (1.0,-250) [-250|770] "cm" IPB_App1
 SG_ StatusCoordinatesFBD_VL_Z : 60|10@1+ (1.0,-250) [-250|770] "cm" IPB_App1
 SG_ StatusCoordinatesFBD_VL_azimuth : 70|9@1+ (1.0,-180) [-180|180] "°" IPB_App1
 SG_ StatusCoordinatesFBD_VL_elevatio : 79|8@1+ (1.0,-100) [-100|100] "°" IPB_App1
 SG_ StatusCoordinatesFBD_VL_InvalidC : 88|8@1+ (1.0,0) [0|252] "" IPB_App1

BO_ 630 StatusCoordinatesFBD_VM: 12 FBD_VM
 SG_ StatusCoordinatesFBD_VM_BodyFron : 0|10@1+ (1.0,-250) [-250|770] "cm" IPB_App1
 SG_ StatusCoordinatesFBD_VM_BodyFr_2 : 10|10@1+ (1.0,-250) [-250|770] "cm" IPB_App1
 SG_ StatusCoordinatesFBD_VM_BodyRear : 20|10@1+ (1.0,-250) [-250|770] "cm" IPB_App1
 SG_ StatusCoordinatesFBD_VM_BodyRe_2 : 30|10@1+ (1.0,-250) [-250|770] "cm" IPB_App1
 SG_ StatusCoordinatesFBD_VM_X : 40|10@1+ (1.0,-250) [-250|770] "cm" IPB_App1
 SG_ StatusCoordinatesFBD_VM_Y : 50|10@1+ (1.0,-250) [-250|770] "cm" IPB_App1
 SG_ StatusCoordinatesFBD_VM_Z : 60|10@1+ (1.0,-250) [-250|770] "cm" IPB_App1
 SG_ StatusCoordinatesFBD_VM_azimuth : 70|9@1+ (1.0,-180) [-180|180] "°" IPB_App1
 SG_ StatusCoordinatesFBD_VM_elevatio : 79|8@1+ (1.0,-100) [-100|100] "°" IPB_App1
 SG_ StatusCoordinatesFBD_VM_InvalidC : 88|8@1+ (1.0,0) [0|252] "" IPB_App1

BO_ 635 StatusCoordinatesFBD_VR: 12 FBD_VR
 SG_ StatusCoordinatesFBD_VR_BodyFron : 0|10@1+ (1.0,-250) [-250|770] "cm" IPB_App1
 SG_ StatusCoordinatesFBD_VR_BodyFr_2 : 10|10@1+ (1.0,-250) [-250|770] "cm" IPB_App1
 SG_ StatusCoordinatesFBD_VR_BodyRear : 20|10@1+ (1.0,-250) [-250|770] "cm" IPB_App1
 SG_ StatusCoordinatesFBD_VR_BodyRe_2 : 30|10@1+ (1.0,-250) [-250|770] "cm" IPB_App1
 SG_ StatusCoordinatesFBD_VR_X : 40|10@1+ (1.0,-250) [-250|770] "cm" IPB_App1
 SG_ StatusCoordinatesFBD_VR_Y : 50|10@1+ (1.0,-250) [-250|770] "cm" IPB_App1
 SG_ StatusCoordinatesFBD_VR_Z : 60|10@1+ (1.0,-250) [-250|770] "cm" IPB_App1
 SG_ StatusCoordinatesFBD_VR_azimuth : 70|9@1+ (1.0,-180) [-180|180] "°" IPB_App1
 SG_ StatusCoordinatesFBD_VR_elevatio : 79|8@1+ (1.0,-100) [-100|100] "°" IPB_App1
 SG_ StatusCoordinatesFBD_VR_InvalidC : 88|8@1+ (1.0,0) [0|252] "" IPB_App1

BO_ 336 StatusCPDData1FBD_HL: 64 FBD_HL
 SG_ StatusCPDData1FBD_HL_MsgCounter : 0|8@1+ (1.0,0) [0|252] "" IPB_App1
 SG_ StatusCPDData1FBD_HL_LinkID : 8|8@1+ (1.0,0) [0|252] "" IPB_App1
 SG_ StatusCPDData1FBD_HL_AGCValue : 16|8@1+ (1.0,0) [0|252] "" IPB_App1
 SG_ StatusCPDData1FBD_HL_Channel : 24|8@1+ (1.0,0) [0|252] "" IPB_App1
 SG_ StatusCPDData1FBD_HL_CIRData00 : 32|8@1+ (1.0,0) [0|255] "" IPB_App1
 SG_ StatusCPDData1FBD_HL_CIRData01 : 40|8@1+ (1.0,0) [0|255] "" IPB_App1
 SG_ StatusCPDData1FBD_HL_CIRData02 : 48|8@1+ (1.0,0) [0|255] "" IPB_App1
 SG_ StatusCPDData1FBD_HL_CIRData03 : 56|8@1+ (1.0,0) [0|255] "" IPB_App1
 SG_ StatusCPDData1FBD_HL_CIRData04 : 64|8@1+ (1.0,0) [0|255] "" IPB_App1
 SG_ StatusCPDData1FBD_HL_CIRData05 : 72|8@1+ (1.0,0) [0|255] "" IPB_App1
 SG_ StatusCPDData1FBD_HL_CIRData06 : 80|8@1+ (1.0,0) [0|255] "" IPB_App1
 SG_ StatusCPDData1FBD_HL_CIRData07 : 88|8@1+ (1.0,0) [0|255] "" IPB_App1
 SG_ StatusCPDData1FBD_HL_CIRData08 : 96|8@1+ (1.0,0) [0|255] "" IPB_App1
 SG_ StatusCPDData1FBD_HL_CIRData09 : 104|8@1+ (1.0,0) [0|255] "" IPB_App1
 SG_ StatusCPDData1FBD_HL_CIRData10 : 112|8@1+ (1.0,0) [0|255] "" IPB_App1
 SG_ StatusCPDData1FBD_HL_CIRData11 : 120|8@1+ (1.0,0) [0|255] "" IPB_App1
 SG_ StatusCPDData1FBD_HL_CIRData12 : 128|8@1+ (1.0,0) [0|255] "" IPB_App1
 SG_ StatusCPDData1FBD_HL_CIRData13 : 136|8@1+ (1.0,0) [0|255] "" IPB_App1
 SG_ StatusCPDData1FBD_HL_CIRData14 : 144|8@1+ (1.0,0) [0|255] "" IPB_App1
 SG_ StatusCPDData1FBD_HL_CIRData15 : 152|8@1+ (1.0,0) [0|255] "" IPB_App1
 SG_ StatusCPDData1FBD_HL_CIRData16 : 160|8@1+ (1.0,0) [0|255] "" IPB_App1
 SG_ StatusCPDData1FBD_HL_CIRData17 : 168|8@1+ (1.0,0) [0|255] "" IPB_App1
 SG_ StatusCPDData1FBD_HL_CIRData18 : 176|8@1+ (1.0,0) [0|255] "" IPB_App1
 SG_ StatusCPDData1FBD_HL_CIRData19 : 184|8@1+ (1.0,0) [0|255] "" IPB_App1
 SG_ StatusCPDData1FBD_HL_CIRData20 : 192|8@1+ (1.0,0) [0|255] "" IPB_App1
 SG_ StatusCPDData1FBD_HL_CIRData21 : 200|8@1+ (1.0,0) [0|255] "" IPB_App1
 SG_ StatusCPDData1FBD_HL_CIRData22 : 208|8@1+ (1.0,0) [0|255] "" IPB_App1
 SG_ StatusCPDData1FBD_HL_CIRData23 : 216|8@1+ (1.0,0) [0|255] "" IPB_App1
 SG_ StatusCPDData1FBD_HL_CIRData24 : 224|8@1+ (1.0,0) [0|255] "" IPB_App1
 SG_ StatusCPDData1FBD_HL_CIRData25 : 232|8@1+ (1.0,0) [0|255] "" IPB_App1
 SG_ StatusCPDData1FBD_HL_CIRData26 : 240|8@1+ (1.0,0) [0|255] "" IPB_App1
 SG_ StatusCPDData1FBD_HL_CIRData27 : 248|8@1+ (1.0,0) [0|255] "" IPB_App1
 SG_ StatusCPDData1FBD_HL_CIRData28 : 256|8@1+ (1.0,0) [0|255] "" IPB_App1
 SG_ StatusCPDData1FBD_HL_CIRData29 : 264|8@1+ (1.0,0) [0|255] "" IPB_App1
 SG_ StatusCPDData1FBD_HL_CIRData30 : 272|8@1+ (1.0,0) [0|255] "" IPB_App1
 SG_ StatusCPDData1FBD_HL_CIRData31 : 280|8@1+ (1.0,0) [0|255] "" IPB_App1
 SG_ StatusCPDData1FBD_HL_CIRData32 : 288|8@1+ (1.0,0) [0|255] "" IPB_App1
 SG_ StatusCPDData1FBD_HL_CIRData33 : 296|8@1+ (1.0,0) [0|255] "" IPB_App1
 SG_ StatusCPDData1FBD_HL_CIRData34 : 304|8@1+ (1.0,0) [0|255] "" IPB_App1
 SG_ StatusCPDData1FBD_HL_CIRData35 : 312|8@1+ (1.0,0) [0|255] "" IPB_App1
 SG_ StatusCPDData1FBD_HL_CIRData36 : 320|8@1+ (1.0,0) [0|255] "" IPB_App1
 SG_ StatusCPDData1FBD_HL_CIRData37 : 328|8@1+ (1.0,0) [0|255] "" IPB_App1
 SG_ StatusCPDData1FBD_HL_CIRData38 : 336|8@1+ (1.0,0) [0|255] "" IPB_App1
 SG_ StatusCPDData1FBD_HL_CIRData39 : 344|8@1+ (1.0,0) [0|255] "" IPB_App1
 SG_ StatusCPDData1FBD_HL_CIRData40 : 352|8@1+ (1.0,0) [0|255] "" IPB_App1
 SG_ StatusCPDData1FBD_HL_CIRData41 : 360|8@1+ (1.0,0) [0|255] "" IPB_App1
 SG_ StatusCPDData1FBD_HL_CIRData42 : 368|8@1+ (1.0,0) [0|255] "" IPB_App1
 SG_ StatusCPDData1FBD_HL_CIRData43 : 376|8@1+ (1.0,0) [0|255] "" IPB_App1
 SG_ StatusCPDData1FBD_HL_CIRData44 : 384|8@1+ (1.0,0) [0|255] "" IPB_App1
 SG_ StatusCPDData1FBD_HL_CIRData45 : 392|8@1+ (1.0,0) [0|255] "" IPB_App1
 SG_ StatusCPDData1FBD_HL_CIRData46 : 400|8@1+ (1.0,0) [0|255] "" IPB_App1
 SG_ StatusCPDData1FBD_HL_CIRData47 : 408|8@1+ (1.0,0) [0|255] "" IPB_App1
 SG_ StatusCPDData1FBD_HL_CIRData48 : 416|8@1+ (1.0,0) [0|255] "" IPB_App1
 SG_ StatusCPDData1FBD_HL_CIRData49 : 424|8@1+ (1.0,0) [0|255] "" IPB_App1
 SG_ StatusCPDData1FBD_HL_CIRData50 : 432|8@1+ (1.0,0) [0|255] "" IPB_App1
 SG_ StatusCPDData1FBD_HL_CIRData51 : 440|8@1+ (1.0,0) [0|255] "" IPB_App1
 SG_ StatusCPDData1FBD_HL_CIRData52 : 448|8@1+ (1.0,0) [0|255] "" IPB_App1
 SG_ StatusCPDData1FBD_HL_CIRData53 : 456|8@1+ (1.0,0) [0|255] "" IPB_App1
 SG_ StatusCPDData1FBD_HL_CIRData54 : 464|8@1+ (1.0,0) [0|255] "" IPB_App1
 SG_ StatusCPDData1FBD_HL_CIRData55 : 472|8@1+ (1.0,0) [0|255] "" IPB_App1
 SG_ StatusCPDData1FBD_HL_CIRData56 : 480|8@1+ (1.0,0) [0|255] "" IPB_App1
 SG_ StatusCPDData1FBD_HL_CIRData57 : 488|8@1+ (1.0,0) [0|255] "" IPB_App1
 SG_ StatusCPDData1FBD_HL_CIRData58 : 496|8@1+ (1.0,0) [0|255] "" IPB_App1
 SG_ StatusCPDData1FBD_HL_CIRData59 : 504|8@1+ (1.0,0) [0|255] "" IPB_App1

BO_ 331 StatusCPDData1FBD_HM: 64 FBD_HM
 SG_ StatusCPDData1FBD_HM_MsgCounter : 0|8@1+ (1.0,0) [0|252] "" IPB_App1
 SG_ StatusCPDData1FBD_HM_LinkID : 8|8@1+ (1.0,0) [0|252] "" IPB_App1
 SG_ StatusCPDData1FBD_HM_AGCValue : 16|8@1+ (1.0,0) [0|252] "" IPB_App1
 SG_ StatusCPDData1FBD_HM_Channel : 24|8@1+ (1.0,0) [0|252] "" IPB_App1
 SG_ StatusCPDData1FBD_HM_CIRData00 : 32|8@1+ (1.0,0) [0|255] "" IPB_App1
 SG_ StatusCPDData1FBD_HM_CIRData01 : 40|8@1+ (1.0,0) [0|255] "" IPB_App1
 SG_ StatusCPDData1FBD_HM_CIRData02 : 48|8@1+ (1.0,0) [0|255] "" IPB_App1
 SG_ StatusCPDData1FBD_HM_CIRData03 : 56|8@1+ (1.0,0) [0|255] "" IPB_App1
 SG_ StatusCPDData1FBD_HM_CIRData04 : 64|8@1+ (1.0,0) [0|255] "" IPB_App1
 SG_ StatusCPDData1FBD_HM_CIRData05 : 72|8@1+ (1.0,0) [0|255] "" IPB_App1
 SG_ StatusCPDData1FBD_HM_CIRData06 : 80|8@1+ (1.0,0) [0|255] "" IPB_App1
 SG_ StatusCPDData1FBD_HM_CIRData07 : 88|8@1+ (1.0,0) [0|255] "" IPB_App1
 SG_ StatusCPDData1FBD_HM_CIRData08 : 96|8@1+ (1.0,0) [0|255] "" IPB_App1
 SG_ StatusCPDData1FBD_HM_CIRData09 : 104|8@1+ (1.0,0) [0|255] "" IPB_App1
 SG_ StatusCPDData1FBD_HM_CIRData10 : 112|8@1+ (1.0,0) [0|255] "" IPB_App1
 SG_ StatusCPDData1FBD_HM_CIRData11 : 120|8@1+ (1.0,0) [0|255] "" IPB_App1
 SG_ StatusCPDData1FBD_HM_CIRData12 : 128|8@1+ (1.0,0) [0|255] "" IPB_App1
 SG_ StatusCPDData1FBD_HM_CIRData13 : 136|8@1+ (1.0,0) [0|255] "" IPB_App1
 SG_ StatusCPDData1FBD_HM_CIRData14 : 144|8@1+ (1.0,0) [0|255] "" IPB_App1
 SG_ StatusCPDData1FBD_HM_CIRData15 : 152|8@1+ (1.0,0) [0|255] "" IPB_App1
 SG_ StatusCPDData1FBD_HM_CIRData16 : 160|8@1+ (1.0,0) [0|255] "" IPB_App1
 SG_ StatusCPDData1FBD_HM_CIRData17 : 168|8@1+ (1.0,0) [0|255] "" IPB_App1
 SG_ StatusCPDData1FBD_HM_CIRData18 : 176|8@1+ (1.0,0) [0|255] "" IPB_App1
 SG_ StatusCPDData1FBD_HM_CIRData19 : 184|8@1+ (1.0,0) [0|255] "" IPB_App1
 SG_ StatusCPDData1FBD_HM_CIRData20 : 192|8@1+ (1.0,0) [0|255] "" IPB_App1
 SG_ StatusCPDData1FBD_HM_CIRData21 : 200|8@1+ (1.0,0) [0|255] "" IPB_App1
 SG_ StatusCPDData1FBD_HM_CIRData22 : 208|8@1+ (1.0,0) [0|255] "" IPB_App1
 SG_ StatusCPDData1FBD_HM_CIRData23 : 216|8@1+ (1.0,0) [0|255] "" IPB_App1
 SG_ StatusCPDData1FBD_HM_CIRData24 : 224|8@1+ (1.0,0) [0|255] "" IPB_App1
 SG_ StatusCPDData1FBD_HM_CIRData25 : 232|8@1+ (1.0,0) [0|255] "" IPB_App1
 SG_ StatusCPDData1FBD_HM_CIRData26 : 240|8@1+ (1.0,0) [0|255] "" IPB_App1
 SG_ StatusCPDData1FBD_HM_CIRData27 : 248|8@1+ (1.0,0) [0|255] "" IPB_App1
 SG_ StatusCPDData1FBD_HM_CIRData28 : 256|8@1+ (1.0,0) [0|255] "" IPB_App1
 SG_ StatusCPDData1FBD_HM_CIRData29 : 264|8@1+ (1.0,0) [0|255] "" IPB_App1
 SG_ StatusCPDData1FBD_HM_CIRData30 : 272|8@1+ (1.0,0) [0|255] "" IPB_App1
 SG_ StatusCPDData1FBD_HM_CIRData31 : 280|8@1+ (1.0,0) [0|255] "" IPB_App1
 SG_ StatusCPDData1FBD_HM_CIRData32 : 288|8@1+ (1.0,0) [0|255] "" IPB_App1
 SG_ StatusCPDData1FBD_HM_CIRData33 : 296|8@1+ (1.0,0) [0|255] "" IPB_App1
 SG_ StatusCPDData1FBD_HM_CIRData34 : 304|8@1+ (1.0,0) [0|255] "" IPB_App1
 SG_ StatusCPDData1FBD_HM_CIRData35 : 312|8@1+ (1.0,0) [0|255] "" IPB_App1
 SG_ StatusCPDData1FBD_HM_CIRData36 : 320|8@1+ (1.0,0) [0|255] "" IPB_App1
 SG_ StatusCPDData1FBD_HM_CIRData37 : 328|8@1+ (1.0,0) [0|255] "" IPB_App1
 SG_ StatusCPDData1FBD_HM_CIRData38 : 336|8@1+ (1.0,0) [0|255] "" IPB_App1
 SG_ StatusCPDData1FBD_HM_CIRData39 : 344|8@1+ (1.0,0) [0|255] "" IPB_App1
 SG_ StatusCPDData1FBD_HM_CIRData40 : 352|8@1+ (1.0,0) [0|255] "" IPB_App1
 SG_ StatusCPDData1FBD_HM_CIRData41 : 360|8@1+ (1.0,0) [0|255] "" IPB_App1
 SG_ StatusCPDData1FBD_HM_CIRData42 : 368|8@1+ (1.0,0) [0|255] "" IPB_App1
 SG_ StatusCPDData1FBD_HM_CIRData43 : 376|8@1+ (1.0,0) [0|255] "" IPB_App1
 SG_ StatusCPDData1FBD_HM_CIRData44 : 384|8@1+ (1.0,0) [0|255] "" IPB_App1
 SG_ StatusCPDData1FBD_HM_CIRData45 : 392|8@1+ (1.0,0) [0|255] "" IPB_App1
 SG_ StatusCPDData1FBD_HM_CIRData46 : 400|8@1+ (1.0,0) [0|255] "" IPB_App1
 SG_ StatusCPDData1FBD_HM_CIRData47 : 408|8@1+ (1.0,0) [0|255] "" IPB_App1
 SG_ StatusCPDData1FBD_HM_CIRData48 : 416|8@1+ (1.0,0) [0|255] "" IPB_App1
 SG_ StatusCPDData1FBD_HM_CIRData49 : 424|8@1+ (1.0,0) [0|255] "" IPB_App1
 SG_ StatusCPDData1FBD_HM_CIRData50 : 432|8@1+ (1.0,0) [0|255] "" IPB_App1
 SG_ StatusCPDData1FBD_HM_CIRData51 : 440|8@1+ (1.0,0) [0|255] "" IPB_App1
 SG_ StatusCPDData1FBD_HM_CIRData52 : 448|8@1+ (1.0,0) [0|255] "" IPB_App1
 SG_ StatusCPDData1FBD_HM_CIRData53 : 456|8@1+ (1.0,0) [0|255] "" IPB_App1
 SG_ StatusCPDData1FBD_HM_CIRData54 : 464|8@1+ (1.0,0) [0|255] "" IPB_App1
 SG_ StatusCPDData1FBD_HM_CIRData55 : 472|8@1+ (1.0,0) [0|255] "" IPB_App1
 SG_ StatusCPDData1FBD_HM_CIRData56 : 480|8@1+ (1.0,0) [0|255] "" IPB_App1
 SG_ StatusCPDData1FBD_HM_CIRData57 : 488|8@1+ (1.0,0) [0|255] "" IPB_App1
 SG_ StatusCPDData1FBD_HM_CIRData58 : 496|8@1+ (1.0,0) [0|255] "" IPB_App1
 SG_ StatusCPDData1FBD_HM_CIRData59 : 504|8@1+ (1.0,0) [0|255] "" IPB_App1

BO_ 337 StatusCPDData1FBD_HR: 64 FBD_HR
 SG_ StatusCPDData1FBD_HR_MsgCounter : 0|8@1+ (1.0,0) [0|252] "" IPB_App1
 SG_ StatusCPDData1FBD_HR_LinkID : 8|8@1+ (1.0,0) [0|252] "" IPB_App1
 SG_ StatusCPDData1FBD_HR_AGCValue : 16|8@1+ (1.0,0) [0|252] "" IPB_App1
 SG_ StatusCPDData1FBD_HR_Channel : 24|8@1+ (1.0,0) [0|252] "" IPB_App1
 SG_ StatusCPDData1FBD_HR_CIRData00 : 32|8@1+ (1.0,0) [0|255] "" IPB_App1
 SG_ StatusCPDData1FBD_HR_CIRData01 : 40|8@1+ (1.0,0) [0|255] "" IPB_App1
 SG_ StatusCPDData1FBD_HR_CIRData02 : 48|8@1+ (1.0,0) [0|255] "" IPB_App1
 SG_ StatusCPDData1FBD_HR_CIRData03 : 56|8@1+ (1.0,0) [0|255] "" IPB_App1
 SG_ StatusCPDData1FBD_HR_CIRData04 : 64|8@1+ (1.0,0) [0|255] "" IPB_App1
 SG_ StatusCPDData1FBD_HR_CIRData05 : 72|8@1+ (1.0,0) [0|255] "" IPB_App1
 SG_ StatusCPDData1FBD_HR_CIRData06 : 80|8@1+ (1.0,0) [0|255] "" IPB_App1
 SG_ StatusCPDData1FBD_HR_CIRData07 : 88|8@1+ (1.0,0) [0|255] "" IPB_App1
 SG_ StatusCPDData1FBD_HR_CIRData08 : 96|8@1+ (1.0,0) [0|255] "" IPB_App1
 SG_ StatusCPDData1FBD_HR_CIRData09 : 104|8@1+ (1.0,0) [0|255] "" IPB_App1
 SG_ StatusCPDData1FBD_HR_CIRData10 : 112|8@1+ (1.0,0) [0|255] "" IPB_App1
 SG_ StatusCPDData1FBD_HR_CIRData11 : 120|8@1+ (1.0,0) [0|255] "" IPB_App1
 SG_ StatusCPDData1FBD_HR_CIRData12 : 128|8@1+ (1.0,0) [0|255] "" IPB_App1
 SG_ StatusCPDData1FBD_HR_CIRData13 : 136|8@1+ (1.0,0) [0|255] "" IPB_App1
 SG_ StatusCPDData1FBD_HR_CIRData14 : 144|8@1+ (1.0,0) [0|255] "" IPB_App1
 SG_ StatusCPDData1FBD_HR_CIRData15 : 152|8@1+ (1.0,0) [0|255] "" IPB_App1
 SG_ StatusCPDData1FBD_HR_CIRData16 : 160|8@1+ (1.0,0) [0|255] "" IPB_App1
 SG_ StatusCPDData1FBD_HR_CIRData17 : 168|8@1+ (1.0,0) [0|255] "" IPB_App1
 SG_ StatusCPDData1FBD_HR_CIRData18 : 176|8@1+ (1.0,0) [0|255] "" IPB_App1
 SG_ StatusCPDData1FBD_HR_CIRData19 : 184|8@1+ (1.0,0) [0|255] "" IPB_App1
 SG_ StatusCPDData1FBD_HR_CIRData20 : 192|8@1+ (1.0,0) [0|255] "" IPB_App1
 SG_ StatusCPDData1FBD_HR_CIRData21 : 200|8@1+ (1.0,0) [0|255] "" IPB_App1
 SG_ StatusCPDData1FBD_HR_CIRData22 : 208|8@1+ (1.0,0) [0|255] "" IPB_App1
 SG_ StatusCPDData1FBD_HR_CIRData23 : 216|8@1+ (1.0,0) [0|255] "" IPB_App1
 SG_ StatusCPDData1FBD_HR_CIRData24 : 224|8@1+ (1.0,0) [0|255] "" IPB_App1
 SG_ StatusCPDData1FBD_HR_CIRData25 : 232|8@1+ (1.0,0) [0|255] "" IPB_App1
 SG_ StatusCPDData1FBD_HR_CIRData26 : 240|8@1+ (1.0,0) [0|255] "" IPB_App1
 SG_ StatusCPDData1FBD_HR_CIRData27 : 248|8@1+ (1.0,0) [0|255] "" IPB_App1
 SG_ StatusCPDData1FBD_HR_CIRData28 : 256|8@1+ (1.0,0) [0|255] "" IPB_App1
 SG_ StatusCPDData1FBD_HR_CIRData29 : 264|8@1+ (1.0,0) [0|255] "" IPB_App1
 SG_ StatusCPDData1FBD_HR_CIRData30 : 272|8@1+ (1.0,0) [0|255] "" IPB_App1
 SG_ StatusCPDData1FBD_HR_CIRData31 : 280|8@1+ (1.0,0) [0|255] "" IPB_App1
 SG_ StatusCPDData1FBD_HR_CIRData32 : 288|8@1+ (1.0,0) [0|255] "" IPB_App1
 SG_ StatusCPDData1FBD_HR_CIRData33 : 296|8@1+ (1.0,0) [0|255] "" IPB_App1
 SG_ StatusCPDData1FBD_HR_CIRData34 : 304|8@1+ (1.0,0) [0|255] "" IPB_App1
 SG_ StatusCPDData1FBD_HR_CIRData35 : 312|8@1+ (1.0,0) [0|255] "" IPB_App1
 SG_ StatusCPDData1FBD_HR_CIRData36 : 320|8@1+ (1.0,0) [0|255] "" IPB_App1
 SG_ StatusCPDData1FBD_HR_CIRData37 : 328|8@1+ (1.0,0) [0|255] "" IPB_App1
 SG_ StatusCPDData1FBD_HR_CIRData38 : 336|8@1+ (1.0,0) [0|255] "" IPB_App1
 SG_ StatusCPDData1FBD_HR_CIRData39 : 344|8@1+ (1.0,0) [0|255] "" IPB_App1
 SG_ StatusCPDData1FBD_HR_CIRData40 : 352|8@1+ (1.0,0) [0|255] "" IPB_App1
 SG_ StatusCPDData1FBD_HR_CIRData41 : 360|8@1+ (1.0,0) [0|255] "" IPB_App1
 SG_ StatusCPDData1FBD_HR_CIRData42 : 368|8@1+ (1.0,0) [0|255] "" IPB_App1
 SG_ StatusCPDData1FBD_HR_CIRData43 : 376|8@1+ (1.0,0) [0|255] "" IPB_App1
 SG_ StatusCPDData1FBD_HR_CIRData44 : 384|8@1+ (1.0,0) [0|255] "" IPB_App1
 SG_ StatusCPDData1FBD_HR_CIRData45 : 392|8@1+ (1.0,0) [0|255] "" IPB_App1
 SG_ StatusCPDData1FBD_HR_CIRData46 : 400|8@1+ (1.0,0) [0|255] "" IPB_App1
 SG_ StatusCPDData1FBD_HR_CIRData47 : 408|8@1+ (1.0,0) [0|255] "" IPB_App1
 SG_ StatusCPDData1FBD_HR_CIRData48 : 416|8@1+ (1.0,0) [0|255] "" IPB_App1
 SG_ StatusCPDData1FBD_HR_CIRData49 : 424|8@1+ (1.0,0) [0|255] "" IPB_App1
 SG_ StatusCPDData1FBD_HR_CIRData50 : 432|8@1+ (1.0,0) [0|255] "" IPB_App1
 SG_ StatusCPDData1FBD_HR_CIRData51 : 440|8@1+ (1.0,0) [0|255] "" IPB_App1
 SG_ StatusCPDData1FBD_HR_CIRData52 : 448|8@1+ (1.0,0) [0|255] "" IPB_App1
 SG_ StatusCPDData1FBD_HR_CIRData53 : 456|8@1+ (1.0,0) [0|255] "" IPB_App1
 SG_ StatusCPDData1FBD_HR_CIRData54 : 464|8@1+ (1.0,0) [0|255] "" IPB_App1
 SG_ StatusCPDData1FBD_HR_CIRData55 : 472|8@1+ (1.0,0) [0|255] "" IPB_App1
 SG_ StatusCPDData1FBD_HR_CIRData56 : 480|8@1+ (1.0,0) [0|255] "" IPB_App1
 SG_ StatusCPDData1FBD_HR_CIRData57 : 488|8@1+ (1.0,0) [0|255] "" IPB_App1
 SG_ StatusCPDData1FBD_HR_CIRData58 : 496|8@1+ (1.0,0) [0|255] "" IPB_App1
 SG_ StatusCPDData1FBD_HR_CIRData59 : 504|8@1+ (1.0,0) [0|255] "" IPB_App1

CM_ SG_ 651 StatusBLEDeviceNameFBD_HM_Charac "contains 1st character of BLE device name";
CM_ SG_ 651 StatusBLEDeviceNameFBD_HM_Char_2 "contains 2nd character of BLE device name";
CM_ SG_ 651 StatusBLEDeviceNameFBD_HM_Char_3 "contains 3rd character of BLE device name";
CM_ SG_ 651 StatusBLEDeviceNameFBD_HM_Char_4 "contains 4th character of BLE device name";
CM_ SG_ 651 StatusBLEDeviceNameFBD_HM_Char_5 "contains 5th character of BLE device name";
CM_ SG_ 651 StatusBLEDeviceNameFBD_HM_Char_6 "contains 6th character of BLE device name";
CM_ SG_ 651 StatusBLEDeviceNameFBD_HM_Char_7 "contains 7th character of BLE device name";
CM_ SG_ 651 StatusBLEDeviceNameFBD_HM_Char_8 "contains 8th character of BLE device name";
CM_ SG_ 651 StatusBLEDeviceNameFBD_HM_Char_9 "contains 9th character of BLE device name";
CM_ SG_ 651 StatusBLEDeviceNameFBD_HM_Cha_10 "contains 10th character of BLE device name";
CM_ SG_ 651 StatusBLEDeviceNameFBD_HM_Cha_11 "contains 11th character of BLE device name";
CM_ SG_ 651 StatusBLEDeviceNameFBD_HM_Cha_12 "contains 12th character of BLE device name";
CM_ SG_ 651 StatusBLEDeviceNameFBD_HM_Cha_13 "contains 13th character of BLE device name";
CM_ SG_ 651 StatusBLEDeviceNameFBD_HM_Cha_14 "contains 14th character of BLE device name";
CM_ SG_ 651 StatusBLEDeviceNameFBD_HM_Cha_15 "contains 15th character of BLE device name";
CM_ SG_ 651 StatusBLEDeviceNameFBD_HM_Cha_16 "contains 16th character of BLE device name";
CM_ SG_ 651 StatusBLEDeviceNameFBD_HM_Cha_17 "contains 17th character of BLE device name";
CM_ SG_ 651 StatusBLEDeviceNameFBD_HM_Cha_18 "contains 18th character of BLE device name";
CM_ SG_ 651 StatusBLEDeviceNameFBD_HM_Cha_19 "contains 19th character of BLE device name";
CM_ SG_ 651 StatusBLEDeviceNameFBD_HM_Cha_20 "contains 20th character of BLE device name";
CM_ SG_ 651 StatusBLEDeviceNameFBD_HM_Cha_21 "contains 21st character of BLE device name";
CM_ SG_ 651 StatusBLEDeviceNameFBD_HM_Cha_22 "contains 22nd character of BLE device name";
CM_ SG_ 651 StatusBLEDeviceNameFBD_HM_Cha_23 "contains 23rd character of BLE device name";
CM_ SG_ 651 StatusBLEDeviceNameFBD_HM_Cha_24 "contains 24th character of BLE device name";
CM_ SG_ 651 StatusBLEDeviceNameFBD_HM_Cha_25 "contains 25th character of BLE device name";
CM_ SG_ 651 StatusBLEDeviceNameFBD_HM_Cha_26 "contains 26th character of BLE device name";
CM_ SG_ 651 StatusBLEDeviceNameFBD_HM_Cha_27 "contains 27th character of BLE device name";
CM_ SG_ 651 StatusBLEDeviceNameFBD_HM_Cha_28 "contains 28th character of BLE device name";
CM_ SG_ 651 StatusBLEDeviceNameFBD_HM_Cha_29 "contains 29th character of BLE device name";
CM_ SG_ 651 StatusBLEDeviceNameFBD_HM_Cha_30 "contains 30th character of BLE device name";
CM_ SG_ 657 StatusBLEDeviceNameFBD_HR_Charac "contains 1st character of BLE device name";
CM_ SG_ 657 StatusBLEDeviceNameFBD_HR_Char_2 "contains 2nd character of BLE device name";
CM_ SG_ 657 StatusBLEDeviceNameFBD_HR_Char_3 "contains 3rd character of BLE device name";
CM_ SG_ 657 StatusBLEDeviceNameFBD_HR_Char_4 "contains 4th character of BLE device name";
CM_ SG_ 657 StatusBLEDeviceNameFBD_HR_Char_5 "contains 5th character of BLE device name";
CM_ SG_ 657 StatusBLEDeviceNameFBD_HR_Char_6 "contains 6th character of BLE device name";
CM_ SG_ 657 StatusBLEDeviceNameFBD_HR_Char_7 "contains 7th character of BLE device name";
CM_ SG_ 657 StatusBLEDeviceNameFBD_HR_Char_8 "contains 8th character of BLE device name";
CM_ SG_ 657 StatusBLEDeviceNameFBD_HR_Char_9 "contains 9th character of BLE device name";
CM_ SG_ 657 StatusBLEDeviceNameFBD_HR_Cha_10 "contains 10th character of BLE device name";
CM_ SG_ 657 StatusBLEDeviceNameFBD_HR_Cha_11 "contains 11th character of BLE device name";
CM_ SG_ 657 StatusBLEDeviceNameFBD_HR_Cha_12 "contains 12th character of BLE device name";
CM_ SG_ 657 StatusBLEDeviceNameFBD_HR_Cha_13 "contains 13th character of BLE device name";
CM_ SG_ 657 StatusBLEDeviceNameFBD_HR_Cha_14 "contains 14th character of BLE device name";
CM_ SG_ 657 StatusBLEDeviceNameFBD_HR_Cha_15 "contains 15th character of BLE device name";
CM_ SG_ 657 StatusBLEDeviceNameFBD_HR_Cha_16 "contains 16th character of BLE device name";
CM_ SG_ 657 StatusBLEDeviceNameFBD_HR_Cha_17 "contains 17th character of BLE device name";
CM_ SG_ 657 StatusBLEDeviceNameFBD_HR_Cha_18 "contains 18th character of BLE device name";
CM_ SG_ 657 StatusBLEDeviceNameFBD_HR_Cha_19 "contains 19th character of BLE device name";
CM_ SG_ 657 StatusBLEDeviceNameFBD_HR_Cha_20 "contains 20th character of BLE device name";
CM_ SG_ 657 StatusBLEDeviceNameFBD_HR_Cha_21 "contains 21st character of BLE device name";
CM_ SG_ 657 StatusBLEDeviceNameFBD_HR_Cha_22 "contains 22nd character of BLE device name";
CM_ SG_ 657 StatusBLEDeviceNameFBD_HR_Cha_23 "contains 23rd character of BLE device name";
CM_ SG_ 657 StatusBLEDeviceNameFBD_HR_Cha_24 "contains 24th character of BLE device name";
CM_ SG_ 657 StatusBLEDeviceNameFBD_HR_Cha_25 "contains 25th character of BLE device name";
CM_ SG_ 657 StatusBLEDeviceNameFBD_HR_Cha_26 "contains 26th character of BLE device name";
CM_ SG_ 657 StatusBLEDeviceNameFBD_HR_Cha_27 "contains 27th character of BLE device name";
CM_ SG_ 657 StatusBLEDeviceNameFBD_HR_Cha_28 "contains 28th character of BLE device name";
CM_ SG_ 657 StatusBLEDeviceNameFBD_HR_Cha_29 "contains 29th character of BLE device name";
CM_ SG_ 657 StatusBLEDeviceNameFBD_HR_Cha_30 "contains 30th character of BLE device name";
CM_ SG_ 652 StatusBLEDeviceNameFBD_Miko_Char "contains 1st character of BLE device name";
CM_ SG_ 652 StatusBLEDeviceNameFBD_Miko_Ch_2 "contains 2nd character of BLE device name";
CM_ SG_ 652 StatusBLEDeviceNameFBD_Miko_Ch_3 "contains 3rd character of BLE device name";
CM_ SG_ 652 StatusBLEDeviceNameFBD_Miko_Ch_4 "contains 4th character of BLE device name";
CM_ SG_ 652 StatusBLEDeviceNameFBD_Miko_Ch_5 "contains 5th character of BLE device name";
CM_ SG_ 652 StatusBLEDeviceNameFBD_Miko_Ch_6 "contains 6th character of BLE device name";
CM_ SG_ 652 StatusBLEDeviceNameFBD_Miko_Ch_7 "contains 7th character of BLE device name";
CM_ SG_ 652 StatusBLEDeviceNameFBD_Miko_Ch_8 "contains 8th character of BLE device name";
CM_ SG_ 652 StatusBLEDeviceNameFBD_Miko_Ch_9 "contains 9th character of BLE device name";
CM_ SG_ 652 StatusBLEDeviceNameFBD_Miko_C_10 "contains 10th character of BLE device name";
CM_ SG_ 652 StatusBLEDeviceNameFBD_Miko_C_11 "contains 11th character of BLE device name";
CM_ SG_ 652 StatusBLEDeviceNameFBD_Miko_C_12 "contains 12th character of BLE device name";
CM_ SG_ 652 StatusBLEDeviceNameFBD_Miko_C_13 "contains 13th character of BLE device name";
CM_ SG_ 652 StatusBLEDeviceNameFBD_Miko_C_14 "contains 14th character of BLE device name";
CM_ SG_ 652 StatusBLEDeviceNameFBD_Miko_C_15 "contains 15th character of BLE device name";
CM_ SG_ 652 StatusBLEDeviceNameFBD_Miko_C_16 "contains 16th character of BLE device name";
CM_ SG_ 652 StatusBLEDeviceNameFBD_Miko_C_17 "contains 17th character of BLE device name";
CM_ SG_ 652 StatusBLEDeviceNameFBD_Miko_C_18 "contains 18th character of BLE device name";
CM_ SG_ 652 StatusBLEDeviceNameFBD_Miko_C_19 "contains 19th character of BLE device name";
CM_ SG_ 652 StatusBLEDeviceNameFBD_Miko_C_20 "contains 20th character of BLE device name";
CM_ SG_ 652 StatusBLEDeviceNameFBD_Miko_C_21 "contains 21st character of BLE device name";
CM_ SG_ 652 StatusBLEDeviceNameFBD_Miko_C_22 "contains 22nd character of BLE device name";
CM_ SG_ 652 StatusBLEDeviceNameFBD_Miko_C_23 "contains 23rd character of BLE device name";
CM_ SG_ 652 StatusBLEDeviceNameFBD_Miko_C_24 "contains 24th character of BLE device name";
CM_ SG_ 652 StatusBLEDeviceNameFBD_Miko_C_25 "contains 25th character of BLE device name";
CM_ SG_ 652 StatusBLEDeviceNameFBD_Miko_C_26 "contains 26th character of BLE device name";
CM_ SG_ 652 StatusBLEDeviceNameFBD_Miko_C_27 "contains 27th character of BLE device name";
CM_ SG_ 652 StatusBLEDeviceNameFBD_Miko_C_28 "contains 28th character of BLE device name";
CM_ SG_ 652 StatusBLEDeviceNameFBD_Miko_C_29 "contains 29th character of BLE device name";
CM_ SG_ 652 StatusBLEDeviceNameFBD_Miko_C_30 "contains 30th character of BLE device name";
CM_ SG_ 660 StatusBLEDeviceNameFBD_MM_Addres "addressing of the UWB anchors";
CM_ SG_ 660 StatusBLEDeviceNameFBD_MM_Charac "contains 1st character of BLE device name";
CM_ SG_ 660 StatusBLEDeviceNameFBD_MM_Char_2 "contains 2nd character of BLE device name";
CM_ SG_ 660 StatusBLEDeviceNameFBD_MM_Char_3 "contains 3rd character of BLE device name";
CM_ SG_ 660 StatusBLEDeviceNameFBD_MM_Char_4 "contains 4th character of BLE device name";
CM_ SG_ 660 StatusBLEDeviceNameFBD_MM_Char_5 "contains 5th character of BLE device name";
CM_ SG_ 660 StatusBLEDeviceNameFBD_MM_Char_6 "contains 6th character of BLE device name";
CM_ SG_ 660 StatusBLEDeviceNameFBD_MM_Char_7 "contains 7th character of BLE device name";
CM_ SG_ 660 StatusBLEDeviceNameFBD_MM_Char_8 "contains 8th character of BLE device name";
CM_ SG_ 660 StatusBLEDeviceNameFBD_MM_Char_9 "contains 9th character of BLE device name";
CM_ SG_ 660 StatusBLEDeviceNameFBD_MM_Cha_10 "contains 10th character of BLE device name";
CM_ SG_ 660 StatusBLEDeviceNameFBD_MM_Cha_11 "contains 11th character of BLE device name";
CM_ SG_ 660 StatusBLEDeviceNameFBD_MM_Cha_12 "contains 12th character of BLE device name";
CM_ SG_ 660 StatusBLEDeviceNameFBD_MM_Cha_13 "contains 13th character of BLE device name";
CM_ SG_ 660 StatusBLEDeviceNameFBD_MM_Cha_14 "contains 14th character of BLE device name";
CM_ SG_ 660 StatusBLEDeviceNameFBD_MM_Cha_15 "contains 15th character of BLE device name";
CM_ SG_ 660 StatusBLEDeviceNameFBD_MM_Cha_16 "contains 16th character of BLE device name";
CM_ SG_ 660 StatusBLEDeviceNameFBD_MM_Cha_17 "contains 17th character of BLE device name";
CM_ SG_ 660 StatusBLEDeviceNameFBD_MM_Cha_18 "contains 18th character of BLE device name";
CM_ SG_ 660 StatusBLEDeviceNameFBD_MM_Cha_19 "contains 19th character of BLE device name";
CM_ SG_ 660 StatusBLEDeviceNameFBD_MM_Cha_20 "contains 20th character of BLE device name";
CM_ SG_ 660 StatusBLEDeviceNameFBD_MM_Cha_21 "contains 21st character of BLE device name";
CM_ SG_ 660 StatusBLEDeviceNameFBD_MM_Cha_22 "contains 22nd character of BLE device name";
CM_ SG_ 660 StatusBLEDeviceNameFBD_MM_Cha_23 "contains 23rd character of BLE device name";
CM_ SG_ 660 StatusBLEDeviceNameFBD_MM_Cha_24 "contains 24th character of BLE device name";
CM_ SG_ 660 StatusBLEDeviceNameFBD_MM_Cha_25 "contains 25th character of BLE device name";
CM_ SG_ 660 StatusBLEDeviceNameFBD_MM_Cha_26 "contains 26th character of BLE device name";
CM_ SG_ 660 StatusBLEDeviceNameFBD_MM_Cha_27 "contains 27th character of BLE device name";
CM_ SG_ 660 StatusBLEDeviceNameFBD_MM_Cha_28 "contains 28th character of BLE device name";
CM_ SG_ 660 StatusBLEDeviceNameFBD_MM_Cha_29 "contains 29th character of BLE device name";
CM_ SG_ 660 StatusBLEDeviceNameFBD_MM_Cha_30 "contains 30th character of BLE device name";
CM_ SG_ 653 StatusBLEDeviceNameFBD_Trunk_Cha "contains 1st character of BLE device name";
CM_ SG_ 653 StatusBLEDeviceNameFBD_Trunk_C_2 "contains 2nd character of BLE device name";
CM_ SG_ 653 StatusBLEDeviceNameFBD_Trunk_C_3 "contains 3rd character of BLE device name";
CM_ SG_ 653 StatusBLEDeviceNameFBD_Trunk_C_4 "contains 4th character of BLE device name";
CM_ SG_ 653 StatusBLEDeviceNameFBD_Trunk_C_5 "contains 5th character of BLE device name";
CM_ SG_ 653 StatusBLEDeviceNameFBD_Trunk_C_6 "contains 6th character of BLE device name";
CM_ SG_ 653 StatusBLEDeviceNameFBD_Trunk_C_7 "contains 7th character of BLE device name";
CM_ SG_ 653 StatusBLEDeviceNameFBD_Trunk_C_8 "contains 8th character of BLE device name";
CM_ SG_ 653 StatusBLEDeviceNameFBD_Trunk_C_9 "contains 9th character of BLE device name";
CM_ SG_ 653 StatusBLEDeviceNameFBD_Trunk__10 "contains 10th character of BLE device name";
CM_ SG_ 653 StatusBLEDeviceNameFBD_Trunk__11 "contains 11th character of BLE device name";
CM_ SG_ 653 StatusBLEDeviceNameFBD_Trunk__12 "contains 12th character of BLE device name";
CM_ SG_ 653 StatusBLEDeviceNameFBD_Trunk__13 "contains 13th character of BLE device name";
CM_ SG_ 653 StatusBLEDeviceNameFBD_Trunk__14 "contains 14th character of BLE device name";
CM_ SG_ 653 StatusBLEDeviceNameFBD_Trunk__15 "contains 15th character of BLE device name";
CM_ SG_ 653 StatusBLEDeviceNameFBD_Trunk__16 "contains 16th character of BLE device name";
CM_ SG_ 653 StatusBLEDeviceNameFBD_Trunk__17 "contains 17th character of BLE device name";
CM_ SG_ 653 StatusBLEDeviceNameFBD_Trunk__18 "contains 18th character of BLE device name";
CM_ SG_ 653 StatusBLEDeviceNameFBD_Trunk__19 "contains 19th character of BLE device name";
CM_ SG_ 653 StatusBLEDeviceNameFBD_Trunk__20 "contains 20th character of BLE device name";
CM_ SG_ 653 StatusBLEDeviceNameFBD_Trunk__21 "contains 21st character of BLE device name";
CM_ SG_ 653 StatusBLEDeviceNameFBD_Trunk__22 "contains 22nd character of BLE device name";
CM_ SG_ 653 StatusBLEDeviceNameFBD_Trunk__23 "contains 23rd character of BLE device name";
CM_ SG_ 653 StatusBLEDeviceNameFBD_Trunk__24 "contains 24th character of BLE device name";
CM_ SG_ 653 StatusBLEDeviceNameFBD_Trunk__25 "contains 25th character of BLE device name";
CM_ SG_ 653 StatusBLEDeviceNameFBD_Trunk__26 "contains 26th character of BLE device name";
CM_ SG_ 653 StatusBLEDeviceNameFBD_Trunk__27 "contains 27th character of BLE device name";
CM_ SG_ 653 StatusBLEDeviceNameFBD_Trunk__28 "contains 28th character of BLE device name";
CM_ SG_ 653 StatusBLEDeviceNameFBD_Trunk__29 "contains 29th character of BLE device name";
CM_ SG_ 653 StatusBLEDeviceNameFBD_Trunk__30 "contains 30th character of BLE device name";
CM_ SG_ 654 StatusBLEDeviceNameFBD_VL_Charac "contains 1st character of BLE device name";
CM_ SG_ 654 StatusBLEDeviceNameFBD_VL_Char_2 "contains 2nd character of BLE device name";
CM_ SG_ 654 StatusBLEDeviceNameFBD_VL_Char_3 "contains 3rd character of BLE device name";
CM_ SG_ 654 StatusBLEDeviceNameFBD_VL_Char_4 "contains 4th character of BLE device name";
CM_ SG_ 654 StatusBLEDeviceNameFBD_VL_Char_5 "contains 5th character of BLE device name";
CM_ SG_ 654 StatusBLEDeviceNameFBD_VL_Char_6 "contains 6th character of BLE device name";
CM_ SG_ 654 StatusBLEDeviceNameFBD_VL_Char_7 "contains 7th character of BLE device name";
CM_ SG_ 654 StatusBLEDeviceNameFBD_VL_Char_8 "contains 8th character of BLE device name";
CM_ SG_ 654 StatusBLEDeviceNameFBD_VL_Char_9 "contains 9th character of BLE device name";
CM_ SG_ 654 StatusBLEDeviceNameFBD_VL_Cha_10 "contains 10th character of BLE device name";
CM_ SG_ 654 StatusBLEDeviceNameFBD_VL_Cha_11 "contains 11th character of BLE device name";
CM_ SG_ 654 StatusBLEDeviceNameFBD_VL_Cha_12 "contains 12th character of BLE device name";
CM_ SG_ 654 StatusBLEDeviceNameFBD_VL_Cha_13 "contains 13th character of BLE device name";
CM_ SG_ 654 StatusBLEDeviceNameFBD_VL_Cha_14 "contains 14th character of BLE device name";
CM_ SG_ 654 StatusBLEDeviceNameFBD_VL_Cha_15 "contains 15th character of BLE device name";
CM_ SG_ 654 StatusBLEDeviceNameFBD_VL_Cha_16 "contains 16th character of BLE device name";
CM_ SG_ 654 StatusBLEDeviceNameFBD_VL_Cha_17 "contains 17th character of BLE device name";
CM_ SG_ 654 StatusBLEDeviceNameFBD_VL_Cha_18 "contains 18th character of BLE device name";
CM_ SG_ 654 StatusBLEDeviceNameFBD_VL_Cha_19 "contains 19th character of BLE device name";
CM_ SG_ 654 StatusBLEDeviceNameFBD_VL_Cha_20 "contains 20th character of BLE device name";
CM_ SG_ 654 StatusBLEDeviceNameFBD_VL_Cha_21 "contains 21st character of BLE device name";
CM_ SG_ 654 StatusBLEDeviceNameFBD_VL_Cha_22 "contains 22nd character of BLE device name";
CM_ SG_ 654 StatusBLEDeviceNameFBD_VL_Cha_23 "contains 23rd character of BLE device name";
CM_ SG_ 654 StatusBLEDeviceNameFBD_VL_Cha_24 "contains 24th character of BLE device name";
CM_ SG_ 654 StatusBLEDeviceNameFBD_VL_Cha_25 "contains 25th character of BLE device name";
CM_ SG_ 654 StatusBLEDeviceNameFBD_VL_Cha_26 "contains 26th character of BLE device name";
CM_ SG_ 654 StatusBLEDeviceNameFBD_VL_Cha_27 "contains 27th character of BLE device name";
CM_ SG_ 654 StatusBLEDeviceNameFBD_VL_Cha_28 "contains 28th character of BLE device name";
CM_ SG_ 654 StatusBLEDeviceNameFBD_VL_Cha_29 "contains 29th character of BLE device name";
CM_ SG_ 654 StatusBLEDeviceNameFBD_VL_Cha_30 "contains 30th character of BLE device name";
CM_ SG_ 650 StatusBLEDeviceNameFBD_VM_Charac "contains 1st character of BLE device name";
CM_ SG_ 650 StatusBLEDeviceNameFBD_VM_Char_2 "contains 2nd character of BLE device name";
CM_ SG_ 650 StatusBLEDeviceNameFBD_VM_Char_3 "contains 3rd character of BLE device name";
CM_ SG_ 650 StatusBLEDeviceNameFBD_VM_Char_4 "contains 4th character of BLE device name";
CM_ SG_ 650 StatusBLEDeviceNameFBD_VM_Char_5 "contains 5th character of BLE device name";
CM_ SG_ 650 StatusBLEDeviceNameFBD_VM_Char_6 "contains 6th character of BLE device name";
CM_ SG_ 650 StatusBLEDeviceNameFBD_VM_Char_7 "contains 7th character of BLE device name";
CM_ SG_ 650 StatusBLEDeviceNameFBD_VM_Char_8 "contains 8th character of BLE device name";
CM_ SG_ 650 StatusBLEDeviceNameFBD_VM_Char_9 "contains 9th character of BLE device name";
CM_ SG_ 650 StatusBLEDeviceNameFBD_VM_Cha_10 "contains 10th character of BLE device name";
CM_ SG_ 650 StatusBLEDeviceNameFBD_VM_Cha_11 "contains 11th character of BLE device name";
CM_ SG_ 650 StatusBLEDeviceNameFBD_VM_Cha_12 "contains 12th character of BLE device name";
CM_ SG_ 650 StatusBLEDeviceNameFBD_VM_Cha_13 "contains 13th character of BLE device name";
CM_ SG_ 650 StatusBLEDeviceNameFBD_VM_Cha_14 "contains 14th character of BLE device name";
CM_ SG_ 650 StatusBLEDeviceNameFBD_VM_Cha_15 "contains 15th character of BLE device name";
CM_ SG_ 650 StatusBLEDeviceNameFBD_VM_Cha_16 "contains 16th character of BLE device name";
CM_ SG_ 650 StatusBLEDeviceNameFBD_VM_Cha_17 "contains 17th character of BLE device name";
CM_ SG_ 650 StatusBLEDeviceNameFBD_VM_Cha_18 "contains 18th character of BLE device name";
CM_ SG_ 650 StatusBLEDeviceNameFBD_VM_Cha_19 "contains 19th character of BLE device name";
CM_ SG_ 650 StatusBLEDeviceNameFBD_VM_Cha_20 "contains 20th character of BLE device name";
CM_ SG_ 650 StatusBLEDeviceNameFBD_VM_Cha_21 "contains 21st character of BLE device name";
CM_ SG_ 650 StatusBLEDeviceNameFBD_VM_Cha_22 "contains 22nd character of BLE device name";
CM_ SG_ 650 StatusBLEDeviceNameFBD_VM_Cha_23 "contains 23rd character of BLE device name";
CM_ SG_ 650 StatusBLEDeviceNameFBD_VM_Cha_24 "contains 24th character of BLE device name";
CM_ SG_ 650 StatusBLEDeviceNameFBD_VM_Cha_25 "contains 25th character of BLE device name";
CM_ SG_ 650 StatusBLEDeviceNameFBD_VM_Cha_26 "contains 26th character of BLE device name";
CM_ SG_ 650 StatusBLEDeviceNameFBD_VM_Cha_27 "contains 27th character of BLE device name";
CM_ SG_ 650 StatusBLEDeviceNameFBD_VM_Cha_28 "contains 28th character of BLE device name";
CM_ SG_ 650 StatusBLEDeviceNameFBD_VM_Cha_29 "contains 29th character of BLE device name";
CM_ SG_ 650 StatusBLEDeviceNameFBD_VM_Cha_30 "contains 30th character of BLE device name";
CM_ SG_ 655 StatusBLEDeviceNameFBD_VR_Charac "contains 1st character of BLE device name";
CM_ SG_ 655 StatusBLEDeviceNameFBD_VR_Char_2 "contains 2nd character of BLE device name";
CM_ SG_ 655 StatusBLEDeviceNameFBD_VR_Char_3 "contains 3rd character of BLE device name";
CM_ SG_ 655 StatusBLEDeviceNameFBD_VR_Char_4 "contains 4th character of BLE device name";
CM_ SG_ 655 StatusBLEDeviceNameFBD_VR_Char_5 "contains 5th character of BLE device name";
CM_ SG_ 655 StatusBLEDeviceNameFBD_VR_Char_6 "contains 6th character of BLE device name";
CM_ SG_ 655 StatusBLEDeviceNameFBD_VR_Char_7 "contains 7th character of BLE device name";
CM_ SG_ 655 StatusBLEDeviceNameFBD_VR_Char_8 "contains 8th character of BLE device name";
CM_ SG_ 655 StatusBLEDeviceNameFBD_VR_Char_9 "contains 9th character of BLE device name";
CM_ SG_ 655 StatusBLEDeviceNameFBD_VR_Cha_10 "contains 10th character of BLE device name";
CM_ SG_ 655 StatusBLEDeviceNameFBD_VR_Cha_11 "contains 11th character of BLE device name";
CM_ SG_ 655 StatusBLEDeviceNameFBD_VR_Cha_12 "contains 12th character of BLE device name";
CM_ SG_ 655 StatusBLEDeviceNameFBD_VR_Cha_13 "contains 13th character of BLE device name";
CM_ SG_ 655 StatusBLEDeviceNameFBD_VR_Cha_14 "contains 14th character of BLE device name";
CM_ SG_ 655 StatusBLEDeviceNameFBD_VR_Cha_15 "contains 15th character of BLE device name";
CM_ SG_ 655 StatusBLEDeviceNameFBD_VR_Cha_16 "contains 16th character of BLE device name";
CM_ SG_ 655 StatusBLEDeviceNameFBD_VR_Cha_17 "contains 17th character of BLE device name";
CM_ SG_ 655 StatusBLEDeviceNameFBD_VR_Cha_18 "contains 18th character of BLE device name";
CM_ SG_ 655 StatusBLEDeviceNameFBD_VR_Cha_19 "contains 19th character of BLE device name";
CM_ SG_ 655 StatusBLEDeviceNameFBD_VR_Cha_20 "contains 20th character of BLE device name";
CM_ SG_ 655 StatusBLEDeviceNameFBD_VR_Cha_21 "contains 21st character of BLE device name";
CM_ SG_ 655 StatusBLEDeviceNameFBD_VR_Cha_22 "contains 22nd character of BLE device name";
CM_ SG_ 655 StatusBLEDeviceNameFBD_VR_Cha_23 "contains 23rd character of BLE device name";
CM_ SG_ 655 StatusBLEDeviceNameFBD_VR_Cha_24 "contains 24th character of BLE device name";
CM_ SG_ 655 StatusBLEDeviceNameFBD_VR_Cha_25 "contains 25th character of BLE device name";
CM_ SG_ 655 StatusBLEDeviceNameFBD_VR_Cha_26 "contains 26th character of BLE device name";
CM_ SG_ 655 StatusBLEDeviceNameFBD_VR_Cha_27 "contains 27th character of BLE device name";
CM_ SG_ 655 StatusBLEDeviceNameFBD_VR_Cha_28 "contains 28th character of BLE device name";
CM_ SG_ 655 StatusBLEDeviceNameFBD_VR_Cha_29 "contains 29th character of BLE device name";
CM_ SG_ 655 StatusBLEDeviceNameFBD_VR_Cha_30 "contains 30th character of BLE device name";
CM_ SG_ 256 StatusBLEHandoverFBD_HL_Connecti "contains ConnectionID";
CM_ SG_ 256 StatusBLEHandoverFBD_HL_Handover "contains handover status";
CM_ SG_ 256 StatusBLEHandoverFBD_HL_NumberAc "contians amount of active connections";
CM_ SG_ 251 StatusBLEHandoverFBD_HM_Connecti "contains ConnectionID";
CM_ SG_ 251 StatusBLEHandoverFBD_HM_Handover "contains handover status";
CM_ SG_ 251 StatusBLEHandoverFBD_HM_NumberAc "contians amount of active connections";
CM_ SG_ 257 StatusBLEHandoverFBD_HR_Connecti "contains ConnectionID";
CM_ SG_ 257 StatusBLEHandoverFBD_HR_Handover "contains handover status";
CM_ SG_ 257 StatusBLEHandoverFBD_HR_NumberAc "contians amount of active connections";
CM_ SG_ 252 StatusBLEHandoverFBD_Miko_Connec "contains ConnectionID";
CM_ SG_ 252 StatusBLEHandoverFBD_Miko_Handov "contains handover status";
CM_ SG_ 252 StatusBLEHandoverFBD_Miko_Number "contians amount of active connections";
CM_ SG_ 820 StatusBLEHandoverFBD_MM_Connecti "contains ConnectionID";
CM_ SG_ 820 StatusBLEHandoverFBD_MM_Handover "contains handover status";
CM_ SG_ 820 StatusBLEHandoverFBD_MM_NumberAc "contians amount of active connections";
CM_ SG_ 253 StatusBLEHandoverFBD_Trunk_Conne "contains ConnectionID";
CM_ SG_ 253 StatusBLEHandoverFBD_Trunk_Hando "contains handover status";
CM_ SG_ 253 StatusBLEHandoverFBD_Trunk_Numbe "contians amount of active connections";
CM_ SG_ 254 StatusBLEHandoverFBD_VL_Connecti "contains ConnectionID";
CM_ SG_ 254 StatusBLEHandoverFBD_VL_Handover "contains handover status";
CM_ SG_ 254 StatusBLEHandoverFBD_VL_NumberAc "contians amount of active connections";
CM_ SG_ 250 StatusBLEHandoverFBD_VM_Connecti "contains ConnectionID";
CM_ SG_ 250 StatusBLEHandoverFBD_VM_Handover "contains handover status";
CM_ SG_ 250 StatusBLEHandoverFBD_VM_NumberAc "contians amount of active connections";
CM_ SG_ 255 StatusBLEHandoverFBD_VR_Connecti "contains ConnectionID";
CM_ SG_ 255 StatusBLEHandoverFBD_VR_Handover "contains handover status";
CM_ SG_ 255 StatusBLEHandoverFBD_VR_NumberAc "contians amount of active connections";
CM_ SG_ 926 StatusBLEParameter_FBD_HL_Addres "addressing of the BLE nodes";
CM_ SG_ 926 StatusBLEParameter_FBD_HL_IRKLis "contains ConnectionID";
CM_ SG_ 926 StatusBLEParameter_FBD_HL_Status "contains acknowledge to connection parameter";
CM_ SG_ 921 StatusBLEParameter_FBD_HM_Addres "addressing of the BLE nodes";
CM_ SG_ 921 StatusBLEParameter_FBD_HM_IRKLis "contains ConnectionID";
CM_ SG_ 921 StatusBLEParameter_FBD_HM_Status "contains acknowledge to connection parameter";
CM_ SG_ 927 StatusBLEParameter_FBD_HR_Addres "addressing of the BLE nodes";
CM_ SG_ 927 StatusBLEParameter_FBD_HR_IRKLis "contains ConnectionID";
CM_ SG_ 927 StatusBLEParameter_FBD_HR_Status "contains acknowledge to connection parameter";
CM_ SG_ 922 StatusBLEParameter_FBD_Miko_Addr "addressing of the BLE nodes";
CM_ SG_ 922 StatusBLEParameter_FBD_Miko_IRKL "contains ConnectionID";
CM_ SG_ 922 StatusBLEParameter_FBD_Miko_Stat "contains acknowledge to connection parameter";
CM_ SG_ 930 StatusBLEParameter_FBD_MM_Addres "addressing of the BLE nodes";
CM_ SG_ 930 StatusBLEParameter_FBD_MM_IRKLis "contains ConnectionID";
CM_ SG_ 930 StatusBLEParameter_FBD_MM_Status "contains acknowledge to connection parameter";
CM_ SG_ 908 StatusBLEParameter_FBD_SML_Addre "addressing of the BLE nodes";
CM_ SG_ 908 StatusBLEParameter_FBD_SML_IRKLi "contains ConnectionID";
CM_ SG_ 908 StatusBLEParameter_FBD_SML_Statu "contains acknowledge to connection parameter";
CM_ SG_ 918 StatusBLEParameter_FBD_SMR_Addre "addressing of the BLE nodes";
CM_ SG_ 918 StatusBLEParameter_FBD_SMR_IRKLi "contains ConnectionID";
CM_ SG_ 918 StatusBLEParameter_FBD_SMR_Statu "contains acknowledge to connection parameter";
CM_ SG_ 923 StatusBLEParameter_FBD_Trunk_Add "addressing of the BLE nodes";
CM_ SG_ 923 StatusBLEParameter_FBD_Trunk_IRK "contains ConnectionID";
CM_ SG_ 923 StatusBLEParameter_FBD_Trunk_Sta "contains acknowledge to connection parameter";
CM_ SG_ 924 StatusBLEParameter_FBD_VL_Addres "addressing of the BLE nodes";
CM_ SG_ 924 StatusBLEParameter_FBD_VL_IRKLis "contains ConnectionID";
CM_ SG_ 924 StatusBLEParameter_FBD_VL_Status "contains acknowledge to connection parameter";
CM_ SG_ 920 StatusBLEParameter_FBD_VM_Addres "addressing of the BLE nodes";
CM_ SG_ 920 StatusBLEParameter_FBD_VM_IRKLis "contains ConnectionID";
CM_ SG_ 920 StatusBLEParameter_FBD_VM_Status "contains acknowledge to connection parameter";
CM_ SG_ 925 StatusBLEParameter_FBD_VR_Addres "addressing of the BLE nodes";
CM_ SG_ 925 StatusBLEParameter_FBD_VR_IRKLis "contains ConnectionID";
CM_ SG_ 925 StatusBLEParameter_FBD_VR_Status "contains acknowledge to connection parameter";
CM_ SG_ 536 StatusBLERSSIRangingIntentFBD_HL "function RSSI based ranging intent active/deactivated";
CM_ SG_ 536 StatusBLERSSIRangingIntentFBD__2 "Time in ms (Range: 0ms ... 65532ms / step: 1ms)";
CM_ SG_ 536 StatusBLERSSIRangingIntentFBD__3 "number of consecutive increasing RSSI meassurements";
CM_ SG_ 536 StatusBLERSSIRangingIntentFBD__4 "contaíns multi RSSI Intent";
CM_ SG_ 536 StatusBLERSSIRangingIntentFBD__5 "contains IRK List ID";
CM_ SG_ 536 StatusBLERSSIRangingIntentFBD__6 "contains minimum number of anchors for ranging intent";
CM_ SG_ 536 StatusBLERSSIRangingIntentFBD__7 "contains device group setting";
CM_ SG_ 531 StatusBLERSSIRangingIntentFBD_HM "function RSSI based ranging intent active/deactivated";
CM_ SG_ 531 StatusBLERSSIRangingIntentFBD__2 "Time in ms (Range: 0ms ... 65532ms / step: 1ms)";
CM_ SG_ 531 StatusBLERSSIRangingIntentFBD__3 "number of consecutive increasing RSSI meassurements";
CM_ SG_ 531 StatusBLERSSIRangingIntentFBD__4 "contaíns multi RSSI Intent";
CM_ SG_ 531 StatusBLERSSIRangingIntentFBD__5 "contains IRK List ID";
CM_ SG_ 531 StatusBLERSSIRangingIntentFBD__6 "contains minimum number of anchors for ranging intent";
CM_ SG_ 531 StatusBLERSSIRangingIntentFBD__7 "contains device group setting";
CM_ SG_ 537 StatusBLERSSIRangingIntentFBD_HR "function RSSI based ranging intent active/deactivated";
CM_ SG_ 537 StatusBLERSSIRangingIntentFBD__2 "Time in ms (Range: 0ms ... 65532ms / step: 1ms)";
CM_ SG_ 537 StatusBLERSSIRangingIntentFBD__3 "number of consecutive increasing RSSI meassurements";
CM_ SG_ 537 StatusBLERSSIRangingIntentFBD__4 "contaíns multi RSSI Intent";
CM_ SG_ 537 StatusBLERSSIRangingIntentFBD__5 "contains IRK List ID";
CM_ SG_ 537 StatusBLERSSIRangingIntentFBD__6 "contains minimum number of anchors for ranging intent";
CM_ SG_ 537 StatusBLERSSIRangingIntentFBD__7 "contains device group setting";
CM_ SG_ 532 StatusBLERSSIRangingIntentFBD_Mi "function RSSI based ranging intent active/deactivated";
CM_ SG_ 532 StatusBLERSSIRangingIntentFBD__2 "Time in ms (Range: 0ms ... 65532ms / step: 1ms)";
CM_ SG_ 532 StatusBLERSSIRangingIntentFBD__3 "number of consecutive increasing RSSI meassurements";
CM_ SG_ 532 StatusBLERSSIRangingIntentFBD__4 "contaíns multi RSSI Intent";
CM_ SG_ 532 StatusBLERSSIRangingIntentFBD__5 "contains IRK List ID";
CM_ SG_ 532 StatusBLERSSIRangingIntentFBD__6 "contains minimum number of anchors for ranging intent";
CM_ SG_ 532 StatusBLERSSIRangingIntentFBD__7 "contains device group setting";
CM_ SG_ 540 StatusBLERSSIRangingIntentFBD_MM "function RSSI based ranging intent active/deactivated";
CM_ SG_ 540 StatusBLERSSIRangingIntentFBD__2 "Time in ms (Range: 0ms ... 65532ms / step: 1ms)";
CM_ SG_ 540 StatusBLERSSIRangingIntentFBD__3 "number of consecutive increasing RSSI meassurements";
CM_ SG_ 540 StatusBLERSSIRangingIntentFBD__4 "contaíns multi RSSI Intent";
CM_ SG_ 540 StatusBLERSSIRangingIntentFBD__5 "contains IRK List ID";
CM_ SG_ 540 StatusBLERSSIRangingIntentFBD__6 "contains minimum number of anchors for ranging intent";
CM_ SG_ 540 StatusBLERSSIRangingIntentFBD__7 "contains device group setting";
CM_ SG_ 533 StatusBLERSSIRangingIntentFBD_Tr "function RSSI based ranging intent active/deactivated";
CM_ SG_ 533 StatusBLERSSIRangingIntentFBD__2 "Time in ms (Range: 0ms ... 65532ms / step: 1ms)";
CM_ SG_ 533 StatusBLERSSIRangingIntentFBD__3 "number of consecutive increasing RSSI meassurements";
CM_ SG_ 533 StatusBLERSSIRangingIntentFBD__4 "contaíns multi RSSI Intent";
CM_ SG_ 533 StatusBLERSSIRangingIntentFBD__5 "contains IRK List ID";
CM_ SG_ 533 StatusBLERSSIRangingIntentFBD__6 "contains minimum number of anchors for ranging intent";
CM_ SG_ 533 StatusBLERSSIRangingIntentFBD__7 "contains device group setting";
CM_ SG_ 534 StatusBLERSSIRangingIntentFBD_VL "function RSSI based ranging intent active/deactivated";
CM_ SG_ 534 StatusBLERSSIRangingIntentFBD__2 "Time in ms (Range: 0ms ... 65532ms / step: 1ms)";
CM_ SG_ 534 StatusBLERSSIRangingIntentFBD__3 "number of consecutive increasing RSSI meassurements";
CM_ SG_ 534 StatusBLERSSIRangingIntentFBD__4 "contaíns multi RSSI Intent";
CM_ SG_ 534 StatusBLERSSIRangingIntentFBD__5 "contains IRK List ID";
CM_ SG_ 534 StatusBLERSSIRangingIntentFBD__6 "contains minimum number of anchors for ranging intent";
CM_ SG_ 534 StatusBLERSSIRangingIntentFBD__7 "contains device group setting";
CM_ SG_ 530 StatusBLERSSIRangingIntentFBD_VM "function RSSI based ranging intent active/deactivated";
CM_ SG_ 530 StatusBLERSSIRangingIntentFBD__2 "Time in ms (Range: 0ms ... 65532ms / step: 1ms)";
CM_ SG_ 530 StatusBLERSSIRangingIntentFBD__3 "number of consecutive increasing RSSI meassurements";
CM_ SG_ 530 StatusBLERSSIRangingIntentFBD__4 "contaíns multi RSSI Intent";
CM_ SG_ 530 StatusBLERSSIRangingIntentFBD__5 "contains IRK List ID";
CM_ SG_ 530 StatusBLERSSIRangingIntentFBD__6 "contains minimum number of anchors for ranging intent";
CM_ SG_ 530 StatusBLERSSIRangingIntentFBD__7 "contains device group setting";
CM_ SG_ 535 StatusBLERSSIRangingIntentFBD_VR "function RSSI based ranging intent active/deactivated";
CM_ SG_ 535 StatusBLERSSIRangingIntentFBD__2 "Time in ms (Range: 0ms ... 65532ms / step: 1ms)";
CM_ SG_ 535 StatusBLERSSIRangingIntentFBD__3 "number of consecutive increasing RSSI meassurements";
CM_ SG_ 535 StatusBLERSSIRangingIntentFBD__4 "contaíns multi RSSI Intent";
CM_ SG_ 535 StatusBLERSSIRangingIntentFBD__5 "contains IRK List ID";
CM_ SG_ 535 StatusBLERSSIRangingIntentFBD__6 "contains minimum number of anchors for ranging intent";
CM_ SG_ 535 StatusBLERSSIRangingIntentFBD__7 "contains device group setting";
CM_ SG_ 216 StatusBLESettingsFBD_HL_BLEOpera "contains the BLE operation mode";
CM_ SG_ 216 StatusBLESettingsFBD_HL_Advertis "contains the advertising interval in case advertising is active";
CM_ SG_ 216 StatusBLESettingsFBD_HL_Connecti "contains the scanning parameters in case scanning is active";
CM_ SG_ 216 StatusBLESettingsFBD_HL_IRKListI "contains status of LELR mode";
CM_ SG_ 216 StatusBLESettingsFBD_HL_Settings "contains the LELR mode in case it is active";
CM_ SG_ 216 StatusBLESettingsFBD_HL_LR500_Ad "contains the advertising interval for LELR 500Kb in case advertising is active";
CM_ SG_ 216 StatusBLESettingsFBD_HL_LR125_Ad "contains the advertising interval for LELR 125Kb in case advertising is active";
CM_ SG_ 216 StatusBLESettingsFBD_HL_Extended "contains status of extended advertising";
CM_ SG_ 216 StatusBLESettingsFBD_HL_TxPower "contains The Tx power";
CM_ SG_ 216 StatusBLESettingsFBD_HL_PSM "contains PSM for L2CAP connection oriented channel";
CM_ SG_ 216 StatusBLESettingsFBD_HL_RPAFrequ "contains the frequency of RPA change";
CM_ SG_ 216 StatusBLESettingsFBD_HL_DCKVersi "contains the protocol version of DCK system according to CCC specification";
CM_ SG_ 216 StatusBLESettingsFBD_HL_ScanRequ "contains the BLE scan request mode";
CM_ SG_ 211 StatusBLESettingsFBD_HM_BLEOpera "contains the BLE operation mode";
CM_ SG_ 211 StatusBLESettingsFBD_HM_Advertis "contains the advertising interval in case advertising is active";
CM_ SG_ 211 StatusBLESettingsFBD_HM_Connecti "contains the scanning parameters in case scanning is active";
CM_ SG_ 211 StatusBLESettingsFBD_HM_IRKListI "contains status of LELR mode";
CM_ SG_ 211 StatusBLESettingsFBD_HM_Settings "contains the LELR mode in case it is active";
CM_ SG_ 211 StatusBLESettingsFBD_HM_LR500_Ad "contains the advertising interval for LELR 500Kb in case advertising is active";
CM_ SG_ 211 StatusBLESettingsFBD_HM_LR125_Ad "contains the advertising interval for LELR 125Kb in case advertising is active";
CM_ SG_ 211 StatusBLESettingsFBD_HM_Extended "contains status of extended advertising";
CM_ SG_ 211 StatusBLESettingsFBD_HM_TxPower "contains The Tx power";
CM_ SG_ 211 StatusBLESettingsFBD_HM_PSM "contains PSM for L2CAP connection oriented channel";
CM_ SG_ 211 StatusBLESettingsFBD_HM_RPAFrequ "contains the frequency of RPA change";
CM_ SG_ 211 StatusBLESettingsFBD_HM_DCKVersi "contains the protocol version of DCK system according to CCC specification";
CM_ SG_ 211 StatusBLESettingsFBD_HM_ScanRequ "contains the BLE scan request mode";
CM_ SG_ 217 StatusBLESettingsFBD_HR_BLEOpera "contains the BLE operation mode";
CM_ SG_ 217 StatusBLESettingsFBD_HR_Advertis "contains the advertising interval in case advertising is active";
CM_ SG_ 217 StatusBLESettingsFBD_HR_Connecti "contains the scanning parameters in case scanning is active";
CM_ SG_ 217 StatusBLESettingsFBD_HR_IRKListI "contains status of LELR mode";
CM_ SG_ 217 StatusBLESettingsFBD_HR_Settings "contains the LELR mode in case it is active";
CM_ SG_ 217 StatusBLESettingsFBD_HR_LR500_Ad "contains the advertising interval for LELR 500Kb in case advertising is active";
CM_ SG_ 217 StatusBLESettingsFBD_HR_LR125_Ad "contains the advertising interval for LELR 125Kb in case advertising is active";
CM_ SG_ 217 StatusBLESettingsFBD_HR_Extended "contains status of extended advertising";
CM_ SG_ 217 StatusBLESettingsFBD_HR_TxPower "contains The Tx power";
CM_ SG_ 217 StatusBLESettingsFBD_HR_PSM "contains PSM for L2CAP connection oriented channel";
CM_ SG_ 217 StatusBLESettingsFBD_HR_RPAFrequ "contains the frequency of RPA change";
CM_ SG_ 217 StatusBLESettingsFBD_HR_DCKVersi "contains the protocol version of DCK system according to CCC specification";
CM_ SG_ 217 StatusBLESettingsFBD_HR_ScanRequ "contains the BLE scan request mode";
CM_ SG_ 212 StatusBLESettingsFBD_Miko_BLEOpe "contains the BLE operation mode";
CM_ SG_ 212 StatusBLESettingsFBD_Miko_Advert "contains the advertising interval in case advertising is active";
CM_ SG_ 212 StatusBLESettingsFBD_Miko_Connec "contains the scanning parameters in case scanning is active";
CM_ SG_ 212 StatusBLESettingsFBD_Miko_IRKLis "contains status of LELR mode";
CM_ SG_ 212 StatusBLESettingsFBD_Miko_Settin "contains the LELR mode in case it is active";
CM_ SG_ 212 StatusBLESettingsFBD_Miko_LR500_ "contains the advertising interval for LELR 500Kb in case advertising is active";
CM_ SG_ 212 StatusBLESettingsFBD_Miko_LR125_ "contains the advertising interval for LELR 125Kb in case advertising is active";
CM_ SG_ 212 StatusBLESettingsFBD_Miko_Extend "contains status of extended advertising";
CM_ SG_ 212 StatusBLESettingsFBD_Miko_TxPowe "contains The Tx power";
CM_ SG_ 212 StatusBLESettingsFBD_Miko_PSM "contains PSM for L2CAP connection oriented channel";
CM_ SG_ 212 StatusBLESettingsFBD_Miko_RPAFre "contains the frequency of RPA change";
CM_ SG_ 212 StatusBLESettingsFBD_Miko_DCKVer "contains the protocol version of DCK system according to CCC specification";
CM_ SG_ 212 StatusBLESettingsFBD_Miko_ScanRe "contains the BLE scan request mode";
CM_ SG_ 240 StatusBLESettingsFBD_MM_BLEOpera "contains the BLE operation mode";
CM_ SG_ 240 StatusBLESettingsFBD_MM_Advertis "contains the advertising interval in case advertising is active";
CM_ SG_ 240 StatusBLESettingsFBD_MM_Connecti "contains the scanning parameters in case scanning is active";
CM_ SG_ 240 StatusBLESettingsFBD_MM_IRKListI "contains status of LELR mode";
CM_ SG_ 240 StatusBLESettingsFBD_MM_Settings "contains the LELR mode in case it is active";
CM_ SG_ 240 StatusBLESettingsFBD_MM_LR500_Ad "contains the advertising interval for LELR 500Kb in case advertising is active";
CM_ SG_ 240 StatusBLESettingsFBD_MM_LR125_Ad "contains the advertising interval for LELR 125Kb in case advertising is active";
CM_ SG_ 240 StatusBLESettingsFBD_MM_Extended "contains status of extended advertising";
CM_ SG_ 240 StatusBLESettingsFBD_MM_TxPower "contains The Tx power";
CM_ SG_ 240 StatusBLESettingsFBD_MM_PSM "contains PSM for L2CAP connection oriented channel";
CM_ SG_ 240 StatusBLESettingsFBD_MM_RPAFrequ "contains the frequency of RPA change";
CM_ SG_ 240 StatusBLESettingsFBD_MM_DCKVersi "contains the protocol version of DCK system according to CCC specification";
CM_ SG_ 240 StatusBLESettingsFBD_MM_ScanRequ "contains the BLE scan request mode";
CM_ SG_ 213 StatusBLESettingsFBD_Trunk_BLEOp "contains the BLE operation mode";
CM_ SG_ 213 StatusBLESettingsFBD_Trunk_Adver "contains the advertising interval in case advertising is active";
CM_ SG_ 213 StatusBLESettingsFBD_Trunk_Conne "contains the scanning parameters in case scanning is active";
CM_ SG_ 213 StatusBLESettingsFBD_Trunk_IRKLi "contains status of LELR mode";
CM_ SG_ 213 StatusBLESettingsFBD_Trunk_Setti "contains the LELR mode in case it is active";
CM_ SG_ 213 StatusBLESettingsFBD_Trunk_LR500 "contains the advertising interval for LELR 500Kb in case advertising is active";
CM_ SG_ 213 StatusBLESettingsFBD_Trunk_LR125 "contains the advertising interval for LELR 125Kb in case advertising is active";
CM_ SG_ 213 StatusBLESettingsFBD_Trunk_Exten "contains status of extended advertising";
CM_ SG_ 213 StatusBLESettingsFBD_Trunk_TxPow "contains The Tx power";
CM_ SG_ 213 StatusBLESettingsFBD_Trunk_PSM "contains PSM for L2CAP connection oriented channel";
CM_ SG_ 213 StatusBLESettingsFBD_Trunk_RPAFr "contains the frequency of RPA change";
CM_ SG_ 213 StatusBLESettingsFBD_Trunk_DCKVe "contains the protocol version of DCK system according to CCC specification";
CM_ SG_ 213 StatusBLESettingsFBD_Trunk_ScanR "contains the BLE scan request mode";
CM_ SG_ 214 StatusBLESettingsFBD_VL_BLEOpera "contains the BLE operation mode";
CM_ SG_ 214 StatusBLESettingsFBD_VL_Advertis "contains the advertising interval in case advertising is active";
CM_ SG_ 214 StatusBLESettingsFBD_VL_Connecti "contains the scanning parameters in case scanning is active";
CM_ SG_ 214 StatusBLESettingsFBD_VL_IRKListI "contains status of LELR mode";
CM_ SG_ 214 StatusBLESettingsFBD_VL_Settings "contains the LELR mode in case it is active";
CM_ SG_ 214 StatusBLESettingsFBD_VL_LR500_Ad "contains the advertising interval for LELR 500Kb in case advertising is active";
CM_ SG_ 214 StatusBLESettingsFBD_VL_LR125_Ad "contains the advertising interval for LELR 125Kb in case advertising is active";
CM_ SG_ 214 StatusBLESettingsFBD_VL_Extended "contains status of extended advertising";
CM_ SG_ 214 StatusBLESettingsFBD_VL_TxPower "contains The Tx power";
CM_ SG_ 214 StatusBLESettingsFBD_VL_PSM "contains PSM for L2CAP connection oriented channel";
CM_ SG_ 214 StatusBLESettingsFBD_VL_RPAFrequ "contains the frequency of RPA change";
CM_ SG_ 214 StatusBLESettingsFBD_VL_DCKVersi "contains the protocol version of DCK system according to CCC specification";
CM_ SG_ 214 StatusBLESettingsFBD_VL_ScanRequ "contains the BLE scan request mode";
CM_ SG_ 210 StatusBLESettingsFBD_VM_BLEOpera "contains the BLE operation mode";
CM_ SG_ 210 StatusBLESettingsFBD_VM_Advertis "contains the advertising interval in case advertising is active";
CM_ SG_ 210 StatusBLESettingsFBD_VM_Connecti "contains the scanning parameters in case scanning is active";
CM_ SG_ 210 StatusBLESettingsFBD_VM_IRKListI "contains status of LELR mode";
CM_ SG_ 210 StatusBLESettingsFBD_VM_Settings "contains the LELR mode in case it is active";
CM_ SG_ 210 StatusBLESettingsFBD_VM_LR500_Ad "contains the advertising interval for LELR 500Kb in case advertising is active";
CM_ SG_ 210 StatusBLESettingsFBD_VM_LR125_Ad "contains the advertising interval for LELR 125Kb in case advertising is active";
CM_ SG_ 210 StatusBLESettingsFBD_VM_Extended "contains status of extended advertising";
CM_ SG_ 210 StatusBLESettingsFBD_VM_TxPower "contains The Tx power";
CM_ SG_ 210 StatusBLESettingsFBD_VM_PSM "contains PSM for L2CAP connection oriented channel";
CM_ SG_ 210 StatusBLESettingsFBD_VM_RPAFrequ "contains the frequency of RPA change";
CM_ SG_ 210 StatusBLESettingsFBD_VM_DCKVersi "contains the protocol version of DCK system according to CCC specification";
CM_ SG_ 210 StatusBLESettingsFBD_VM_ScanRequ "contains the BLE scan request mode";
CM_ SG_ 215 StatusBLESettingsFBD_VR_BLEOpera "contains the BLE operation mode";
CM_ SG_ 215 StatusBLESettingsFBD_VR_Advertis "contains the advertising interval in case advertising is active";
CM_ SG_ 215 StatusBLESettingsFBD_VR_Connecti "contains the scanning parameters in case scanning is active";
CM_ SG_ 215 StatusBLESettingsFBD_VR_IRKListI "contains status of LELR mode";
CM_ SG_ 215 StatusBLESettingsFBD_VR_Settings "contains the LELR mode in case it is active";
CM_ SG_ 215 StatusBLESettingsFBD_VR_LR500_Ad "contains the advertising interval for LELR 500Kb in case advertising is active";
CM_ SG_ 215 StatusBLESettingsFBD_VR_LR125_Ad "contains the advertising interval for LELR 125Kb in case advertising is active";
CM_ SG_ 215 StatusBLESettingsFBD_VR_Extended "contains status of extended advertising";
CM_ SG_ 215 StatusBLESettingsFBD_VR_TxPower "contains The Tx power";
CM_ SG_ 215 StatusBLESettingsFBD_VR_PSM "contains PSM for L2CAP connection oriented channel";
CM_ SG_ 215 StatusBLESettingsFBD_VR_RPAFrequ "contains the frequency of RPA change";
CM_ SG_ 215 StatusBLESettingsFBD_VR_DCKVersi "contains the protocol version of DCK system according to CCC specification";
CM_ SG_ 215 StatusBLESettingsFBD_VR_ScanRequ "contains the BLE scan request mode";
CM_ SG_ 396 StatusBLESettingsPriorityFBD_HL_ "number of active BLE connections";
CM_ SG_ 396 StatusBLESettingsPriorityFBD_H_2 "connection ID1";
CM_ SG_ 396 StatusBLESettingsPriorityFBD_H_3 "priority to connection ID1";
CM_ SG_ 396 StatusBLESettingsPriorityFBD_H_4 "connection ID2";
CM_ SG_ 396 StatusBLESettingsPriorityFBD_H_5 "priority to connection ID2";
CM_ SG_ 396 StatusBLESettingsPriorityFBD_H_6 "connection ID3";
CM_ SG_ 396 StatusBLESettingsPriorityFBD_H_7 "priority to connection ID3";
CM_ SG_ 396 StatusBLESettingsPriorityFBD_H_8 "connection ID4";
CM_ SG_ 396 StatusBLESettingsPriorityFBD_H_9 "priority to connection ID4";
CM_ SG_ 396 StatusBLESettingsPriorityFBD__10 "connection ID5";
CM_ SG_ 396 StatusBLESettingsPriorityFBD__11 "priority to connection ID5";
CM_ SG_ 396 StatusBLESettingsPriorityFBD__12 "connection ID6";
CM_ SG_ 396 StatusBLESettingsPriorityFBD__13 "priority to connection ID6";
CM_ SG_ 396 StatusBLESettingsPriorityFBD__14 "connection ID7";
CM_ SG_ 396 StatusBLESettingsPriorityFBD__15 "priority to connection ID7";
CM_ SG_ 396 StatusBLESettingsPriorityFBD__16 "connection ID8";
CM_ SG_ 396 StatusBLESettingsPriorityFBD__17 "priority to connection ID8";
CM_ SG_ 391 StatusBLESettingsPriorityFBD_HM_ "number of active BLE connections";
CM_ SG_ 391 StatusBLESettingsPriorityFBD_H_2 "connection ID1";
CM_ SG_ 391 StatusBLESettingsPriorityFBD_H_3 "priority to connection ID1";
CM_ SG_ 391 StatusBLESettingsPriorityFBD_H_4 "connection ID2";
CM_ SG_ 391 StatusBLESettingsPriorityFBD_H_5 "priority to connection ID2";
CM_ SG_ 391 StatusBLESettingsPriorityFBD_H_6 "connection ID3";
CM_ SG_ 391 StatusBLESettingsPriorityFBD_H_7 "priority to connection ID3";
CM_ SG_ 391 StatusBLESettingsPriorityFBD_H_8 "connection ID4";
CM_ SG_ 391 StatusBLESettingsPriorityFBD_H_9 "priority to connection ID4";
CM_ SG_ 391 StatusBLESettingsPriorityFBD__10 "connection ID5";
CM_ SG_ 391 StatusBLESettingsPriorityFBD__11 "priority to connection ID5";
CM_ SG_ 391 StatusBLESettingsPriorityFBD__12 "connection ID6";
CM_ SG_ 391 StatusBLESettingsPriorityFBD__13 "priority to connection ID6";
CM_ SG_ 391 StatusBLESettingsPriorityFBD__14 "connection ID7";
CM_ SG_ 391 StatusBLESettingsPriorityFBD__15 "priority to connection ID7";
CM_ SG_ 391 StatusBLESettingsPriorityFBD__16 "connection ID8";
CM_ SG_ 391 StatusBLESettingsPriorityFBD__17 "priority to connection ID8";
CM_ SG_ 397 StatusBLESettingsPriorityFBD_HR_ "number of active BLE connections";
CM_ SG_ 397 StatusBLESettingsPriorityFBD_H_2 "connection ID1";
CM_ SG_ 397 StatusBLESettingsPriorityFBD_H_3 "priority to connection ID1";
CM_ SG_ 397 StatusBLESettingsPriorityFBD_H_4 "connection ID2";
CM_ SG_ 397 StatusBLESettingsPriorityFBD_H_5 "priority to connection ID2";
CM_ SG_ 397 StatusBLESettingsPriorityFBD_H_6 "connection ID3";
CM_ SG_ 397 StatusBLESettingsPriorityFBD_H_7 "priority to connection ID3";
CM_ SG_ 397 StatusBLESettingsPriorityFBD_H_8 "connection ID4";
CM_ SG_ 397 StatusBLESettingsPriorityFBD_H_9 "priority to connection ID4";
CM_ SG_ 397 StatusBLESettingsPriorityFBD__10 "connection ID5";
CM_ SG_ 397 StatusBLESettingsPriorityFBD__11 "priority to connection ID5";
CM_ SG_ 397 StatusBLESettingsPriorityFBD__12 "connection ID6";
CM_ SG_ 397 StatusBLESettingsPriorityFBD__13 "priority to connection ID6";
CM_ SG_ 397 StatusBLESettingsPriorityFBD__14 "connection ID7";
CM_ SG_ 397 StatusBLESettingsPriorityFBD__15 "priority to connection ID7";
CM_ SG_ 397 StatusBLESettingsPriorityFBD__16 "connection ID8";
CM_ SG_ 397 StatusBLESettingsPriorityFBD__17 "priority to connection ID8";
CM_ SG_ 392 StatusBLESettingsPriorityFBD_Mik "number of active BLE connections";
CM_ SG_ 392 StatusBLESettingsPriorityFBD_M_2 "connection ID1";
CM_ SG_ 392 StatusBLESettingsPriorityFBD_M_3 "priority to connection ID1";
CM_ SG_ 392 StatusBLESettingsPriorityFBD_M_4 "connection ID2";
CM_ SG_ 392 StatusBLESettingsPriorityFBD_M_5 "priority to connection ID2";
CM_ SG_ 392 StatusBLESettingsPriorityFBD_M_6 "connection ID3";
CM_ SG_ 392 StatusBLESettingsPriorityFBD_M_7 "priority to connection ID3";
CM_ SG_ 392 StatusBLESettingsPriorityFBD_M_8 "connection ID4";
CM_ SG_ 392 StatusBLESettingsPriorityFBD_M_9 "priority to connection ID4";
CM_ SG_ 392 StatusBLESettingsPriorityFBD__10 "connection ID5";
CM_ SG_ 392 StatusBLESettingsPriorityFBD__11 "priority to connection ID5";
CM_ SG_ 392 StatusBLESettingsPriorityFBD__12 "connection ID6";
CM_ SG_ 392 StatusBLESettingsPriorityFBD__13 "priority to connection ID6";
CM_ SG_ 392 StatusBLESettingsPriorityFBD__14 "connection ID7";
CM_ SG_ 392 StatusBLESettingsPriorityFBD__15 "priority to connection ID7";
CM_ SG_ 392 StatusBLESettingsPriorityFBD__16 "connection ID8";
CM_ SG_ 392 StatusBLESettingsPriorityFBD__17 "priority to connection ID8";
CM_ SG_ 823 StatusBLESettingsPriorityFBD_MM_ "number of active BLE connections";
CM_ SG_ 823 StatusBLESettingsPriorityFBD_M_2 "connection ID1";
CM_ SG_ 823 StatusBLESettingsPriorityFBD_M_3 "priority to connection ID1";
CM_ SG_ 823 StatusBLESettingsPriorityFBD_M_4 "connection ID2";
CM_ SG_ 823 StatusBLESettingsPriorityFBD_M_5 "priority to connection ID2";
CM_ SG_ 823 StatusBLESettingsPriorityFBD_M_6 "connection ID3";
CM_ SG_ 823 StatusBLESettingsPriorityFBD_M_7 "priority to connection ID3";
CM_ SG_ 823 StatusBLESettingsPriorityFBD_M_8 "connection ID4";
CM_ SG_ 823 StatusBLESettingsPriorityFBD_M_9 "priority to connection ID4";
CM_ SG_ 823 StatusBLESettingsPriorityFBD__10 "connection ID5";
CM_ SG_ 823 StatusBLESettingsPriorityFBD__11 "priority to connection ID5";
CM_ SG_ 823 StatusBLESettingsPriorityFBD__12 "connection ID6";
CM_ SG_ 823 StatusBLESettingsPriorityFBD__13 "priority to connection ID6";
CM_ SG_ 823 StatusBLESettingsPriorityFBD__14 "connection ID7";
CM_ SG_ 823 StatusBLESettingsPriorityFBD__15 "priority to connection ID7";
CM_ SG_ 823 StatusBLESettingsPriorityFBD__16 "connection ID8";
CM_ SG_ 823 StatusBLESettingsPriorityFBD__17 "priority to connection ID8";
CM_ SG_ 393 StatusBLESettingsPriorityFBD_Tru "number of active BLE connections";
CM_ SG_ 393 StatusBLESettingsPriorityFBD_T_2 "connection ID1";
CM_ SG_ 393 StatusBLESettingsPriorityFBD_T_3 "priority to connection ID1";
CM_ SG_ 393 StatusBLESettingsPriorityFBD_T_4 "connection ID2";
CM_ SG_ 393 StatusBLESettingsPriorityFBD_T_5 "priority to connection ID2";
CM_ SG_ 393 StatusBLESettingsPriorityFBD_T_6 "connection ID3";
CM_ SG_ 393 StatusBLESettingsPriorityFBD_T_7 "priority to connection ID3";
CM_ SG_ 393 StatusBLESettingsPriorityFBD_T_8 "connection ID4";
CM_ SG_ 393 StatusBLESettingsPriorityFBD_T_9 "priority to connection ID4";
CM_ SG_ 393 StatusBLESettingsPriorityFBD__10 "connection ID5";
CM_ SG_ 393 StatusBLESettingsPriorityFBD__11 "priority to connection ID5";
CM_ SG_ 393 StatusBLESettingsPriorityFBD__12 "connection ID6";
CM_ SG_ 393 StatusBLESettingsPriorityFBD__13 "priority to connection ID6";
CM_ SG_ 393 StatusBLESettingsPriorityFBD__14 "connection ID7";
CM_ SG_ 393 StatusBLESettingsPriorityFBD__15 "priority to connection ID7";
CM_ SG_ 393 StatusBLESettingsPriorityFBD__16 "connection ID8";
CM_ SG_ 393 StatusBLESettingsPriorityFBD__17 "priority to connection ID8";
CM_ SG_ 394 StatusBLESettingsPriorityFBD_VL_ "number of active BLE connections";
CM_ SG_ 394 StatusBLESettingsPriorityFBD_V_2 "connection ID1";
CM_ SG_ 394 StatusBLESettingsPriorityFBD_V_3 "priority to connection ID1";
CM_ SG_ 394 StatusBLESettingsPriorityFBD_V_4 "connection ID2";
CM_ SG_ 394 StatusBLESettingsPriorityFBD_V_5 "priority to connection ID2";
CM_ SG_ 394 StatusBLESettingsPriorityFBD_V_6 "connection ID3";
CM_ SG_ 394 StatusBLESettingsPriorityFBD_V_7 "priority to connection ID3";
CM_ SG_ 394 StatusBLESettingsPriorityFBD_V_8 "connection ID4";
CM_ SG_ 394 StatusBLESettingsPriorityFBD_V_9 "priority to connection ID4";
CM_ SG_ 394 StatusBLESettingsPriorityFBD__10 "connection ID5";
CM_ SG_ 394 StatusBLESettingsPriorityFBD__11 "priority to connection ID5";
CM_ SG_ 394 StatusBLESettingsPriorityFBD__12 "connection ID6";
CM_ SG_ 394 StatusBLESettingsPriorityFBD__13 "priority to connection ID6";
CM_ SG_ 394 StatusBLESettingsPriorityFBD__14 "connection ID7";
CM_ SG_ 394 StatusBLESettingsPriorityFBD__15 "priority to connection ID7";
CM_ SG_ 394 StatusBLESettingsPriorityFBD__16 "connection ID8";
CM_ SG_ 394 StatusBLESettingsPriorityFBD__17 "priority to connection ID8";
CM_ SG_ 390 StatusBLESettingsPriorityFBD_VM_ "number of active BLE connections";
CM_ SG_ 390 StatusBLESettingsPriorityFBD_V_2 "connection ID1";
CM_ SG_ 390 StatusBLESettingsPriorityFBD_V_3 "priority to connection ID1";
CM_ SG_ 390 StatusBLESettingsPriorityFBD_V_4 "connection ID2";
CM_ SG_ 390 StatusBLESettingsPriorityFBD_V_5 "priority to connection ID2";
CM_ SG_ 390 StatusBLESettingsPriorityFBD_V_6 "connection ID3";
CM_ SG_ 390 StatusBLESettingsPriorityFBD_V_7 "priority to connection ID3";
CM_ SG_ 390 StatusBLESettingsPriorityFBD_V_8 "connection ID4";
CM_ SG_ 390 StatusBLESettingsPriorityFBD_V_9 "priority to connection ID4";
CM_ SG_ 390 StatusBLESettingsPriorityFBD__10 "connection ID5";
CM_ SG_ 390 StatusBLESettingsPriorityFBD__11 "priority to connection ID5";
CM_ SG_ 390 StatusBLESettingsPriorityFBD__12 "connection ID6";
CM_ SG_ 390 StatusBLESettingsPriorityFBD__13 "priority to connection ID6";
CM_ SG_ 390 StatusBLESettingsPriorityFBD__14 "connection ID7";
CM_ SG_ 390 StatusBLESettingsPriorityFBD__15 "priority to connection ID7";
CM_ SG_ 390 StatusBLESettingsPriorityFBD__16 "connection ID8";
CM_ SG_ 390 StatusBLESettingsPriorityFBD__17 "priority to connection ID8";
CM_ SG_ 395 StatusBLESettingsPriorityFBD_VR_ "number of active BLE connections";
CM_ SG_ 395 StatusBLESettingsPriorityFBD_V_2 "connection ID1";
CM_ SG_ 395 StatusBLESettingsPriorityFBD_V_3 "priority to connection ID1";
CM_ SG_ 395 StatusBLESettingsPriorityFBD_V_4 "connection ID2";
CM_ SG_ 395 StatusBLESettingsPriorityFBD_V_5 "priority to connection ID2";
CM_ SG_ 395 StatusBLESettingsPriorityFBD_V_6 "connection ID3";
CM_ SG_ 395 StatusBLESettingsPriorityFBD_V_7 "priority to connection ID3";
CM_ SG_ 395 StatusBLESettingsPriorityFBD_V_8 "connection ID4";
CM_ SG_ 395 StatusBLESettingsPriorityFBD_V_9 "priority to connection ID4";
CM_ SG_ 395 StatusBLESettingsPriorityFBD__10 "connection ID5";
CM_ SG_ 395 StatusBLESettingsPriorityFBD__11 "priority to connection ID5";
CM_ SG_ 395 StatusBLESettingsPriorityFBD__12 "connection ID6";
CM_ SG_ 395 StatusBLESettingsPriorityFBD__13 "priority to connection ID6";
CM_ SG_ 395 StatusBLESettingsPriorityFBD__14 "connection ID7";
CM_ SG_ 395 StatusBLESettingsPriorityFBD__15 "priority to connection ID7";
CM_ SG_ 395 StatusBLESettingsPriorityFBD__16 "connection ID8";
CM_ SG_ 395 StatusBLESettingsPriorityFBD__17 "priority to connection ID8";
CM_ SG_ 616 StatusConfigurationFBD_HL_UWBAnt "contains actual setting of UWB diversity mode";
CM_ SG_ 616 StatusConfigurationFBD_HL_UWBDut "contains actual setting of UWB duty cycle limit per sec (Range: 0 ... 126ms / step: 0,5ms)";
CM_ SG_ 616 StatusConfigurationFBD_HL_UWBD_2 "contains setting of maximal UWB duty cycle limit per hour (Range: 0 ... 25,2s / step: 0,1s)";
CM_ SG_ 616 StatusConfigurationFBD_HL_UWBD_3 "contains setting of maximal UWB duty cycle limit per second on average (Range: 0 ... 126ms / step: 0,5ms)";
CM_ SG_ 616 StatusConfigurationFBD_HL_FBDonl "contains setting of distance to the vehicle a FBD shall trigger CCU wake-up (range: 0m ... 25.2m / step: 0.1m)";
CM_ SG_ 616 StatusConfigurationFBD_HL_FBDo_2 "contains setting of ranging intent threshold in FBD-only mode (categorical: low, medium, high)";
CM_ SG_ 616 StatusConfigurationFBD_HL_FBDo_3 "contains setting of ranging session uptime (Range: 0 ... 252s / step: 1s)";
CM_ SG_ 616 StatusConfigurationFBD_HL_FBDo_4 "contains setting of ranging session uptime extension in seconds (range: 0s ... 252s / step: 1s)";
CM_ SG_ 616 StatusConfigurationFBD_HL_FBDo_5 "contains ranging session suspension timeout (invalid rangings) in seconds (range: 0s ... 252s / step: 1s)";
CM_ SG_ 616 StatusConfigurationFBD_HL_FBDo_6 "contains maximum ranging session uptime in seconds (range: 0s ... 252s / step: 1s)";
CM_ SG_ 616 StatusConfigurationFBD_HL_FBDo_7 "contains maximum total ranging uptime over all ranging sessions (range: 0min ... 252min / step: 1min)";
CM_ SG_ 616 StatusConfigurationFBD_HL_FBDo_8 "contains RAN multiplier for resuming ranging sessions (range: 1 ... 255 / step: 1)";
CM_ SG_ 616 StatusConfigurationFBD_HL_FBDo_9 "contains activity state of analytics data collection from customer fleet about feature usage";
CM_ SG_ 616 StatusConfigurationFBD_HL_Device "contains device group setting";
CM_ SG_ 616 StatusConfigurationFBD_HL_IRKLis "contains IRK list ID";
CM_ SG_ 611 StatusConfigurationFBD_HM_UWBAnt "contains actual setting of UWB diversity mode";
CM_ SG_ 611 StatusConfigurationFBD_HM_UWBDut "contains actual setting of UWB duty cycle limit per sec (Range: 0 ... 126ms / step: 0,5ms)";
CM_ SG_ 611 StatusConfigurationFBD_HM_UWBD_2 "contains setting of maximal UWB duty cycle limit per hour (Range: 0 ... 25,2s / step: 0,1s)";
CM_ SG_ 611 StatusConfigurationFBD_HM_UWBD_3 "contains setting of maximal UWB duty cycle limit per second on average (Range: 0 ... 126ms / step: 0,5ms)";
CM_ SG_ 611 StatusConfigurationFBD_HM_FBDonl "contains setting of distance to the vehicle a FBD shall trigger CCU wake-up (range: 0m ... 25.2m / step: 0.1m)";
CM_ SG_ 611 StatusConfigurationFBD_HM_FBDo_2 "contains setting of ranging intent threshold in FBD-only mode (categorical: low, medium, high)";
CM_ SG_ 611 StatusConfigurationFBD_HM_FBDo_3 "contains setting of ranging session uptime (Range: 0 ... 252s / step: 1s)";
CM_ SG_ 611 StatusConfigurationFBD_HM_FBDo_4 "contains setting of ranging session uptime extension in seconds (range: 0s ... 252s / step: 1s)";
CM_ SG_ 611 StatusConfigurationFBD_HM_FBDo_5 "contains ranging session suspension timeout (invalid rangings) in seconds (range: 0s ... 252s / step: 1s)";
CM_ SG_ 611 StatusConfigurationFBD_HM_FBDo_6 "contains maximum ranging session uptime in seconds (range: 0s ... 252s / step: 1s)";
CM_ SG_ 611 StatusConfigurationFBD_HM_FBDo_7 "contains maximum total ranging uptime over all ranging sessions (range: 0min ... 252min / step: 1min)";
CM_ SG_ 611 StatusConfigurationFBD_HM_FBDo_8 "contains RAN multiplier for resuming ranging sessions (range: 1 ... 255 / step: 1)";
CM_ SG_ 611 StatusConfigurationFBD_HM_FBDo_9 "contains activity state of analytics data collection from customer fleet about feature usage";
CM_ SG_ 611 StatusConfigurationFBD_HM_Device "contains device group setting";
CM_ SG_ 611 StatusConfigurationFBD_HM_IRKLis "contains IRK list ID";
CM_ SG_ 617 StatusConfigurationFBD_HR_UWBAnt "contains actual setting of UWB diversity mode";
CM_ SG_ 617 StatusConfigurationFBD_HR_UWBDut "contains actual setting of UWB duty cycle limit per sec (Range: 0 ... 126ms / step: 0,5ms)";
CM_ SG_ 617 StatusConfigurationFBD_HR_UWBD_2 "contains setting of maximal UWB duty cycle limit per hour (Range: 0 ... 25,2s / step: 0,1s)";
CM_ SG_ 617 StatusConfigurationFBD_HR_UWBD_3 "contains setting of maximal UWB duty cycle limit per second on average (Range: 0 ... 126ms / step: 0,5ms)";
CM_ SG_ 617 StatusConfigurationFBD_HR_FBDonl "contains setting of distance to the vehicle a FBD shall trigger CCU wake-up (range: 0m ... 25.2m / step: 0.1m)";
CM_ SG_ 617 StatusConfigurationFBD_HR_FBDo_2 "contains setting of ranging intent threshold in FBD-only mode (categorical: low, medium, high)";
CM_ SG_ 617 StatusConfigurationFBD_HR_FBDo_3 "contains setting of ranging session uptime (Range: 0 ... 252s / step: 1s)";
CM_ SG_ 617 StatusConfigurationFBD_HR_FBDo_4 "contains setting of ranging session uptime extension in seconds (range: 0s ... 252s / step: 1s)";
CM_ SG_ 617 StatusConfigurationFBD_HR_FBDo_5 "contains ranging session suspension timeout (invalid rangings) in seconds (range: 0s ... 252s / step: 1s)";
CM_ SG_ 617 StatusConfigurationFBD_HR_FBDo_6 "contains maximum ranging session uptime in seconds (range: 0s ... 252s / step: 1s)";
CM_ SG_ 617 StatusConfigurationFBD_HR_FBDo_7 "contains maximum total ranging uptime over all ranging sessions (range: 0min ... 252min / step: 1min)";
CM_ SG_ 617 StatusConfigurationFBD_HR_FBDo_8 "contains RAN multiplier for resuming ranging sessions (range: 1 ... 255 / step: 1)";
CM_ SG_ 617 StatusConfigurationFBD_HR_FBDo_9 "contains activity state of analytics data collection from customer fleet about feature usage";
CM_ SG_ 617 StatusConfigurationFBD_HR_Device "contains device group setting";
CM_ SG_ 617 StatusConfigurationFBD_HR_IRKLis "contains IRK list ID";
CM_ SG_ 612 StatusConfigurationFBD_Miko_UWBA "contains actual setting of UWB diversity mode";
CM_ SG_ 612 StatusConfigurationFBD_Miko_UWBD "contains actual setting of UWB duty cycle limit per sec (Range: 0 ... 126ms / step: 0,5ms)";
CM_ SG_ 612 StatusConfigurationFBD_Miko_UW_2 "contains setting of maximal UWB duty cycle limit per hour (Range: 0 ... 25,2s / step: 0,1s)";
CM_ SG_ 612 StatusConfigurationFBD_Miko_UW_3 "contains setting of maximal UWB duty cycle limit per second on average (Range: 0 ... 126ms / step: 0,5ms)";
CM_ SG_ 612 StatusConfigurationFBD_Miko_FBDo "contains setting of distance to the vehicle a FBD shall trigger CCU wake-up (range: 0m ... 25.2m / step: 0.1m)";
CM_ SG_ 612 StatusConfigurationFBD_Miko_FB_2 "contains setting of ranging intent threshold in FBD-only mode (categorical: low, medium, high)";
CM_ SG_ 612 StatusConfigurationFBD_Miko_FB_3 "contains setting of ranging session uptime (Range: 0 ... 252s / step: 1s)";
CM_ SG_ 612 StatusConfigurationFBD_Miko_FB_4 "contains setting of ranging session uptime extension in seconds (range: 0s ... 252s / step: 1s)";
CM_ SG_ 612 StatusConfigurationFBD_Miko_FB_5 "contains ranging session suspension timeout (invalid rangings) in seconds (range: 0s ... 252s / step: 1s)";
CM_ SG_ 612 StatusConfigurationFBD_Miko_FB_6 "contains maximum ranging session uptime in seconds (range: 0s ... 252s / step: 1s)";
CM_ SG_ 612 StatusConfigurationFBD_Miko_FB_7 "contains maximum total ranging uptime over all ranging sessions (range: 0min ... 252min / step: 1min)";
CM_ SG_ 612 StatusConfigurationFBD_Miko_FB_8 "contains RAN multiplier for resuming ranging sessions (range: 1 ... 255 / step: 1)";
CM_ SG_ 612 StatusConfigurationFBD_Miko_FB_9 "contains activity state of analytics data collection from customer fleet about feature usage";
CM_ SG_ 612 StatusConfigurationFBD_Miko_Devi "contains device group setting";
CM_ SG_ 612 StatusConfigurationFBD_Miko_IRKL "contains IRK list ID";
CM_ SG_ 691 StatusConfigurationFBD_MM_UWBAnt "contains actual setting of UWB diversity mode";
CM_ SG_ 691 StatusConfigurationFBD_MM_UWBDut "contains actual setting of UWB duty cycle limit per sec (Range: 0 ... 126ms / step: 0,5ms)";
CM_ SG_ 691 StatusConfigurationFBD_MM_UWBD_2 "contains setting of maximal UWB duty cycle limit per hour (Range: 0 ... 25,2s / step: 0,1s)";
CM_ SG_ 691 StatusConfigurationFBD_MM_UWBD_3 "contains setting of maximal UWB duty cycle limit per second on average (Range: 0 ... 126ms / step: 0,5ms)";
CM_ SG_ 691 StatusConfigurationFBD_MM_FBDonl "ontains setting of distance to the vehicle a FBD shall trigger CCU wake-up (range: 0m ... 25.2m / step: 0.1m)";
CM_ SG_ 691 StatusConfigurationFBD_MM_FBDo_2 "contains setting of ranging intent threshold in FBD-only mode (categorical: low, medium, high)";
CM_ SG_ 691 StatusConfigurationFBD_MM_FBDo_3 "contains setting of ranging session uptime (Range: 0 ... 252s / step: 1s)";
CM_ SG_ 691 StatusConfigurationFBD_MM_FBDo_4 "contains setting of ranging session uptime extension in seconds (range: 0s ... 252s / step: 1s)";
CM_ SG_ 691 StatusConfigurationFBD_MM_FBDo_5 "contains ranging session suspension timeout (invalid rangings) in seconds (range: 0s ... 252s / step: 1s)";
CM_ SG_ 691 StatusConfigurationFBD_MM_FBDo_6 "contains maximum ranging session uptime in seconds (range: 0s ... 252s / step: 1s)";
CM_ SG_ 691 StatusConfigurationFBD_MM_FBDo_7 "contains maximum total ranging uptime over all ranging sessions (range: 0min ... 252min / step: 1min)";
CM_ SG_ 691 StatusConfigurationFBD_MM_FBDo_8 "contains RAN multiplier for resuming ranging sessions (range: 1 ... 255 / step: 1)";
CM_ SG_ 691 StatusConfigurationFBD_MM_FBDo_9 "contains activity state of analytics data collection from customer fleet about feature usage";
CM_ SG_ 691 StatusConfigurationFBD_MM_Device "contains device group setting";
CM_ SG_ 691 StatusConfigurationFBD_MM_IRKLis "contains IRK list ID";
CM_ SG_ 613 StatusConfigurationFBD_Trunk_UWB "contains actual setting of UWB diversity mode";
CM_ SG_ 613 StatusConfigurationFBD_Trunk_U_2 "contains actual setting of UWB duty cycle limit per sec (Range: 0 ... 126ms / step: 0,5ms)";
CM_ SG_ 613 StatusConfigurationFBD_Trunk_U_3 "contains setting of maximal UWB duty cycle limit per hour (Range: 0 ... 25,2s / step: 0,1s)";
CM_ SG_ 613 StatusConfigurationFBD_Trunk_U_4 "contains setting of maximal UWB duty cycle limit per second on average (Range: 0 ... 126ms / step: 0,5ms)";
CM_ SG_ 613 StatusConfigurationFBD_Trunk_FBD "contains setting of distance to the vehicle a FBD shall trigger CCU wake-up (range: 0m ... 25.2m / step: 0.1m)";
CM_ SG_ 613 StatusConfigurationFBD_Trunk_F_2 "contains setting of ranging intent threshold in FBD-only mode (categorical: low, medium, high)";
CM_ SG_ 613 StatusConfigurationFBD_Trunk_F_3 "contains setting of ranging session uptime (Range: 0 ... 252s / step: 1s)";
CM_ SG_ 613 StatusConfigurationFBD_Trunk_F_4 "contains setting of ranging session uptime extension in seconds (range: 0s ... 252s / step: 1s)";
CM_ SG_ 613 StatusConfigurationFBD_Trunk_F_5 "contains ranging session suspension timeout (invalid rangings) in seconds (range: 0s ... 252s / step: 1s)";
CM_ SG_ 613 StatusConfigurationFBD_Trunk_F_6 "contains maximum ranging session uptime in seconds (range: 0s ... 252s / step: 1s)";
CM_ SG_ 613 StatusConfigurationFBD_Trunk_F_7 "contains maximum total ranging uptime over all ranging sessions (range: 0min ... 252min / step: 1min)";
CM_ SG_ 613 StatusConfigurationFBD_Trunk_F_8 "contains RAN multiplier for resuming ranging sessions (range: 1 ... 255 / step: 1)";
CM_ SG_ 613 StatusConfigurationFBD_Trunk_F_9 "contains activity state of analytics data collection from customer fleet about feature usage";
CM_ SG_ 613 StatusConfigurationFBD_Trunk_Dev "contains device group setting";
CM_ SG_ 613 StatusConfigurationFBD_Trunk_IRK "contains IRK list ID";
CM_ SG_ 614 StatusConfigurationFBD_VL_UWBAnt "contains actual setting of UWB diversity mode";
CM_ SG_ 614 StatusConfigurationFBD_VL_UWBDut "contains actual setting of UWB duty cycle limit per sec (Range: 0 ... 126ms / step: 0,5ms)";
CM_ SG_ 614 StatusConfigurationFBD_VL_UWBD_2 "contains setting of maximal UWB duty cycle limit per hour (Range: 0 ... 25,2s / step: 0,1s)";
CM_ SG_ 614 StatusConfigurationFBD_VL_UWBD_3 "contains setting of maximal UWB duty cycle limit per second on average (Range: 0 ... 126ms / step: 0,5ms)";
CM_ SG_ 614 StatusConfigurationFBD_VL_FBDonl "contains setting of distance to the vehicle a FBD shall trigger CCU wake-up (range: 0m ... 25.2m / step: 0.1m)";
CM_ SG_ 614 StatusConfigurationFBD_VL_FBDo_2 "contains setting of ranging intent threshold in FBD-only mode (categorical: low, medium, high)";
CM_ SG_ 614 StatusConfigurationFBD_VL_FBDo_3 "contains setting of ranging session uptime (Range: 0 ... 252s / step: 1s)";
CM_ SG_ 614 StatusConfigurationFBD_VL_FBDo_4 "contains setting of ranging session uptime extension in seconds (range: 0s ... 252s / step: 1s)";
CM_ SG_ 614 StatusConfigurationFBD_VL_FBDo_5 "contains ranging session suspension timeout (invalid rangings) in seconds (range: 0s ... 252s / step: 1s)";
CM_ SG_ 614 StatusConfigurationFBD_VL_FBDo_6 "contains maximum ranging session uptime in seconds (range: 0s ... 252s / step: 1s)";
CM_ SG_ 614 StatusConfigurationFBD_VL_FBDo_7 "contains maximum total ranging uptime over all ranging sessions (range: 0min ... 252min / step: 1min)";
CM_ SG_ 614 StatusConfigurationFBD_VL_FBDo_8 "contains RAN multiplier for resuming ranging sessions (range: 1 ... 255 / step: 1)";
CM_ SG_ 614 StatusConfigurationFBD_VL_FBDo_9 "contains activity state of analytics data collection from customer fleet about feature usage";
CM_ SG_ 614 StatusConfigurationFBD_VL_Device "contains device group setting";
CM_ SG_ 614 StatusConfigurationFBD_VL_IRKLis "contains IRK list ID";
CM_ SG_ 610 StatusConfigurationFBD_VM_UWBAnt "contains actual setting of UWB diversity mode";
CM_ SG_ 610 StatusConfigurationFBD_VM_UWBDut "contains actual setting of UWB duty cycle limit per sec (Range: 0 ... 126ms / step: 0,5ms)";
CM_ SG_ 610 StatusConfigurationFBD_VM_UWBD_2 "contains setting of maximal UWB duty cycle limit per hour (Range: 0 ... 25,2s / step: 0,1s)";
CM_ SG_ 610 StatusConfigurationFBD_VM_UWBD_3 "contains setting of maximal UWB duty cycle limit per second on average (Range: 0 ... 126ms / step: 0,5ms)";
CM_ SG_ 610 StatusConfigurationFBD_VM_FBDonl "contains setting of distance to the vehicle a FBD shall trigger CCU wake-up (range: 0m ... 25.2m / step: 0.1m)";
CM_ SG_ 610 StatusConfigurationFBD_VM_FBDo_2 "contains setting of ranging intent threshold in FBD-only mode (categorical: low, medium, high)";
CM_ SG_ 610 StatusConfigurationFBD_VM_FBDo_3 "contains setting of ranging session uptime (Range: 0 ... 252s / step: 1s)";
CM_ SG_ 610 StatusConfigurationFBD_VM_FBDo_4 "contains setting of ranging session uptime extension in seconds (range: 0s ... 252s / step: 1s)";
CM_ SG_ 610 StatusConfigurationFBD_VM_FBDo_5 "contains ranging session suspension timeout (invalid rangings) in seconds (range: 0s ... 252s / step: 1s)";
CM_ SG_ 610 StatusConfigurationFBD_VM_FBDo_6 "contains maximum ranging session uptime in seconds (range: 0s ... 252s / step: 1s)";
CM_ SG_ 610 StatusConfigurationFBD_VM_FBDo_7 "contains maximum total ranging uptime over all ranging sessions (range: 0min ... 252min / step: 1min)";
CM_ SG_ 610 StatusConfigurationFBD_VM_FBDo_8 "contains RAN multiplier for resuming ranging sessions (range: 1 ... 255 / step: 1)";
CM_ SG_ 610 StatusConfigurationFBD_VM_FBDo_9 "contains activity state of analytics data collection from customer fleet about feature usage";
CM_ SG_ 610 StatusConfigurationFBD_VM_Device "contains device group setting";
CM_ SG_ 610 StatusConfigurationFBD_VM_IRKLis "contains IRK list ID";
CM_ SG_ 615 StatusConfigurationFBD_VR_UWBAnt "contains actual setting of UWB diversity mode";
CM_ SG_ 615 StatusConfigurationFBD_VR_UWBDut "contains actual setting of UWB duty cycle limit per sec (Range: 0 ... 126ms / step: 0,5ms)";
CM_ SG_ 615 StatusConfigurationFBD_VR_UWBD_2 "contains setting of maximal UWB duty cycle limit per hour (Range: 0 ... 25,2s / step: 0,1s)";
CM_ SG_ 615 StatusConfigurationFBD_VR_UWBD_3 "contains setting of maximal UWB duty cycle limit per second on average (Range: 0 ... 126ms / step: 0,5ms)";
CM_ SG_ 615 StatusConfigurationFBD_VR_FBDonl "contains setting of distance to the vehicle a FBD shall trigger CCU wake-up (range: 0m ... 25.2m / step: 0.1m)";
CM_ SG_ 615 StatusConfigurationFBD_VR_FBDo_2 "contains setting of ranging intent threshold in FBD-only mode (categorical: low, medium, high)";
CM_ SG_ 615 StatusConfigurationFBD_VR_FBDo_3 "contains setting of ranging session uptime (Range: 0 ... 252s / step: 1s)";
CM_ SG_ 615 StatusConfigurationFBD_VR_FBDo_4 "contains setting of ranging session uptime extension in seconds (range: 0s ... 252s / step: 1s)";
CM_ SG_ 615 StatusConfigurationFBD_VR_FBDo_5 "contains ranging session suspension timeout (invalid rangings) in seconds (range: 0s ... 252s / step: 1s)";
CM_ SG_ 615 StatusConfigurationFBD_VR_FBDo_6 "contains maximum ranging session uptime in seconds (range: 0s ... 252s / step: 1s)";
CM_ SG_ 615 StatusConfigurationFBD_VR_FBDo_7 "contains maximum total ranging uptime over all ranging sessions (range: 0min ... 252min / step: 1min)";
CM_ SG_ 615 StatusConfigurationFBD_VR_FBDo_8 "contains RAN multiplier for resuming ranging sessions (range: 1 ... 255 / step: 1)";
CM_ SG_ 615 StatusConfigurationFBD_VR_FBDo_9 "contains activity state of analytics data collection from customer fleet about feature usage";
CM_ SG_ 615 StatusConfigurationFBD_VR_Device "contains device group setting";
CM_ SG_ 615 StatusConfigurationFBD_VR_IRKLis "contains IRK list ID";
CM_ SG_ 636 StatusCoordinatesFBD_HL_BodyFron "CoordinatesFBD6 (Range: -250cm ... 770cm / step: 1cm)";
CM_ SG_ 636 StatusCoordinatesFBD_HL_BodyFr_2 "CoordinatesFBD6 (Range: -250cm ... 770cm / step: 1cm)";
CM_ SG_ 636 StatusCoordinatesFBD_HL_BodyRear "CoordinatesFBD6 (Range: -250cm ... 770cm / step: 1cm)";
CM_ SG_ 636 StatusCoordinatesFBD_HL_BodyRe_2 "CoordinatesFBD6 (Range: -250cm ... 770cm / step: 1cm)";
CM_ SG_ 636 StatusCoordinatesFBD_HL_X "CoordinatesFBD6 (Range: -250cm ... 770cm / step: 1cm)";
CM_ SG_ 636 StatusCoordinatesFBD_HL_Y "CoordinatesFBD6 (Range: -250cm ... 770cm / step: 1cm)";
CM_ SG_ 636 StatusCoordinatesFBD_HL_Z "CoordinatesFBD6 (Range: -250cm ... 770cm / step: 1cm)";
CM_ SG_ 636 StatusCoordinatesFBD_HL_azimuth "AzimuthFB6 (Range: -180° ... 180° / step: 1°)";
CM_ SG_ 636 StatusCoordinatesFBD_HL_elevatio "ElevationFBD6 (Range: -100 ... 100° / step: 1°)";
CM_ SG_ 636 StatusCoordinatesFBD_HL_InvalidC "This signal is used to send an error message from the FBD to the CCU if the corresponding FBD has detected an invalid coordinate configuration (e.g., coordinate configuration or vehicle boundary missing).";
CM_ SG_ 631 StatusCoordinatesFBD_HM_BodyFron "CoordinatesFBD6 (Range: -250cm ... 770cm / step: 1cm)";
CM_ SG_ 631 StatusCoordinatesFBD_HM_BodyFr_2 "CoordinatesFBD6 (Range: -250cm ... 770cm / step: 1cm)";
CM_ SG_ 631 StatusCoordinatesFBD_HM_BodyRear "CoordinatesFBD6 (Range: -250cm ... 770cm / step: 1cm)";
CM_ SG_ 631 StatusCoordinatesFBD_HM_BodyRe_2 "CoordinatesFBD6 (Range: -250cm ... 770cm / step: 1cm)";
CM_ SG_ 631 StatusCoordinatesFBD_HM_X "CoordinatesFBD6 (Range: -250cm ... 770cm / step: 1cm)";
CM_ SG_ 631 StatusCoordinatesFBD_HM_Y "CoordinatesFBD6 (Range: -250cm ... 770cm / step: 1cm)";
CM_ SG_ 631 StatusCoordinatesFBD_HM_Z "CoordinatesFBD6 (Range: -250cm ... 770cm / step: 1cm)";
CM_ SG_ 631 StatusCoordinatesFBD_HM_azimuth "AzimuthFB6 (Range: -180° ... 180° / step: 1°)";
CM_ SG_ 631 StatusCoordinatesFBD_HM_elevatio "ElevationFBD6 (Range: -100 ... 100° / step: 1°)";
CM_ SG_ 631 StatusCoordinatesFBD_HM_InvalidC "This signal is used to send an error message from the FBD to the CCU if the corresponding FBD has detected an invalid coordinate configuration (e.g., coordinate configuration or vehicle boundary missing).";
CM_ SG_ 637 StatusCoordinatesFBD_HR_BodyFron "CoordinatesFBD6 (Range: -250cm ... 770cm / step: 1cm)";
CM_ SG_ 637 StatusCoordinatesFBD_HR_BodyFr_2 "CoordinatesFBD6 (Range: -250cm ... 770cm / step: 1cm)";
CM_ SG_ 637 StatusCoordinatesFBD_HR_BodyRear "CoordinatesFBD6 (Range: -250cm ... 770cm / step: 1cm)";
CM_ SG_ 637 StatusCoordinatesFBD_HR_BodyRe_2 "CoordinatesFBD6 (Range: -250cm ... 770cm / step: 1cm)";
CM_ SG_ 637 StatusCoordinatesFBD_HR_X "CoordinatesFBD6 (Range: -250cm ... 770cm / step: 1cm)";
CM_ SG_ 637 StatusCoordinatesFBD_HR_Y "CoordinatesFBD6 (Range: -250cm ... 770cm / step: 1cm)";
CM_ SG_ 637 StatusCoordinatesFBD_HR_Z "CoordinatesFBD6 (Range: -250cm ... 770cm / step: 1cm)";
CM_ SG_ 637 StatusCoordinatesFBD_HR_azimuth "AzimuthFB6 (Range: -180° ... 180° / step: 1°)";
CM_ SG_ 637 StatusCoordinatesFBD_HR_elevatio "ElevationFBD6 (Range: -100 ... 100° / step: 1°)";
CM_ SG_ 637 StatusCoordinatesFBD_HR_InvalidC "This signal is used to send an error message from the FBD to the CCU if the corresponding FBD has detected an invalid coordinate configuration (e.g., coordinate configuration or vehicle boundary missing).";
CM_ SG_ 632 StatusCoordinatesFBD_Miko_BodyFr "CoordinatesFBD6 (Range: -250cm ... 770cm / step: 1cm)";
CM_ SG_ 632 StatusCoordinatesFBD_Miko_Body_2 "CoordinatesFBD6 (Range: -250cm ... 770cm / step: 1cm)";
CM_ SG_ 632 StatusCoordinatesFBD_Miko_BodyRe "CoordinatesFBD6 (Range: -250cm ... 770cm / step: 1cm)";
CM_ SG_ 632 StatusCoordinatesFBD_Miko_Body_3 "CoordinatesFBD6 (Range: -250cm ... 770cm / step: 1cm)";
CM_ SG_ 632 StatusCoordinatesFBD_Miko_X "CoordinatesFBD6 (Range: -250cm ... 770cm / step: 1cm)";
CM_ SG_ 632 StatusCoordinatesFBD_Miko_Y "CoordinatesFBD6 (Range: -250cm ... 770cm / step: 1cm)";
CM_ SG_ 632 StatusCoordinatesFBD_Miko_Z "CoordinatesFBD6 (Range: -250cm ... 770cm / step: 1cm)";
CM_ SG_ 632 StatusCoordinatesFBD_Miko_azimut "AzimuthFB6 (Range: -180° ... 180° / step: 1°)";
CM_ SG_ 632 StatusCoordinatesFBD_Miko_elevat "ElevationFBD6 (Range: -100 ... 100° / step: 1°)";
CM_ SG_ 632 StatusCoordinatesFBD_Miko_Invali "This signal is used to send an error message from the FBD to the CCU if the corresponding FBD has detected an invalid coordinate configuration (e.g., coordinate configuration or vehicle boundary missing).";
CM_ SG_ 692 StatusCoordinatesFBD_MM_BodyFron "CoordinatesFBD6 (Range: -250cm ... 770cm / step: 1cm)";
CM_ SG_ 692 StatusCoordinatesFBD_MM_BodyFr_2 "CoordinatesFBD6 (Range: -250cm ... 770cm / step: 1cm)";
CM_ SG_ 692 StatusCoordinatesFBD_MM_BodyRear "CoordinatesFBD6 (Range: -250cm ... 770cm / step: 1cm)";
CM_ SG_ 692 StatusCoordinatesFBD_MM_BodyRe_2 "CoordinatesFBD6 (Range: -250cm ... 770cm / step: 1cm)";
CM_ SG_ 692 StatusCoordinatesFBD_MM_X "CoordinatesFBD6 (Range: -250cm ... 770cm / step: 1cm)";
CM_ SG_ 692 StatusCoordinatesFBD_MM_Y "CoordinatesFBD6 (Range: -250cm ... 770cm / step: 1cm)";
CM_ SG_ 692 StatusCoordinatesFBD_MM_Z "CoordinatesFBD6 (Range: -250cm ... 770cm / step: 1cm)";
CM_ SG_ 692 StatusCoordinatesFBD_MM_azimuth "AzimuthFB6 (Range: -180° ... 180° / step: 1°)";
CM_ SG_ 692 StatusCoordinatesFBD_MM_elevatio "ElevationFBD6 (Range: -100 ... 100° / step: 1°)";
CM_ SG_ 692 StatusCoordinatesFBD_MM_InvalidC "This signal is used to send an error message from the FBD to the CCU if the corresponding FBD has detected an invalid coordinate configuration (e.g., coordinate configuration or vehicle boundary missing).";
CM_ SG_ 633 StatusCoordinatesFBD_Trunk_BodyF "CoordinatesFBD6 (Range: -250cm ... 770cm / step: 1cm)";
CM_ SG_ 633 StatusCoordinatesFBD_Trunk_Bod_2 "CoordinatesFBD6 (Range: -250cm ... 770cm / step: 1cm)";
CM_ SG_ 633 StatusCoordinatesFBD_Trunk_BodyR "CoordinatesFBD6 (Range: -250cm ... 770cm / step: 1cm)";
CM_ SG_ 633 StatusCoordinatesFBD_Trunk_Bod_3 "CoordinatesFBD6 (Range: -250cm ... 770cm / step: 1cm)";
CM_ SG_ 633 StatusCoordinatesFBD_Trunk_X "CoordinatesFBD6 (Range: -250cm ... 770cm / step: 1cm)";
CM_ SG_ 633 StatusCoordinatesFBD_Trunk_Y "CoordinatesFBD6 (Range: -250cm ... 770cm / step: 1cm)";
CM_ SG_ 633 StatusCoordinatesFBD_Trunk_Z "CoordinatesFBD6 (Range: -250cm ... 770cm / step: 1cm)";
CM_ SG_ 633 StatusCoordinatesFBD_Trunk_azimu "AzimuthFB6 (Range: -180° ... 180° / step: 1°)";
CM_ SG_ 633 StatusCoordinatesFBD_Trunk_eleva "ElevationFBD6 (Range: -100 ... 100° / step: 1°)";
CM_ SG_ 633 StatusCoordinatesFBD_Trunk_Inval "This signal is used to send an error message from the FBD to the CCU if the corresponding FBD has detected an invalid coordinate configuration (e.g., coordinate configuration or vehicle boundary missing).";
CM_ SG_ 634 StatusCoordinatesFBD_VL_BodyFron "CoordinatesFBD6 (Range: -250cm ... 770cm / step: 1cm)";
CM_ SG_ 634 StatusCoordinatesFBD_VL_BodyFr_2 "CoordinatesFBD6 (Range: -250cm ... 770cm / step: 1cm)";
CM_ SG_ 634 StatusCoordinatesFBD_VL_BodyRear "CoordinatesFBD6 (Range: -250cm ... 770cm / step: 1cm)";
CM_ SG_ 634 StatusCoordinatesFBD_VL_BodyRe_2 "CoordinatesFBD6 (Range: -250cm ... 770cm / step: 1cm)";
CM_ SG_ 634 StatusCoordinatesFBD_VL_X "CoordinatesFBD6 (Range: -250cm ... 770cm / step: 1cm)";
CM_ SG_ 634 StatusCoordinatesFBD_VL_Y "CoordinatesFBD6 (Range: -250cm ... 770cm / step: 1cm)";
CM_ SG_ 634 StatusCoordinatesFBD_VL_Z "CoordinatesFBD6 (Range: -250cm ... 770cm / step: 1cm)";
CM_ SG_ 634 StatusCoordinatesFBD_VL_azimuth "AzimuthFB6 (Range: -180° ... 180° / step: 1°)";
CM_ SG_ 634 StatusCoordinatesFBD_VL_elevatio "ElevationFBD6 (Range: -100 ... 100° / step: 1°)";
CM_ SG_ 634 StatusCoordinatesFBD_VL_InvalidC "This signal is used to send an error message from the FBD to the CCU if the corresponding FBD has detected an invalid coordinate configuration (e.g., coordinate configuration or vehicle boundary missing).";
CM_ SG_ 630 StatusCoordinatesFBD_VM_BodyFron "CoordinatesFBD6 (Range: -250cm ... 770cm / step: 1cm)";
CM_ SG_ 630 StatusCoordinatesFBD_VM_BodyFr_2 "CoordinatesFBD6 (Range: -250cm ... 770cm / step: 1cm)";
CM_ SG_ 630 StatusCoordinatesFBD_VM_BodyRear "CoordinatesFBD6 (Range: -250cm ... 770cm / step: 1cm)";
CM_ SG_ 630 StatusCoordinatesFBD_VM_BodyRe_2 "CoordinatesFBD6 (Range: -250cm ... 770cm / step: 1cm)";
CM_ SG_ 630 StatusCoordinatesFBD_VM_X "CoordinatesFBD6 (Range: -250cm ... 770cm / step: 1cm)";
CM_ SG_ 630 StatusCoordinatesFBD_VM_Y "CoordinatesFBD6 (Range: -250cm ... 770cm / step: 1cm)";
CM_ SG_ 630 StatusCoordinatesFBD_VM_Z "CoordinatesFBD6 (Range: -250cm ... 770cm / step: 1cm)";
CM_ SG_ 630 StatusCoordinatesFBD_VM_azimuth "AzimuthFB6 (Range: -180° ... 180° / step: 1°)";
CM_ SG_ 630 StatusCoordinatesFBD_VM_elevatio "ElevationFBD6 (Range: -100 ... 100° / step: 1°)";
CM_ SG_ 630 StatusCoordinatesFBD_VM_InvalidC "This signal is used to send an error message from the FBD to the CCU if the corresponding FBD has detected an invalid coordinate configuration (e.g., coordinate configuration or vehicle boundary missing).";
CM_ SG_ 635 StatusCoordinatesFBD_VR_BodyFron "CoordinatesFBD6 (Range: -250cm ... 770cm / step: 1cm)";
CM_ SG_ 635 StatusCoordinatesFBD_VR_BodyFr_2 "CoordinatesFBD6 (Range: -250cm ... 770cm / step: 1cm)";
CM_ SG_ 635 StatusCoordinatesFBD_VR_BodyRear "CoordinatesFBD6 (Range: -250cm ... 770cm / step: 1cm)";
CM_ SG_ 635 StatusCoordinatesFBD_VR_BodyRe_2 "CoordinatesFBD6 (Range: -250cm ... 770cm / step: 1cm)";
CM_ SG_ 635 StatusCoordinatesFBD_VR_X "CoordinatesFBD6 (Range: -250cm ... 770cm / step: 1cm)";
CM_ SG_ 635 StatusCoordinatesFBD_VR_Y "CoordinatesFBD6 (Range: -250cm ... 770cm / step: 1cm)";
CM_ SG_ 635 StatusCoordinatesFBD_VR_Z "CoordinatesFBD6 (Range: -250cm ... 770cm / step: 1cm)";
CM_ SG_ 635 StatusCoordinatesFBD_VR_azimuth "AzimuthFB6 (Range: -180° ... 180° / step: 1°)";
CM_ SG_ 635 StatusCoordinatesFBD_VR_elevatio "ElevationFBD6 (Range: -100 ... 100° / step: 1°)";
CM_ SG_ 635 StatusCoordinatesFBD_VR_InvalidC "This signal is used to send an error message from the FBD to the CCU if the corresponding FBD has detected an invalid coordinate configuration (e.g., coordinate configuration or vehicle boundary missing).";
CM_ SG_ 336 StatusCPDData1FBD_HL_MsgCounter "contains counter";
CM_ SG_ 336 StatusCPDData1FBD_HL_LinkID "contains link ID";
CM_ SG_ 336 StatusCPDData1FBD_HL_AGCValue "contains AGC value";
CM_ SG_ 336 StatusCPDData1FBD_HL_Channel "contains channel";
CM_ SG_ 336 StatusCPDData1FBD_HL_CIRData00 "contains CPD data to tap 1 - real part MSB";
CM_ SG_ 336 StatusCPDData1FBD_HL_CIRData01 "contains CPD data to tap 1 - real part LSB";
CM_ SG_ 336 StatusCPDData1FBD_HL_CIRData02 "contains CPD data to tap 1 - imaginary part MSB";
CM_ SG_ 336 StatusCPDData1FBD_HL_CIRData03 "contains CPD data to tap 1 - imaginary part LSB";
CM_ SG_ 336 StatusCPDData1FBD_HL_CIRData04 "contains CPD data to tap 2 - real part MSB";
CM_ SG_ 336 StatusCPDData1FBD_HL_CIRData05 "contains CPD data to tap 2 - real part LSB";
CM_ SG_ 336 StatusCPDData1FBD_HL_CIRData06 "contains CPD data to tap 2 - imaginary part MSB";
CM_ SG_ 336 StatusCPDData1FBD_HL_CIRData07 "contains CPD data to tap 2 - imaginary part LSB";
CM_ SG_ 336 StatusCPDData1FBD_HL_CIRData08 "contains CPD data to tap 3 - real part MSB";
CM_ SG_ 336 StatusCPDData1FBD_HL_CIRData09 "contains CPD data to tap 3 - real part LSB";
CM_ SG_ 336 StatusCPDData1FBD_HL_CIRData10 "contains CPD data to tap 3 - imaginary part MSB";
CM_ SG_ 336 StatusCPDData1FBD_HL_CIRData11 "contains CPD data to tap 3 - imaginary part LSB";
CM_ SG_ 336 StatusCPDData1FBD_HL_CIRData12 "contains CPD data to tap 4 - real part MSB";
CM_ SG_ 336 StatusCPDData1FBD_HL_CIRData13 "contains CPD data to tap 4 - real part LSB";
CM_ SG_ 336 StatusCPDData1FBD_HL_CIRData14 "contains CPD data to tap 4 - imaginary part MSB";
CM_ SG_ 336 StatusCPDData1FBD_HL_CIRData15 "contains CPD data to tap 4 - imaginary part LSB";
CM_ SG_ 336 StatusCPDData1FBD_HL_CIRData16 "contains CPD data to tap 5 - real part MSB";
CM_ SG_ 336 StatusCPDData1FBD_HL_CIRData17 "contains CPD data to tap 5 - real part LSB";
CM_ SG_ 336 StatusCPDData1FBD_HL_CIRData18 "contains CPD data to tap 5 - imaginary part MSB";
CM_ SG_ 336 StatusCPDData1FBD_HL_CIRData19 "contains CPD data to tap 5 - imaginary part LSB";
CM_ SG_ 336 StatusCPDData1FBD_HL_CIRData20 "contains CPD data to tap 6 - real part MSB";
CM_ SG_ 336 StatusCPDData1FBD_HL_CIRData21 "contains CPD data to tap 6 - real part LSB";
CM_ SG_ 336 StatusCPDData1FBD_HL_CIRData22 "contains CPD data to tap 6 - imaginary part MSB";
CM_ SG_ 336 StatusCPDData1FBD_HL_CIRData23 "contains CPD data to tap 6 - imaginary part LSB";
CM_ SG_ 336 StatusCPDData1FBD_HL_CIRData24 "contains CPD data to tap 7 - real part MSB";
CM_ SG_ 336 StatusCPDData1FBD_HL_CIRData25 "contains CPD data to tap 7 - real part LSB";
CM_ SG_ 336 StatusCPDData1FBD_HL_CIRData26 "contains CPD data to tap 7 - imaginary part MSB";
CM_ SG_ 336 StatusCPDData1FBD_HL_CIRData27 "contains CPD data to tap 7 - imaginary part LSB";
CM_ SG_ 336 StatusCPDData1FBD_HL_CIRData28 "contains CPD data to tap 8 - real part MSB";
CM_ SG_ 336 StatusCPDData1FBD_HL_CIRData29 "contains CPD data to tap 8 - real part LSB";
CM_ SG_ 336 StatusCPDData1FBD_HL_CIRData30 "contains CPD data to tap 8 - imaginary part MSB";
CM_ SG_ 336 StatusCPDData1FBD_HL_CIRData31 "contains CPD data to tap 8 - imaginary part LSB";
CM_ SG_ 336 StatusCPDData1FBD_HL_CIRData32 "contains CPD data to tap 9 - real part MSB";
CM_ SG_ 336 StatusCPDData1FBD_HL_CIRData33 "contains CPD data to tap 9 - real part LSB";
CM_ SG_ 336 StatusCPDData1FBD_HL_CIRData34 "contains CPD data to tap 9 - imaginary part MSB";
CM_ SG_ 336 StatusCPDData1FBD_HL_CIRData35 "contains CPD data to tap 9 - imaginary part LSB";
CM_ SG_ 336 StatusCPDData1FBD_HL_CIRData36 "contains CPD data to tap 10 - real part MSB";
CM_ SG_ 336 StatusCPDData1FBD_HL_CIRData37 "contains CPD data to tap 10 - real part LSB";
CM_ SG_ 336 StatusCPDData1FBD_HL_CIRData38 "contains CPD data to tap 10 - imaginary part MSB";
CM_ SG_ 336 StatusCPDData1FBD_HL_CIRData39 "contains CPD data to tap 10 - imaginary part LSB";
CM_ SG_ 336 StatusCPDData1FBD_HL_CIRData40 "contains CPD data to tap 11 - real part MSB";
CM_ SG_ 336 StatusCPDData1FBD_HL_CIRData41 "contains CPD data to tap 11 - real part LSB";
CM_ SG_ 336 StatusCPDData1FBD_HL_CIRData42 "contains CPD data to tap 11 - imaginary part MSB";
CM_ SG_ 336 StatusCPDData1FBD_HL_CIRData43 "contains CPD data to tap 11 - imaginary part LSB";
CM_ SG_ 336 StatusCPDData1FBD_HL_CIRData44 "contains CPD data to tap 12 - real part MSB";
CM_ SG_ 336 StatusCPDData1FBD_HL_CIRData45 "contains CPD data to tap 12 - real part LSB";
CM_ SG_ 336 StatusCPDData1FBD_HL_CIRData46 "contains CPD data to tap 12 - imaginary part MSB";
CM_ SG_ 336 StatusCPDData1FBD_HL_CIRData47 "contains CPD data to tap 12 - imaginary part LSB";
CM_ SG_ 336 StatusCPDData1FBD_HL_CIRData48 "contains CPD data to tap 13 - real part MSB";
CM_ SG_ 336 StatusCPDData1FBD_HL_CIRData49 "contains CPD data to tap 13 - real part LSB";
CM_ SG_ 336 StatusCPDData1FBD_HL_CIRData50 "contains CPD data to tap 13 - imaginary part MSB";
CM_ SG_ 336 StatusCPDData1FBD_HL_CIRData51 "contains CPD data to tap 13 - imaginary part LSB";
CM_ SG_ 336 StatusCPDData1FBD_HL_CIRData52 "contains CPD data to tap 14 - real part MSB";
CM_ SG_ 336 StatusCPDData1FBD_HL_CIRData53 "contains CPD data to tap 14 - real part LSB";
CM_ SG_ 336 StatusCPDData1FBD_HL_CIRData54 "contains CPD data to tap 14 - imaginary part MSB";
CM_ SG_ 336 StatusCPDData1FBD_HL_CIRData55 "contains CPD data to tap 14 - imaginary part LSB";
CM_ SG_ 336 StatusCPDData1FBD_HL_CIRData56 "contains CPD data to tap 15 - real part MSB";
CM_ SG_ 336 StatusCPDData1FBD_HL_CIRData57 "contains CPD data to tap 15 - real part LSB";
CM_ SG_ 336 StatusCPDData1FBD_HL_CIRData58 "contains CPD data to tap 15 - imaginary part MSB";
CM_ SG_ 336 StatusCPDData1FBD_HL_CIRData59 "contains CPD data to tap 15 - imaginary part LSB";
CM_ SG_ 331 StatusCPDData1FBD_HM_MsgCounter "contains counter";
CM_ SG_ 331 StatusCPDData1FBD_HM_LinkID "contains link ID";
CM_ SG_ 331 StatusCPDData1FBD_HM_AGCValue "contains AGC value";
CM_ SG_ 331 StatusCPDData1FBD_HM_Channel "contains channel";
CM_ SG_ 331 StatusCPDData1FBD_HM_CIRData00 "contains CPD data to tap 1 - real part MSB";
CM_ SG_ 331 StatusCPDData1FBD_HM_CIRData01 "contains CPD data to tap 1 - real part LSB";
CM_ SG_ 331 StatusCPDData1FBD_HM_CIRData02 "contains CPD data to tap 1 - imaginary part MSB";
CM_ SG_ 331 StatusCPDData1FBD_HM_CIRData03 "contains CPD data to tap 1 - imaginary part LSB";
CM_ SG_ 331 StatusCPDData1FBD_HM_CIRData04 "contains CPD data to tap 2 - real part MSB";
CM_ SG_ 331 StatusCPDData1FBD_HM_CIRData05 "contains CPD data to tap 2 - real part LSB";
CM_ SG_ 331 StatusCPDData1FBD_HM_CIRData06 "contains CPD data to tap 2 - imaginary part MSB";
CM_ SG_ 331 StatusCPDData1FBD_HM_CIRData07 "contains CPD data to tap 2 - imaginary part LSB";
CM_ SG_ 331 StatusCPDData1FBD_HM_CIRData08 "contains CPD data to tap 3 - real part MSB";
CM_ SG_ 331 StatusCPDData1FBD_HM_CIRData09 "contains CPD data to tap 3 - real part LSB";
CM_ SG_ 331 StatusCPDData1FBD_HM_CIRData10 "contains CPD data to tap 3 - imaginary part MSB";
CM_ SG_ 331 StatusCPDData1FBD_HM_CIRData11 "contains CPD data to tap 3 - imaginary part LSB";
CM_ SG_ 331 StatusCPDData1FBD_HM_CIRData12 "contains CPD data to tap 4 - real part MSB";
CM_ SG_ 331 StatusCPDData1FBD_HM_CIRData13 "contains CPD data to tap 4 - real part LSB";
CM_ SG_ 331 StatusCPDData1FBD_HM_CIRData14 "contains CPD data to tap 4 - imaginary part MSB";
CM_ SG_ 331 StatusCPDData1FBD_HM_CIRData15 "contains CPD data to tap 4 - imaginary part LSB";
CM_ SG_ 331 StatusCPDData1FBD_HM_CIRData16 "contains CPD data to tap 5 - real part MSB";
CM_ SG_ 331 StatusCPDData1FBD_HM_CIRData17 "contains CPD data to tap 5 - real part LSB";
CM_ SG_ 331 StatusCPDData1FBD_HM_CIRData18 "contains CPD data to tap 5 - imaginary part MSB";
CM_ SG_ 331 StatusCPDData1FBD_HM_CIRData19 "contains CPD data to tap 5 - imaginary part LSB";
CM_ SG_ 331 StatusCPDData1FBD_HM_CIRData20 "contains CPD data to tap 6 - real part MSB";
CM_ SG_ 331 StatusCPDData1FBD_HM_CIRData21 "contains CPD data to tap 6 - real part LSB";
CM_ SG_ 331 StatusCPDData1FBD_HM_CIRData22 "contains CPD data to tap 6 - imaginary part MSB";
CM_ SG_ 331 StatusCPDData1FBD_HM_CIRData23 "contains CPD data to tap 6 - imaginary part LSB";
CM_ SG_ 331 StatusCPDData1FBD_HM_CIRData24 "contains CPD data to tap 7 - real part MSB";
CM_ SG_ 331 StatusCPDData1FBD_HM_CIRData25 "contains CPD data to tap 7 - real part LSB";
CM_ SG_ 331 StatusCPDData1FBD_HM_CIRData26 "contains CPD data to tap 7 - imaginary part MSB";
CM_ SG_ 331 StatusCPDData1FBD_HM_CIRData27 "contains CPD data to tap 7 - imaginary part LSB";
CM_ SG_ 331 StatusCPDData1FBD_HM_CIRData28 "contains CPD data to tap 8 - real part MSB";
CM_ SG_ 331 StatusCPDData1FBD_HM_CIRData29 "contains CPD data to tap 8 - real part LSB";
CM_ SG_ 331 StatusCPDData1FBD_HM_CIRData30 "contains CPD data to tap 8 - imaginary part MSB";
CM_ SG_ 331 StatusCPDData1FBD_HM_CIRData31 "contains CPD data to tap 8 - imaginary part LSB";
CM_ SG_ 331 StatusCPDData1FBD_HM_CIRData32 "contains CPD data to tap 9 - real part MSB";
CM_ SG_ 331 StatusCPDData1FBD_HM_CIRData33 "contains CPD data to tap 9 - real part LSB";
CM_ SG_ 331 StatusCPDData1FBD_HM_CIRData34 "contains CPD data to tap 9 - imaginary part MSB";
CM_ SG_ 331 StatusCPDData1FBD_HM_CIRData35 "contains CPD data to tap 9 - imaginary part LSB";
CM_ SG_ 331 StatusCPDData1FBD_HM_CIRData36 "contains CPD data to tap 10 - real part MSB";
CM_ SG_ 331 StatusCPDData1FBD_HM_CIRData37 "contains CPD data to tap 10 - real part LSB";
CM_ SG_ 331 StatusCPDData1FBD_HM_CIRData38 "contains CPD data to tap 10 - imaginary part MSB";
CM_ SG_ 331 StatusCPDData1FBD_HM_CIRData39 "contains CPD data to tap 10 - imaginary part LSB";
CM_ SG_ 331 StatusCPDData1FBD_HM_CIRData40 "contains CPD data to tap 11 - real part MSB";
CM_ SG_ 331 StatusCPDData1FBD_HM_CIRData41 "contains CPD data to tap 11 - real part LSB";
CM_ SG_ 331 StatusCPDData1FBD_HM_CIRData42 "contains CPD data to tap 11 - imaginary part MSB";
CM_ SG_ 331 StatusCPDData1FBD_HM_CIRData43 "contains CPD data to tap 11 - imaginary part LSB";
CM_ SG_ 331 StatusCPDData1FBD_HM_CIRData44 "contains CPD data to tap 12 - real part MSB";
CM_ SG_ 331 StatusCPDData1FBD_HM_CIRData45 "contains CPD data to tap 12 - real part LSB";
CM_ SG_ 331 StatusCPDData1FBD_HM_CIRData46 "contains CPD data to tap 12 - imaginary part MSB";
CM_ SG_ 331 StatusCPDData1FBD_HM_CIRData47 "contains CPD data to tap 12 - imaginary part LSB";
CM_ SG_ 331 StatusCPDData1FBD_HM_CIRData48 "contains CPD data to tap 13 - real part MSB";
CM_ SG_ 331 StatusCPDData1FBD_HM_CIRData49 "contains CPD data to tap 13 - real part LSB";
CM_ SG_ 331 StatusCPDData1FBD_HM_CIRData50 "contains CPD data to tap 13 - imaginary part MSB";
CM_ SG_ 331 StatusCPDData1FBD_HM_CIRData51 "contains CPD data to tap 13 - imaginary part LSB";
CM_ SG_ 331 StatusCPDData1FBD_HM_CIRData52 "contains CPD data to tap 14 - real part MSB";
CM_ SG_ 331 StatusCPDData1FBD_HM_CIRData53 "contains CPD data to tap 14 - real part LSB";
CM_ SG_ 331 StatusCPDData1FBD_HM_CIRData54 "contains CPD data to tap 14 - imaginary part MSB";
CM_ SG_ 331 StatusCPDData1FBD_HM_CIRData55 "contains CPD data to tap 14 - imaginary part LSB";
CM_ SG_ 331 StatusCPDData1FBD_HM_CIRData56 "contains CPD data to tap 15 - real part MSB";
CM_ SG_ 331 StatusCPDData1FBD_HM_CIRData57 "contains CPD data to tap 15 - real part LSB";
CM_ SG_ 331 StatusCPDData1FBD_HM_CIRData58 "contains CPD data to tap 15 - imaginary part MSB";
CM_ SG_ 331 StatusCPDData1FBD_HM_CIRData59 "contains CPD data to tap 15 - imaginary part LSB";
CM_ SG_ 337 StatusCPDData1FBD_HR_MsgCounter "contains counter";
CM_ SG_ 337 StatusCPDData1FBD_HR_LinkID "contains link ID";
CM_ SG_ 337 StatusCPDData1FBD_HR_AGCValue "contains AGC value";
CM_ SG_ 337 StatusCPDData1FBD_HR_Channel "contains channel";
CM_ SG_ 337 StatusCPDData1FBD_HR_CIRData00 "contains CPD data to tap 1 - real part MSB";
CM_ SG_ 337 StatusCPDData1FBD_HR_CIRData01 "contains CPD data to tap 1 - real part LSB";
CM_ SG_ 337 StatusCPDData1FBD_HR_CIRData02 "contains CPD data to tap 1 - imaginary part MSB";
CM_ SG_ 337 StatusCPDData1FBD_HR_CIRData03 "contains CPD data to tap 1 - imaginary part LSB";
CM_ SG_ 337 StatusCPDData1FBD_HR_CIRData04 "contains CPD data to tap 2 - real part MSB";
CM_ SG_ 337 StatusCPDData1FBD_HR_CIRData05 "contains CPD data to tap 2 - real part LSB";
CM_ SG_ 337 StatusCPDData1FBD_HR_CIRData06 "contains CPD data to tap 2 - imaginary part MSB";
CM_ SG_ 337 StatusCPDData1FBD_HR_CIRData07 "contains CPD data to tap 2 - imaginary part LSB";
CM_ SG_ 337 StatusCPDData1FBD_HR_CIRData08 "contains CPD data to tap 3 - real part MSB";
CM_ SG_ 337 StatusCPDData1FBD_HR_CIRData09 "contains CPD data to tap 3 - real part LSB";
CM_ SG_ 337 StatusCPDData1FBD_HR_CIRData10 "contains CPD data to tap 3 - imaginary part MSB";
CM_ SG_ 337 StatusCPDData1FBD_HR_CIRData11 "contains CPD data to tap 3 - imaginary part LSB";
CM_ SG_ 337 StatusCPDData1FBD_HR_CIRData12 "contains CPD data to tap 4 - real part MSB";
CM_ SG_ 337 StatusCPDData1FBD_HR_CIRData13 "contains CPD data to tap 4 - real part LSB";
CM_ SG_ 337 StatusCPDData1FBD_HR_CIRData14 "contains CPD data to tap 4 - imaginary part MSB";
CM_ SG_ 337 StatusCPDData1FBD_HR_CIRData15 "contains CPD data to tap 4 - imaginary part LSB";
CM_ SG_ 337 StatusCPDData1FBD_HR_CIRData16 "contains CPD data to tap 5 - real part MSB";
CM_ SG_ 337 StatusCPDData1FBD_HR_CIRData17 "contains CPD data to tap 5 - real part LSB";
CM_ SG_ 337 StatusCPDData1FBD_HR_CIRData18 "contains CPD data to tap 5 - imaginary part MSB";
CM_ SG_ 337 StatusCPDData1FBD_HR_CIRData19 "contains CPD data to tap 5 - imaginary part LSB";
CM_ SG_ 337 StatusCPDData1FBD_HR_CIRData20 "contains CPD data to tap 6 - real part MSB";
CM_ SG_ 337 StatusCPDData1FBD_HR_CIRData21 "contains CPD data to tap 6 - real part LSB";
CM_ SG_ 337 StatusCPDData1FBD_HR_CIRData22 "contains CPD data to tap 6 - imaginary part MSB";
CM_ SG_ 337 StatusCPDData1FBD_HR_CIRData23 "contains CPD data to tap 6 - imaginary part LSB";
CM_ SG_ 337 StatusCPDData1FBD_HR_CIRData24 "contains CPD data to tap 7 - real part MSB";
CM_ SG_ 337 StatusCPDData1FBD_HR_CIRData25 "contains CPD data to tap 7 - real part LSB";
CM_ SG_ 337 StatusCPDData1FBD_HR_CIRData26 "contains CPD data to tap 7 - imaginary part MSB";
CM_ SG_ 337 StatusCPDData1FBD_HR_CIRData27 "contains CPD data to tap 7 - imaginary part LSB";
CM_ SG_ 337 StatusCPDData1FBD_HR_CIRData28 "contains CPD data to tap 8 - real part MSB";
CM_ SG_ 337 StatusCPDData1FBD_HR_CIRData29 "contains CPD data to tap 8 - real part LSB";
CM_ SG_ 337 StatusCPDData1FBD_HR_CIRData30 "contains CPD data to tap 8 - imaginary part MSB";
CM_ SG_ 337 StatusCPDData1FBD_HR_CIRData31 "contains CPD data to tap 8 - imaginary part LSB";
CM_ SG_ 337 StatusCPDData1FBD_HR_CIRData32 "contains CPD data to tap 9 - real part MSB";
CM_ SG_ 337 StatusCPDData1FBD_HR_CIRData33 "contains CPD data to tap 9 - real part LSB";
CM_ SG_ 337 StatusCPDData1FBD_HR_CIRData34 "contains CPD data to tap 9 - imaginary part MSB";
CM_ SG_ 337 StatusCPDData1FBD_HR_CIRData35 "contains CPD data to tap 9 - imaginary part LSB";
CM_ SG_ 337 StatusCPDData1FBD_HR_CIRData36 "contains CPD data to tap 10 - real part MSB";
CM_ SG_ 337 StatusCPDData1FBD_HR_CIRData37 "contains CPD data to tap 10 - real part LSB";
CM_ SG_ 337 StatusCPDData1FBD_HR_CIRData38 "contains CPD data to tap 10 - imaginary part MSB";
CM_ SG_ 337 StatusCPDData1FBD_HR_CIRData39 "contains CPD data to tap 10 - imaginary part LSB";
CM_ SG_ 337 StatusCPDData1FBD_HR_CIRData40 "contains CPD data to tap 11 - real part MSB";
CM_ SG_ 337 StatusCPDData1FBD_HR_CIRData41 "contains CPD data to tap 11 - real part LSB";
CM_ SG_ 337 StatusCPDData1FBD_HR_CIRData42 "contains CPD data to tap 11 - imaginary part MSB";
CM_ SG_ 337 StatusCPDData1FBD_HR_CIRData43 "contains CPD data to tap 11 - imaginary part LSB";
CM_ SG_ 337 StatusCPDData1FBD_HR_CIRData44 "contains CPD data to tap 12 - real part MSB";
CM_ SG_ 337 StatusCPDData1FBD_HR_CIRData45 "contains CPD data to tap 12 - real part LSB";
CM_ SG_ 337 StatusCPDData1FBD_HR_CIRData46 "contains CPD data to tap 12 - imaginary part MSB";
CM_ SG_ 337 StatusCPDData1FBD_HR_CIRData47 "contains CPD data to tap 12 - imaginary part LSB";
CM_ SG_ 337 StatusCPDData1FBD_HR_CIRData48 "contains CPD data to tap 13 - real part MSB";
CM_ SG_ 337 StatusCPDData1FBD_HR_CIRData49 "contains CPD data to tap 13 - real part LSB";
CM_ SG_ 337 StatusCPDData1FBD_HR_CIRData50 "contains CPD data to tap 13 - imaginary part MSB";
CM_ SG_ 337 StatusCPDData1FBD_HR_CIRData51 "contains CPD data to tap 13 - imaginary part LSB";
CM_ SG_ 337 StatusCPDData1FBD_HR_CIRData52 "contains CPD data to tap 14 - real part MSB";
CM_ SG_ 337 StatusCPDData1FBD_HR_CIRData53 "contains CPD data to tap 14 - real part LSB";
CM_ SG_ 337 StatusCPDData1FBD_HR_CIRData54 "contains CPD data to tap 14 - imaginary part MSB";
CM_ SG_ 337 StatusCPDData1FBD_HR_CIRData55 "contains CPD data to tap 14 - imaginary part LSB";
CM_ SG_ 337 StatusCPDData1FBD_HR_CIRData56 "contains CPD data to tap 15 - real part MSB";
CM_ SG_ 337 StatusCPDData1FBD_HR_CIRData57 "contains CPD data to tap 15 - real part LSB";
CM_ SG_ 337 StatusCPDData1FBD_HR_CIRData58 "contains CPD data to tap 15 - imaginary part MSB";
CM_ SG_ 337 StatusCPDData1FBD_HR_CIRData59 "contains CPD data to tap 15 - imaginary part LSB";

BA_DEF_ BO_ "VFrameFormat" ENUM "StandardCAN","ExtendedCAN","reserved","J1939PG","reserved","reserved","reserved","reserved","reserved","reserved","reserved","reserved","reserved","reserved","StandardCAN_FD","ExtendedCAN_FD";
BA_DEF_DEF_ "VFrameFormat" "StandardCAN";
BA_ "VFrameFormat" BO_ 651 14;
BA_ "VFrameFormat" BO_ 657 14;
BA_ "VFrameFormat" BO_ 652 14;
BA_ "VFrameFormat" BO_ 660 14;
BA_ "VFrameFormat" BO_ 653 14;
BA_ "VFrameFormat" BO_ 654 14;
BA_ "VFrameFormat" BO_ 650 14;
BA_ "VFrameFormat" BO_ 655 14;
BA_ "VFrameFormat" BO_ 216 14;
BA_ "VFrameFormat" BO_ 211 14;
BA_ "VFrameFormat" BO_ 217 14;
BA_ "VFrameFormat" BO_ 212 14;
BA_ "VFrameFormat" BO_ 240 14;
BA_ "VFrameFormat" BO_ 213 14;
BA_ "VFrameFormat" BO_ 214 14;
BA_ "VFrameFormat" BO_ 210 14;
BA_ "VFrameFormat" BO_ 215 14;
BA_ "VFrameFormat" BO_ 396 14;
BA_ "VFrameFormat" BO_ 391 14;
BA_ "VFrameFormat" BO_ 397 14;
BA_ "VFrameFormat" BO_ 392 14;
BA_ "VFrameFormat" BO_ 823 14;
BA_ "VFrameFormat" BO_ 393 14;
BA_ "VFrameFormat" BO_ 394 14;
BA_ "VFrameFormat" BO_ 390 14;
BA_ "VFrameFormat" BO_ 395 14;
BA_ "VFrameFormat" BO_ 616 14;
BA_ "VFrameFormat" BO_ 611 14;
BA_ "VFrameFormat" BO_ 617 14;
BA_ "VFrameFormat" BO_ 612 14;
BA_ "VFrameFormat" BO_ 691 14;
BA_ "VFrameFormat" BO_ 613 14;
BA_ "VFrameFormat" BO_ 614 14;
BA_ "VFrameFormat" BO_ 610 14;
BA_ "VFrameFormat" BO_ 615 14;
BA_ "VFrameFormat" BO_ 636 14;
BA_ "VFrameFormat" BO_ 631 14;
BA_ "VFrameFormat" BO_ 637 14;
BA_ "VFrameFormat" BO_ 632 14;
BA_ "VFrameFormat" BO_ 692 14;
BA_ "VFrameFormat" BO_ 633 14;
BA_ "VFrameFormat" BO_ 634 14;
BA_ "VFrameFormat" BO_ 630 14;
BA_ "VFrameFormat" BO_ 635 14;
BA_ "VFrameFormat" BO_ 336 14;
BA_ "VFrameFormat" BO_ 331 14;
BA_ "VFrameFormat" BO_ 337 14;
